VERSION ""

NS_ :

BS_:

BU_: WPC2 RLPSU DPSU PSB SHVU_RR APSU FCS EMCU SLB RCM ARS CGW_CCU ATS RLHV SGU PFSU ALBCU DSAU SWRC SHVU_FR RCS RRPSU BLTN_CAM SCM DLBCU OHCL RWPC RRHV WPC HOD ASAU

BO_ 799 SBCM_DRV_01_200ms: 8 CGW_CCU
 SG_ SBCM_DRV_Crc1Val : 0|8@1+ (1,0) [0|0] ""  Vector__XXX
 SG_ DRV_CrashUnlockCmd : 10|1@1+ (1,0) [0|0] ""  BLTN_CAM
 SG_ C_ApprOpenStatus : 11|1@1+ (1,0) [0|0] ""  Vector__XXX
 SG_ SBCM_DRV_AlvCnt1Val : 12|4@1+ (1,0) [0|0] ""  Vector__XXX
 SG_ DoorLock_DrvKeyLkSwSta_SBCM : 16|2@1+ (1,0) [0|0] ""  Vector__XXX
 SG_ DoorLock_DrvKeyUnLkSwSta_SBCM : 18|2@1+ (1,0) [0|0] ""  Vector__XXX
 SG_ Warn_DrvDrSwSta_SBCM : 20|2@1+ (1,0) [0|0] ""  WPC,RWPC,DPSU,ATS,BLTN_CAM,WPC2
 SG_ DoorLock_DrvDrUnLkSta_SBCM : 22|2@1+ (1,0) [0|0] ""  DPSU,ATS
 SG_ DRV_SEAWarn_LH : 24|2@1+ (1,0) [0|0] ""  Vector__XXX
 SG_ DRV_SEAWarn_RH : 26|2@1+ (1,0) [0|0] ""  Vector__XXX
 SG_ DRV_SEWWarn_LH : 28|2@1+ (1,0) [0|0] ""  Vector__XXX
 SG_ DRV_SEWWarn_RH : 30|2@1+ (1,0) [0|0] ""  Vector__XXX
 SG_ DRV_MRActivationAlarm : 32|2@1+ (1,0) [0|0] ""  Vector__XXX
 SG_ DRV_ReleaseWarn : 34|2@1+ (1,0) [0|0] ""  Vector__XXX
 SG_ Latch_TypeOption_DRV : 36|2@1+ (1,0) [0|0] ""  Vector__XXX
 SG_ DRV_SWFailAlarm : 38|2@1+ (1,0) [0|0] ""  Vector__XXX
 SG_ USM_PwrDRApprOpnSetSta : 40|2@1+ (1,0) [0|0] ""  Vector__XXX
 SG_ USM_PwrDRApprOpnSetOpt : 42|2@1+ (1,0) [0|0] ""  Vector__XXX
 SG_ USM_PwrDRCloseByRKELockSta : 44|2@1+ (1,0) [0|0] ""  Vector__XXX
 SG_ USM_PwrDRCloseByRKELockOpt : 46|2@1+ (1,0) [0|0] ""  Vector__XXX
 SG_ USM_PwrDRCloseByBrakeSta : 48|2@1+ (1,0) [0|0] ""  Vector__XXX
 SG_ USM_PwrDRCloseByBrakeOpt : 50|2@1+ (1,0) [0|0] ""  Vector__XXX
 SG_ USM_PwrDRBuzzerSta : 52|2@1+ (1,0) [0|0] ""  Vector__XXX
 SG_ USM_PwrDRBuzzerOpt : 54|2@1+ (1,0) [0|0] ""  Vector__XXX
 SG_ PDS_TypeOption_DRV : 56|2@1+ (1,0) [0|0] ""  Vector__XXX
 SG_ C_DrvDoorApproachOpen : 58|2@1+ (1,0) [0|0] ""  Vector__XXX
 SG_ C_DrvDoorApproachClose : 60|2@1+ (1,0) [0|0] ""  Vector__XXX
 SG_ DoorLock_PDSLkSwSta_DRV : 62|2@1+ (1,0) [0|0] ""  Vector__XXX
 SG_ DRVDoorPushAlarm : 8|2@1+ (1,0) [0|0] ""  Vector__XXX

BO_ 858 SBCM_AST_02_200ms: 8 CGW_CCU
 SG_ SBCM_AST_Crc2Val : 0|8@1+ (1,0) [0|0] ""  Vector__XXX
 SG_ AST_CrashUnlockCmd : 10|1@1+ (1,0) [0|0] ""  BLTN_CAM
 SG_ SBCM_AST_AlvCnt2Val : 12|4@1+ (1,0) [0|0] ""  Vector__XXX
 SG_ DoorLock_CtrlDrLkSwSta_SBCM : 16|2@1+ (1,0) [0|0] ""  Vector__XXX
 SG_ DoorLock_CtrlDrUnLkSwSta_SBCM : 18|2@1+ (1,0) [0|0] ""  Vector__XXX
 SG_ Warn_AsstDrSwSta_SBCM : 20|2@1+ (1,0) [0|0] ""  WPC,RWPC,APSU,ATS,BLTN_CAM,ALBCU,WPC2
 SG_ DoorLock_AsstDrUnLkSta_SBCM : 22|2@1+ (1,0) [0|0] ""  ATS
 SG_ AST_SEAWarn_RH : 24|2@1+ (1,0) [0|0] ""  Vector__XXX
 SG_ AST_SEAWarn_LH : 26|2@1+ (1,0) [0|0] ""  Vector__XXX
 SG_ AST_SEWWarn_LH : 28|2@1+ (1,0) [0|0] ""  Vector__XXX
 SG_ AST_SEWWarn_RH : 30|2@1+ (1,0) [0|0] ""  Vector__XXX
 SG_ AST_MRActivationAlarm : 32|2@1+ (1,0) [0|0] ""  Vector__XXX
 SG_ AST_ReleaseWarn : 34|2@1+ (1,0) [0|0] ""  Vector__XXX
 SG_ USM_AstGhostDoorSta : 36|2@1+ (1,0) [0|0] ""  Vector__XXX
 SG_ AST_SWFailAlarm : 38|2@1+ (1,0) [0|0] ""  Vector__XXX
 SG_ DoorLock_PDSLkSwSta_AST : 40|2@1+ (1,0) [0|0] ""  Vector__XXX
 SG_ PDS_TypeOption_AST : 42|2@1+ (1,0) [0|0] ""  Vector__XXX
 SG_ AFCU_AutoWashModeSta_SBCM_AST : 56|3@1+ (1,0) [0|0] ""  Vector__XXX
 SG_ CDM_AutoWashModeSta_SBCM_AST : 59|3@1+ (1,0) [0|0] ""  Vector__XXX
 SG_ ASTDoorPushAlarm : 8|2@1+ (1,0) [0|0] ""  Vector__XXX

BO_ 1193 HU_USM_E_02: 8 CGW_CCU
 SG_ C_PTGMNValueSet : 0|2@1+ (1,0) [0|0] ""  Vector__XXX
 SG_ CF_AVN_PSMNValueSet : 10|3@1+ (1,0) [0|0] ""  DPSU
 SG_ C_HfreeTrunkTgNValueSet : 13|3@1+ (1,0) [0|0] ""  Vector__XXX
 SG_ CF_AVN_TrfChgSet : 17|2@1+ (1,0) [0|0] ""  Vector__XXX
 SG_ CF_AVN_SCMNValueSet : 19|2@1+ (1,0) [0|0] ""  Vector__XXX
 SG_ CF_AVN_ADrUNValueSet : 2|3@1+ (1,0) [0|0] ""  Vector__XXX
 SG_ CF_AVN_OTTurnNValueSet : 21|3@1+ (1,0) [0|0] ""  Vector__XXX
 SG_ CF_Gway_WPCNValueSet : 24|2@1+ (1,0) [0|0] ""  WPC,WPC2
 SG_ C_AVN_RearWiperNValueSet : 26|2@1+ (1,0) [0|0] ""  Vector__XXX
 SG_ C_UnlockWelocomeNValueSet : 28|2@1+ (1,0) [0|0] ""  Vector__XXX
 SG_ C_SmartWelocomeNValueSet : 30|2@1+ (1,0) [0|0] ""  Vector__XXX
 SG_ CF_AVN_PTGSpeedNValueSet : 32|2@1+ (1,0) [0|0] ""  Vector__XXX
 SG_ CR_Datc_DRSeatWheel_USM_Set : 34|2@1+ (1,0) [0|0] ""  Vector__XXX
 SG_ CF_AVN_TTUnlockNValueSet : 38|2@1+ (1,0) [0|0] ""  Vector__XXX
 SG_ CF_Gway_RWPCNValueSet : 40|2@1+ (1,0) [0|0] ""  RWPC
 SG_ CF_Avn_HAPTICWARNINGNValueSet : 49|3@1+ (1,0) [0|0] ""  Vector__XXX
 SG_ CR_Datc_DRSeatHeat_USM_Set : 52|2@1+ (1,0) [0|0] ""  Vector__XXX
 SG_ C_WALNValueSet : 54|2@1+ (1,0) [0|0] ""  Vector__XXX
 SG_ C_ApprUnlockNValue : 56|2@1+ (1,0) [0|0] ""  Vector__XXX
 SG_ CF_AVN_EscortHLNValueSet : 8|2@1+ (1,0) [0|0] ""  Vector__XXX

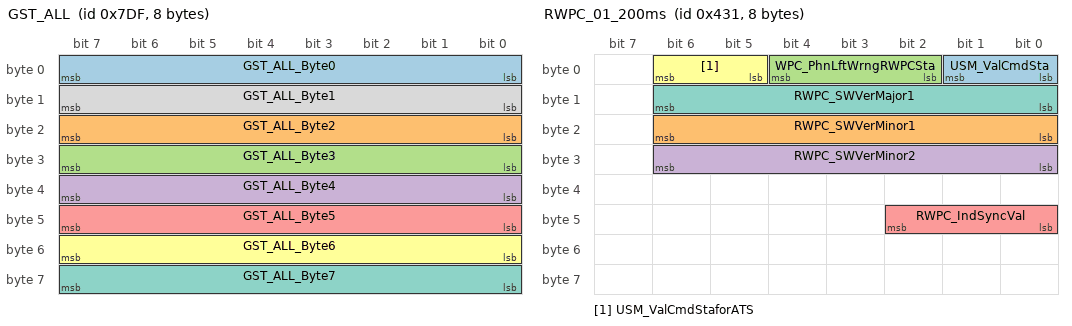
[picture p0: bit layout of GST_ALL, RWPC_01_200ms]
BO_ 2015 GST_ALL: 8 CGW_CCU
 SG_ GST_ALL_Byte0 : 0|8@1+ (1,0) [0|0] ""  FCS,SCM,WPC,RWPC,PSB,SLB,ARS,SWRC,APSU,RLHV,RRHV,SHVU_FR,SHVU_RR,DPSU,DLBCU,PFSU,RCS,RRPSU,RLPSU,HOD,ATS,DSAU,ASAU,RCM,EMCU,SGU,ALBCU,WPC2
 SG_ GST_ALL_Byte2 : 16|8@1+ (1,0) [0|0] ""  FCS,SCM,WPC,RWPC,PSB,SLB,ARS,SWRC,APSU,RLHV,RRHV,SHVU_FR,SHVU_RR,DPSU,DLBCU,PFSU,RCS,RRPSU,RLPSU,HOD,ATS,DSAU,ASAU,RCM,EMCU,SGU,ALBCU,WPC2
 SG_ GST_ALL_Byte3 : 24|8@1+ (1,0) [0|0] ""  FCS,SCM,WPC,RWPC,PSB,SLB,ARS,SWRC,APSU,RLHV,RRHV,SHVU_FR,SHVU_RR,DPSU,DLBCU,PFSU,RCS,RRPSU,RLPSU,HOD,ATS,DSAU,ASAU,RCM,EMCU,SGU,ALBCU,WPC2
 SG_ GST_ALL_Byte4 : 32|8@1+ (1,0) [0|0] ""  FCS,SCM,WPC,RWPC,PSB,SLB,ARS,SWRC,APSU,RLHV,RRHV,SHVU_FR,SHVU_RR,DPSU,DLBCU,PFSU,RCS,RRPSU,RLPSU,HOD,ATS,DSAU,ASAU,RCM,EMCU,SGU,ALBCU,WPC2
 SG_ GST_ALL_Byte5 : 40|8@1+ (1,0) [0|0] ""  FCS,SCM,WPC,RWPC,PSB,SLB,ARS,SWRC,APSU,RLHV,RRHV,SHVU_FR,SHVU_RR,DPSU,DLBCU,PFSU,RCS,RRPSU,RLPSU,HOD,ATS,DSAU,ASAU,RCM,EMCU,SGU,ALBCU,WPC2
 SG_ GST_ALL_Byte6 : 48|8@1+ (1,0) [0|0] ""  FCS,SCM,WPC,RWPC,PSB,SLB,ARS,SWRC,APSU,RLHV,RRHV,SHVU_FR,SHVU_RR,DPSU,DLBCU,PFSU,RCS,RRPSU,RLPSU,HOD,ATS,DSAU,ASAU,RCM,EMCU,SGU,ALBCU,WPC2
 SG_ GST_ALL_Byte7 : 56|8@1+ (1,0) [0|0] ""  FCS,SCM,WPC,RWPC,PSB,SLB,ARS,SWRC,APSU,RLHV,RRHV,SHVU_FR,SHVU_RR,DPSU,DLBCU,PFSU,RCS,RRPSU,RLPSU,HOD,ATS,DSAU,ASAU,RCM,EMCU,SGU,ALBCU,WPC2
 SG_ GST_ALL_Byte1 : 8|8@1+ (1,0) [0|0] ""  FCS,SCM,WPC,RWPC,PSB,SLB,ARS,SWRC,APSU,RLHV,RRHV,SHVU_FR,SHVU_RR,DPSU,DLBCU,PFSU,RCS,RRPSU,RLPSU,HOD,ATS,DSAU,ASAU,RCM,EMCU,SGU,ALBCU,WPC2

BO_ 862 SBCM_RL_01_200ms: 8 CGW_CCU
 SG_ SBCM_RL_Crc1Val : 0|8@1+ (1,0) [0|0] ""  Vector__XXX
 SG_ RL_CrashUnlockCmd : 10|1@1+ (1,0) [0|0] ""  BLTN_CAM
 SG_ SBCM_RL_AlvCnt1Val : 12|4@1+ (1,0) [0|0] ""  Vector__XXX
 SG_ Warn_RrLftDrSwSta_SBCM : 16|2@1+ (1,0) [0|0] ""  WPC,RWPC,APSU,ATS,BLTN_CAM,WPC2
 SG_ DoorLock_RrLftDrUnLkSta_SBCM : 18|2@1+ (1,0) [0|0] ""  ATS
 SG_ RL_SEAActivated : 20|2@1+ (1,0) [0|0] ""  Vector__XXX
 SG_ RL_SEAWarn : 22|2@1+ (1,0) [0|0] ""  Vector__XXX
 SG_ RL_SEWWarn : 24|2@1+ (1,0) [0|0] ""  Vector__XXX
 SG_ RL_ReleaseWarn : 26|2@1+ (1,0) [0|0] ""  Vector__XXX
 SG_ RL_SWFailAlarm : 28|2@1+ (1,0) [0|0] ""  Vector__XXX
 SG_ RL_ChildLock_ActnFlSta : 30|2@1+ (1,0) [0|0] ""  Vector__XXX
 SG_ RL_MRActivationAlarm : 32|2@1+ (1,0) [0|0] ""  Vector__XXX
 SG_ RL_ChildLock_Status : 34|2@1+ (1,0) [0|0] ""  Vector__XXX
 SG_ USM_RLGhostDoorSta : 36|2@1+ (1,0) [0|0] ""  Vector__XXX
 SG_ DoorLock_PDSLkSwSta_RL : 40|2@1+ (1,0) [0|0] ""  Vector__XXX
 SG_ PDS_TypeOption_RL : 42|2@1+ (1,0) [0|0] ""  Vector__XXX
 SG_ RLDoorPushAlarm : 8|2@1+ (1,0) [0|0] ""  Vector__XXX

BO_ 491 HU_USM_E_14: 8 CGW_CCU
 SG_ CF_AVN_Roof_OprLvSet : 0|3@1+ (1,0) [0|0] ""  SGU
 SG_ CF_AVN_3rdRightDoor_OptLvlSet : 12|3@1+ (1,0) [0|0] ""  SGU
 SG_ CF_AVN_RearDoor_OptLvlSet : 15|3@1+ (1,0) [0|0] ""  SGU
 SG_ CF_AVN_RollBlindOnOffSet : 18|2@1+ (1,0) [0|0] ""  SGU
 SG_ CF_AVN_CluThmAutoSet_New : 20|2@1+ (1,0) [0|0] ""  Vector__XXX
 SG_ CF_AVN_CluThmSet_New : 22|3@1+ (1,0) [0|0] ""  Vector__XXX
 SG_ CF_AVN_CluThmDtlSet_New : 25|3@1+ (1,0) [0|0] ""  Vector__XXX
 SG_ CF_AVN_MdLmpAIVoiceUSMNValueSet : 28|2@1+ (1,0) [0|0] ""  Vector__XXX
 SG_ CF_AVN_2ndLeftDoor_OptLvSet : 3|3@1+ (1,0) [0|0] ""  SGU
 SG_ CF_AVN_DWL_SelectNvalueSet : 30|4@1+ (1,0) [0|0] ""  Vector__XXX
 SG_ CF_AVN_FrArmRestHeatNValueSet : 36|2@1+ (1,0) [0|0] ""  FCS
 SG_ CF_AVN_RrArmRestHeatNValueSet : 38|2@1+ (1,0) [0|0] ""  FCS
 SG_ CF_Gway_WPCAnimationNvalueSet : 40|3@1+ (1,0) [0|0] ""  WPC
 SG_ USM_BtnIllumiAlwaysOnReq : 49|2@1+ (1,0) [0|0] ""  Vector__XXX
 SG_ CF_AVN_LKAWrngVolNvalueSet : 51|2@1+ (1,0) [0|0] ""  Vector__XXX
 SG_ DAB_IlluminationVrModeSet : 53|3@1+ (1,0) [0|0] ""  SWRC
 SG_ USM_IllAlwaysOnwithPSTNReq : 56|3@1+ (1,0) [0|0] ""  Vector__XXX
 SG_ CF_AVN_AutoStopTimerResetSet : 59|3@1+ (1,0) [0|0] ""  Vector__XXX
 SG_ CF_AVN_2ndRightDoor_OptLvSet : 6|3@1+ (1,0) [0|0] ""  SGU
 SG_ USM_RrCurtainSet : 62|2@1+ (1,0) [0|0] ""  Vector__XXX
 SG_ CF_AVN_3rdLeftDoor_OptLvlSet : 9|3@1+ (1,0) [0|0] ""  SGU

BO_ 905 SBCM_RR_01_200ms: 8 CGW_CCU
 SG_ SBCM_RR_Crc1Val : 0|8@1+ (1,0) [0|0] ""  Vector__XXX
 SG_ RR_CrashUnlockCmd : 10|1@1+ (1,0) [0|0] ""  BLTN_CAM
 SG_ SBCM_RR_AlvCnt1Val : 12|4@1+ (1,0) [0|0] ""  Vector__XXX
 SG_ Warn_RrRtDrSwSta_SBCM : 16|2@1+ (1,0) [0|0] ""  WPC,RWPC,APSU,RRPSU,ATS,BLTN_CAM,WPC2
 SG_ DoorLock_RrRtDrUnLkSta_SBCM : 18|2@1+ (1,0) [0|0] ""  ATS
 SG_ RR_SEAActivated : 20|2@1+ (1,0) [0|0] ""  Vector__XXX
 SG_ RR_SEAWarn : 22|2@1+ (1,0) [0|0] ""  Vector__XXX
 SG_ RR_SEWWarn : 24|2@1+ (1,0) [0|0] ""  Vector__XXX
 SG_ RR_ReleaseWarn : 26|2@1+ (1,0) [0|0] ""  Vector__XXX
 SG_ RR_SWFailAlarm : 28|2@1+ (1,0) [0|0] ""  Vector__XXX
 SG_ RR_ChildLock_ActnFlSta : 30|2@1+ (1,0) [0|0] ""  Vector__XXX
 SG_ RR_MRActivationAlarm : 32|2@1+ (1,0) [0|0] ""  Vector__XXX
 SG_ RR_ChildLock_Status : 34|2@1+ (1,0) [0|0] ""  Vector__XXX
 SG_ USM_RRGhostDoorSta : 36|2@1+ (1,0) [0|0] ""  Vector__XXX
 SG_ DoorLock_PDSLkSwSta_RR : 40|2@1+ (1,0) [0|0] ""  Vector__XXX
 SG_ PDS_TypeOption_RR : 42|2@1+ (1,0) [0|0] ""  Vector__XXX
 SG_ RRDoorPushAlarm : 8|2@1+ (1,0) [0|0] ""  Vector__XXX

BO_ 1073 RWPC_01_200ms: 8 RWPC
 SG_ USM_ValCmdSta : 0|2@1+ (1,0) [0|0] ""  ATS,CGW_CCU
 SG_ RWPC_SWVerMinor1 : 16|7@1+ (1,0) [0|0] ""  CGW_CCU
 SG_ WPC_PhnLftWrngRWPCSta : 2|3@1+ (1,0) [0|0] ""  ATS,CGW_CCU
 SG_ RWPC_SWVerMinor2 : 24|7@1+ (1,0) [0|0] ""  CGW_CCU
 SG_ RWPC_IndSyncVal : 40|3@1+ (1,0) [0|0] ""  WPC,WPC2
 SG_ USM_ValCmdStaforATS : 5|2@1+ (1,0) [0|0] ""  ATS
 SG_ RWPC_SWVerMajor1 : 8|7@1+ (1,0) [0|0] ""  CGW_CCU

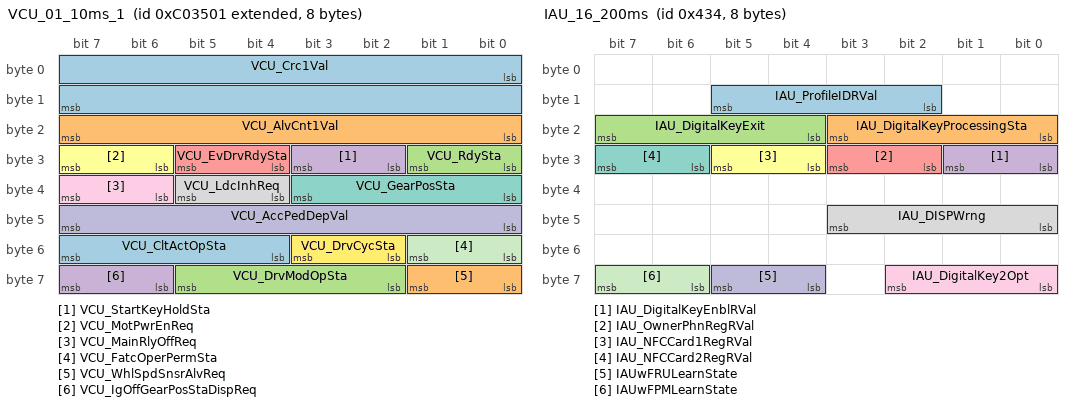
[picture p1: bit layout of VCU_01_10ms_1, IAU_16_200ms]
BO_ 2160080129 VCU_01_10ms_1: 8 CGW_CCU
 SG_ VCU_Crc1Val : 0|16@1+ (1,0) [0|0] ""  Vector__XXX
 SG_ VCU_AlvCnt1Val : 16|8@1+ (1,0) [0|0] ""  Vector__XXX
 SG_ VCU_RdySta : 24|2@1+ (1,0) [0|3] ""  Vector__XXX
 SG_ VCU_StartKeyHoldSta : 26|2@1+ (1,0) [0|3] ""  Vector__XXX
 SG_ VCU_EvDrvRdySta : 28|2@1+ (1,0) [0|3] ""  SCM,WPC,RWPC,SWRC,APSU,RLHV,RRHV,SHVU_FR,SHVU_RR,DPSU,DLBCU,PFSU,RRPSU,RLPSU,HOD,RCM,BLTN_CAM,WPC2
 SG_ VCU_MotPwrEnReq : 30|2@1+ (1,0) [0|3] ""  Vector__XXX
 SG_ VCU_GearPosSta : 32|4@1+ (1,0) [0|15] ""  APSU,DPSU,PFSU,RRPSU,RLPSU,BLTN_CAM,SGU,WPC2
 SG_ VCU_LdcInhReq : 36|2@1+ (1,0) [0|3] ""  Vector__XXX
 SG_ VCU_MainRlyOffReq : 38|2@1+ (1,0) [0|3] ""  Vector__XXX
 SG_ VCU_AccPedDepVal : 40|8@1+ (0.3921568627,0) [0|100] "%"  BLTN_CAM
 SG_ VCU_FatcOperPermSta : 48|2@1+ (1,0) [0|3] ""  Vector__XXX
 SG_ VCU_DrvCycSta : 50|2@1+ (1,0) [0|3] ""  Vector__XXX
 SG_ VCU_CltActOpSta : 52|4@1+ (1,0) [0|15] ""  Vector__XXX
 SG_ VCU_WhlSpdSnsrAlvReq : 56|2@1+ (1,0) [0|0] "flag"  Vector__XXX
 SG_ VCU_DrvModOpSta : 58|4@1+ (1,0) [0|0] ""  Vector__XXX
 SG_ VCU_IgOffGearPosStaDispReq : 62|2@1+ (1,0) [0|0] "flag"  Vector__XXX

BO_ 1076 IAU_16_200ms: 8 CGW_CCU
 SG_ IAU_ProfileIDRVal : 10|4@1+ (1,0) [0|0] ""  WPC,RWPC,DPSU,DLBCU,RCM,BLTN_CAM,SGU,WPC2
 SG_ IAU_DigitalKeyProcessingSta : 16|4@1+ (1,0) [0|0] ""  Vector__XXX
 SG_ IAU_DigitalKeyExit : 20|4@1+ (1,0) [0|0] ""  Vector__XXX
 SG_ IAU_DigitalKeyEnblRVal : 24|2@1+ (1,0) [0|0] ""  Vector__XXX
 SG_ IAU_OwnerPhnRegRVal : 26|2@1+ (1,0) [0|0] ""  Vector__XXX
 SG_ IAU_NFCCard1RegRVal : 28|2@1+ (1,0) [0|0] ""  Vector__XXX
 SG_ IAU_NFCCard2RegRVal : 30|2@1+ (1,0) [0|0] ""  Vector__XXX
 SG_ IAU_DISPWrng : 40|4@1+ (1,0) [0|0] ""  Vector__XXX
 SG_ IAU_DigitalKey2Opt : 56|3@1+ (1,0) [0|0] ""  WPC,WPC2
 SG_ IAUwFRULearnState : 60|2@1+ (1,0) [0|0] ""  Vector__XXX
 SG_ IAUwFPMLearnState : 62|2@1+ (1,0) [0|0] ""  Vector__XXX

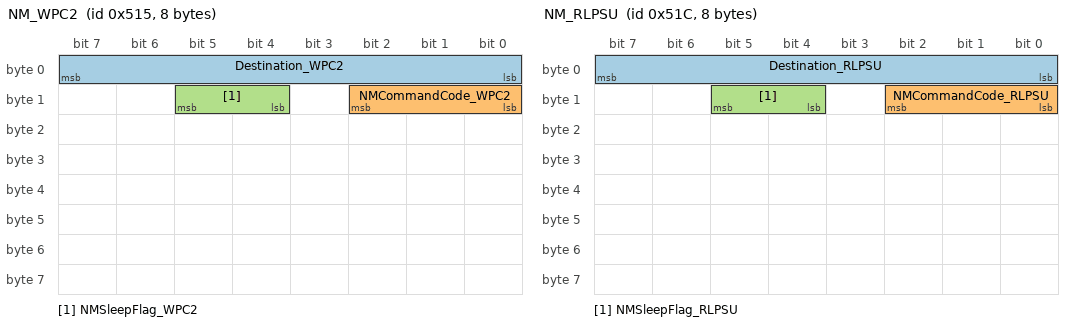
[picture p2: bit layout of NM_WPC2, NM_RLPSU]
BO_ 1301 NM_WPC2: 8 WPC2
 SG_ Destination_WPC2 : 0|8@1+ (1,0) [0|0] ""  RLPSU,DPSU,PSB,SHVU_RR,APSU,FCS,EMCU,SLB,RCM,ARS,CGW_CCU,ATS,RLHV,SGU,PFSU,ALBCU,DSAU,SWRC,SHVU_FR,RCS,RRPSU,BLTN_CAM,SCM,DLBCU,OHCL,RWPC,RRHV,WPC,HOD,ASAU
 SG_ NMCommandCode_WPC2 : 8|3@1+ (1,0) [0|0] ""  RLPSU,DPSU,PSB,SHVU_RR,APSU,FCS,EMCU,SLB,RCM,ARS,CGW_CCU,ATS,RLHV,SGU,PFSU,ALBCU,DSAU,SWRC,SHVU_FR,RCS,RRPSU,BLTN_CAM,SCM,DLBCU,OHCL,RWPC,RRHV,WPC,HOD,ASAU
 SG_ NMSleepFlag_WPC2 : 12|2@1+ (1,0) [0|0] ""  RLPSU,DPSU,PSB,SHVU_RR,APSU,FCS,EMCU,SLB,RCM,ARS,CGW_CCU,ATS,RLHV,SGU,PFSU,ALBCU,DSAU,SWRC,SHVU_FR,RCS,RRPSU,BLTN_CAM,SCM,DLBCU,OHCL,RWPC,RRHV,WPC,HOD,ASAU

BO_ 1308 NM_RLPSU: 8 RLPSU
 SG_ Destination_RLPSU : 0|8@1+ (1,0) [0|0] ""  WPC2,DPSU,PSB,SHVU_RR,APSU,FCS,EMCU,SLB,RCM,ARS,CGW_CCU,ATS,RLHV,SGU,PFSU,ALBCU,DSAU,SWRC,SHVU_FR,RCS,RRPSU,BLTN_CAM,SCM,DLBCU,OHCL,RWPC,RRHV,WPC,HOD,ASAU
 SG_ NMCommandCode_RLPSU : 8|3@1+ (1,0) [0|0] ""  WPC2,DPSU,PSB,SHVU_RR,APSU,FCS,EMCU,SLB,RCM,ARS,CGW_CCU,ATS,RLHV,SGU,PFSU,ALBCU,DSAU,SWRC,SHVU_FR,RCS,RRPSU,BLTN_CAM,SCM,DLBCU,OHCL,RWPC,RRHV,WPC,HOD,ASAU
 SG_ NMSleepFlag_RLPSU : 12|2@1+ (1,0) [0|0] ""  WPC2,DPSU,PSB,SHVU_RR,APSU,FCS,EMCU,SLB,RCM,ARS,CGW_CCU,ATS,RLHV,SGU,PFSU,ALBCU,DSAU,SWRC,SHVU_FR,RCS,RRPSU,BLTN_CAM,SCM,DLBCU,OHCL,RWPC,RRHV,WPC,HOD,ASAU

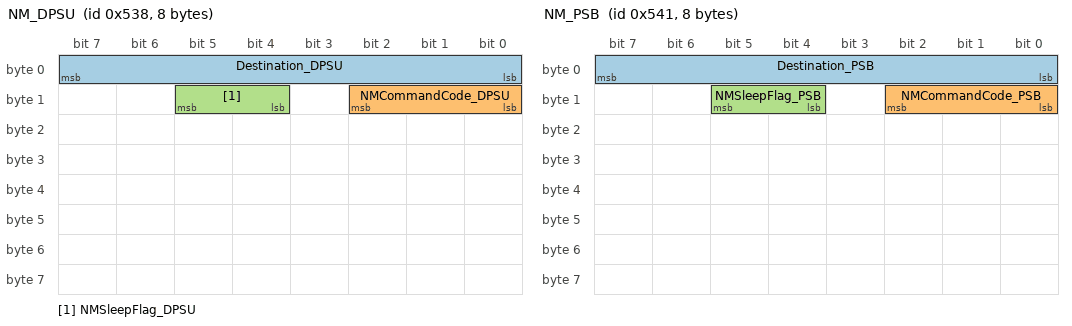
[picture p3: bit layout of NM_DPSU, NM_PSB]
BO_ 1336 NM_DPSU: 8 DPSU
 SG_ Destination_DPSU : 0|8@1+ (1,0) [0|0] ""  WPC2,RLPSU,PSB,SHVU_RR,APSU,FCS,EMCU,SLB,RCM,ARS,CGW_CCU,ATS,RLHV,SGU,PFSU,ALBCU,DSAU,SWRC,SHVU_FR,RCS,RRPSU,BLTN_CAM,SCM,DLBCU,OHCL,RWPC,RRHV,WPC,HOD,ASAU
 SG_ NMCommandCode_DPSU : 8|3@1+ (1,0) [0|0] ""  WPC2,RLPSU,PSB,SHVU_RR,APSU,FCS,EMCU,SLB,RCM,ARS,CGW_CCU,ATS,RLHV,SGU,PFSU,ALBCU,DSAU,SWRC,SHVU_FR,RCS,RRPSU,BLTN_CAM,SCM,DLBCU,OHCL,RWPC,RRHV,WPC,HOD,ASAU
 SG_ NMSleepFlag_DPSU : 12|2@1+ (1,0) [0|0] ""  WPC2,RLPSU,PSB,SHVU_RR,APSU,FCS,EMCU,SLB,RCM,ARS,CGW_CCU,ATS,RLHV,SGU,PFSU,ALBCU,DSAU,SWRC,SHVU_FR,RCS,RRPSU,BLTN_CAM,SCM,DLBCU,OHCL,RWPC,RRHV,WPC,HOD,ASAU

BO_ 1345 NM_PSB: 8 PSB
 SG_ Destination_PSB : 0|8@1+ (1,0) [0|0] ""  WPC2,RLPSU,DPSU,SHVU_RR,APSU,FCS,EMCU,SLB,RCM,ARS,CGW_CCU,ATS,RLHV,SGU,PFSU,ALBCU,DSAU,SWRC,SHVU_FR,RCS,RRPSU,BLTN_CAM,SCM,DLBCU,OHCL,RWPC,RRHV,WPC,HOD,ASAU
 SG_ NMCommandCode_PSB : 8|3@1+ (1,0) [0|0] ""  WPC2,RLPSU,DPSU,SHVU_RR,APSU,FCS,EMCU,SLB,RCM,ARS,CGW_CCU,ATS,RLHV,SGU,PFSU,ALBCU,DSAU,SWRC,SHVU_FR,RCS,RRPSU,BLTN_CAM,SCM,DLBCU,OHCL,RWPC,RRHV,WPC,HOD,ASAU
 SG_ NMSleepFlag_PSB : 12|2@1+ (1,0) [0|0] ""  WPC2,RLPSU,DPSU,SHVU_RR,APSU,FCS,EMCU,SLB,RCM,ARS,CGW_CCU,ATS,RLHV,SGU,PFSU,ALBCU,DSAU,SWRC,SHVU_FR,RCS,RRPSU,BLTN_CAM,SCM,DLBCU,OHCL,RWPC,RRHV,WPC,HOD,ASAU

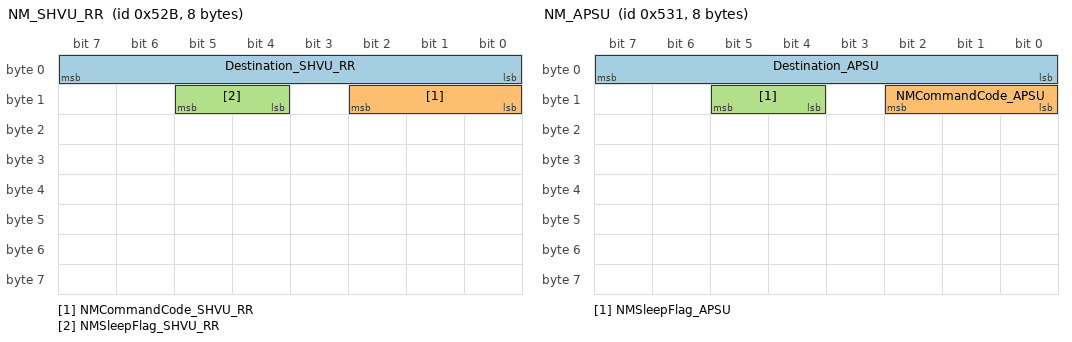
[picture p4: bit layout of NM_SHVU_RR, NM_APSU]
BO_ 1323 NM_SHVU_RR: 8 SHVU_RR
 SG_ Destination_SHVU_RR : 0|8@1+ (1,0) [0|0] ""  WPC2,RLPSU,DPSU,PSB,APSU,FCS,EMCU,SLB,RCM,ARS,CGW_CCU,ATS,RLHV,SGU,PFSU,ALBCU,DSAU,SWRC,SHVU_FR,RCS,RRPSU,BLTN_CAM,SCM,DLBCU,OHCL,RWPC,RRHV,WPC,HOD,ASAU
 SG_ NMCommandCode_SHVU_RR : 8|3@1+ (1,0) [0|0] ""  WPC2,RLPSU,DPSU,PSB,APSU,FCS,EMCU,SLB,RCM,ARS,CGW_CCU,ATS,RLHV,SGU,PFSU,ALBCU,DSAU,SWRC,SHVU_FR,RCS,RRPSU,BLTN_CAM,SCM,DLBCU,OHCL,RWPC,RRHV,WPC,HOD,ASAU
 SG_ NMSleepFlag_SHVU_RR : 12|2@1+ (1,0) [0|0] ""  WPC2,RLPSU,DPSU,PSB,APSU,FCS,EMCU,SLB,RCM,ARS,CGW_CCU,ATS,RLHV,SGU,PFSU,ALBCU,DSAU,SWRC,SHVU_FR,RCS,RRPSU,BLTN_CAM,SCM,DLBCU,OHCL,RWPC,RRHV,WPC,HOD,ASAU

BO_ 1329 NM_APSU: 8 APSU
 SG_ Destination_APSU : 0|8@1+ (1,0) [0|0] ""  WPC2,RLPSU,DPSU,PSB,SHVU_RR,FCS,EMCU,SLB,RCM,ARS,CGW_CCU,ATS,RLHV,SGU,PFSU,ALBCU,DSAU,SWRC,SHVU_FR,RCS,RRPSU,BLTN_CAM,SCM,DLBCU,OHCL,RWPC,RRHV,WPC,HOD,ASAU
 SG_ NMCommandCode_APSU : 8|3@1+ (1,0) [0|0] ""  WPC2,RLPSU,DPSU,PSB,SHVU_RR,FCS,EMCU,SLB,RCM,ARS,CGW_CCU,ATS,RLHV,SGU,PFSU,ALBCU,DSAU,SWRC,SHVU_FR,RCS,RRPSU,BLTN_CAM,SCM,DLBCU,OHCL,RWPC,RRHV,WPC,HOD,ASAU
 SG_ NMSleepFlag_APSU : 12|2@1+ (1,0) [0|0] ""  WPC2,RLPSU,DPSU,PSB,SHVU_RR,FCS,EMCU,SLB,RCM,ARS,CGW_CCU,ATS,RLHV,SGU,PFSU,ALBCU,DSAU,SWRC,SHVU_FR,RCS,RRPSU,BLTN_CAM,SCM,DLBCU,OHCL,RWPC,RRHV,WPC,HOD,ASAU

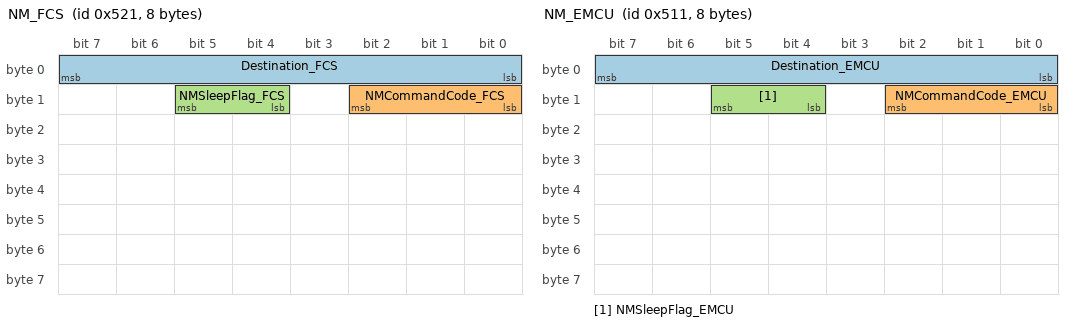
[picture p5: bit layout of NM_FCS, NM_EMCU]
BO_ 1313 NM_FCS: 8 FCS
 SG_ Destination_FCS : 0|8@1+ (1,0) [0|0] ""  WPC2,RLPSU,DPSU,PSB,SHVU_RR,APSU,EMCU,SLB,RCM,ARS,CGW_CCU,ATS,RLHV,SGU,PFSU,ALBCU,DSAU,SWRC,SHVU_FR,RCS,RRPSU,BLTN_CAM,SCM,DLBCU,OHCL,RWPC,RRHV,WPC,HOD,ASAU
 SG_ NMCommandCode_FCS : 8|3@1+ (1,0) [0|0] ""  WPC2,RLPSU,DPSU,PSB,SHVU_RR,APSU,EMCU,SLB,RCM,ARS,CGW_CCU,ATS,RLHV,SGU,PFSU,ALBCU,DSAU,SWRC,SHVU_FR,RCS,RRPSU,BLTN_CAM,SCM,DLBCU,OHCL,RWPC,RRHV,WPC,HOD,ASAU
 SG_ NMSleepFlag_FCS : 12|2@1+ (1,0) [0|0] ""  WPC2,RLPSU,DPSU,PSB,SHVU_RR,APSU,EMCU,SLB,RCM,ARS,CGW_CCU,ATS,RLHV,SGU,PFSU,ALBCU,DSAU,SWRC,SHVU_FR,RCS,RRPSU,BLTN_CAM,SCM,DLBCU,OHCL,RWPC,RRHV,WPC,HOD,ASAU

BO_ 1297 NM_EMCU: 8 EMCU
 SG_ Destination_EMCU : 0|8@1+ (1,0) [0|0] ""  WPC2,RLPSU,DPSU,PSB,SHVU_RR,APSU,FCS,SLB,RCM,ARS,CGW_CCU,ATS,RLHV,SGU,PFSU,ALBCU,DSAU,SWRC,SHVU_FR,RCS,RRPSU,BLTN_CAM,SCM,DLBCU,OHCL,RWPC,RRHV,WPC,HOD,ASAU
 SG_ NMCommandCode_EMCU : 8|3@1+ (1,0) [0|0] ""  WPC2,RLPSU,DPSU,PSB,SHVU_RR,APSU,FCS,SLB,RCM,ARS,CGW_CCU,ATS,RLHV,SGU,PFSU,ALBCU,DSAU,SWRC,SHVU_FR,RCS,RRPSU,BLTN_CAM,SCM,DLBCU,OHCL,RWPC,RRHV,WPC,HOD,ASAU
 SG_ NMSleepFlag_EMCU : 12|2@1+ (1,0) [0|0] ""  WPC2,RLPSU,DPSU,PSB,SHVU_RR,APSU,FCS,SLB,RCM,ARS,CGW_CCU,ATS,RLHV,SGU,PFSU,ALBCU,DSAU,SWRC,SHVU_FR,RCS,RRPSU,BLTN_CAM,SCM,DLBCU,OHCL,RWPC,RRHV,WPC,HOD,ASAU

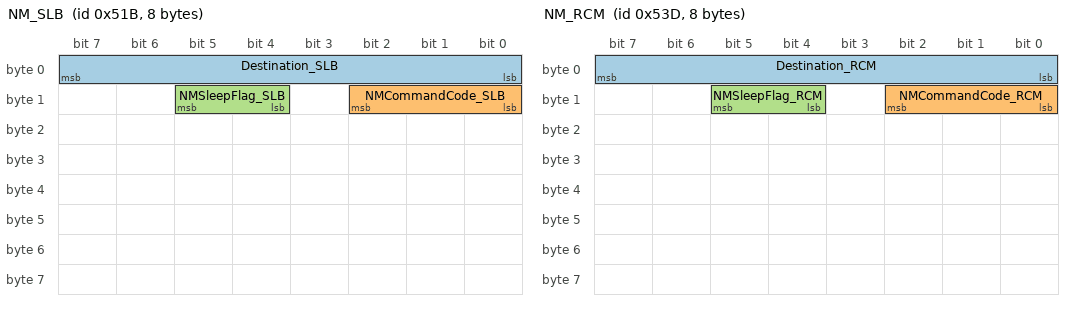
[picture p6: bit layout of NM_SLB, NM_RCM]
BO_ 1307 NM_SLB: 8 SLB
 SG_ Destination_SLB : 0|8@1+ (1,0) [0|0] ""  WPC2,RLPSU,DPSU,PSB,SHVU_RR,APSU,FCS,EMCU,RCM,ARS,CGW_CCU,ATS,RLHV,SGU,PFSU,ALBCU,DSAU,SWRC,SHVU_FR,RCS,RRPSU,BLTN_CAM,SCM,DLBCU,OHCL,RWPC,RRHV,WPC,HOD,ASAU
 SG_ NMCommandCode_SLB : 8|3@1+ (1,0) [0|0] ""  WPC2,RLPSU,DPSU,PSB,SHVU_RR,APSU,FCS,EMCU,RCM,ARS,CGW_CCU,ATS,RLHV,SGU,PFSU,ALBCU,DSAU,SWRC,SHVU_FR,RCS,RRPSU,BLTN_CAM,SCM,DLBCU,OHCL,RWPC,RRHV,WPC,HOD,ASAU
 SG_ NMSleepFlag_SLB : 12|2@1+ (1,0) [0|0] ""  WPC2,RLPSU,DPSU,PSB,SHVU_RR,APSU,FCS,EMCU,RCM,ARS,CGW_CCU,ATS,RLHV,SGU,PFSU,ALBCU,DSAU,SWRC,SHVU_FR,RCS,RRPSU,BLTN_CAM,SCM,DLBCU,OHCL,RWPC,RRHV,WPC,HOD,ASAU

BO_ 1341 NM_RCM: 8 RCM
 SG_ Destination_RCM : 0|8@1+ (1,0) [0|0] ""  WPC2,RLPSU,DPSU,PSB,SHVU_RR,APSU,FCS,EMCU,SLB,ARS,CGW_CCU,ATS,RLHV,SGU,PFSU,ALBCU,DSAU,SWRC,SHVU_FR,RCS,RRPSU,BLTN_CAM,SCM,DLBCU,OHCL,RWPC,RRHV,WPC,HOD,ASAU
 SG_ NMCommandCode_RCM : 8|3@1+ (1,0) [0|0] ""  WPC2,RLPSU,DPSU,PSB,SHVU_RR,APSU,FCS,EMCU,SLB,ARS,CGW_CCU,ATS,RLHV,SGU,PFSU,ALBCU,DSAU,SWRC,SHVU_FR,RCS,RRPSU,BLTN_CAM,SCM,DLBCU,OHCL,RWPC,RRHV,WPC,HOD,ASAU
 SG_ NMSleepFlag_RCM : 12|2@1+ (1,0) [0|0] ""  WPC2,RLPSU,DPSU,PSB,SHVU_RR,APSU,FCS,EMCU,SLB,ARS,CGW_CCU,ATS,RLHV,SGU,PFSU,ALBCU,DSAU,SWRC,SHVU_FR,RCS,RRPSU,BLTN_CAM,SCM,DLBCU,OHCL,RWPC,RRHV,WPC,HOD,ASAU

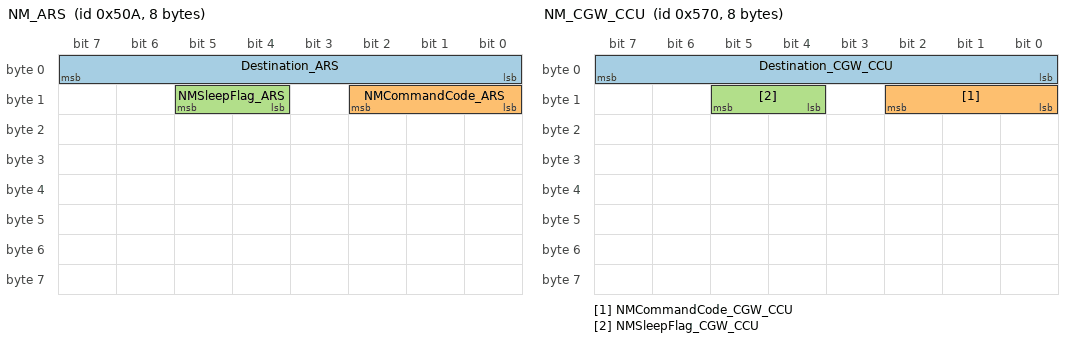
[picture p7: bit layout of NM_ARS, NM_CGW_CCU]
BO_ 1290 NM_ARS: 8 ARS
 SG_ Destination_ARS : 0|8@1+ (1,0) [0|0] ""  WPC2,RLPSU,DPSU,PSB,SHVU_RR,APSU,FCS,EMCU,SLB,RCM,CGW_CCU,ATS,RLHV,SGU,PFSU,ALBCU,DSAU,SWRC,SHVU_FR,RCS,RRPSU,BLTN_CAM,SCM,DLBCU,OHCL,RWPC,RRHV,WPC,HOD,ASAU
 SG_ NMCommandCode_ARS : 8|3@1+ (1,0) [0|0] ""  WPC2,RLPSU,DPSU,PSB,SHVU_RR,APSU,FCS,EMCU,SLB,RCM,CGW_CCU,ATS,RLHV,SGU,PFSU,ALBCU,DSAU,SWRC,SHVU_FR,RCS,RRPSU,BLTN_CAM,SCM,DLBCU,OHCL,RWPC,RRHV,WPC,HOD,ASAU
 SG_ NMSleepFlag_ARS : 12|2@1+ (1,0) [0|0] ""  WPC2,RLPSU,DPSU,PSB,SHVU_RR,APSU,FCS,EMCU,SLB,RCM,CGW_CCU,ATS,RLHV,SGU,PFSU,ALBCU,DSAU,SWRC,SHVU_FR,RCS,RRPSU,BLTN_CAM,SCM,DLBCU,OHCL,RWPC,RRHV,WPC,HOD,ASAU

BO_ 1392 NM_CGW_CCU: 8 CGW_CCU
 SG_ Destination_CGW_CCU : 0|8@1+ (1,0) [0|0] ""  WPC2,RLPSU,DPSU,PSB,SHVU_RR,APSU,FCS,EMCU,SLB,RCM,ARS,ATS,RLHV,SGU,PFSU,ALBCU,DSAU,SWRC,SHVU_FR,RCS,RRPSU,BLTN_CAM,SCM,DLBCU,OHCL,RWPC,RRHV,WPC,HOD,ASAU
 SG_ NMCommandCode_CGW_CCU : 8|3@1+ (1,0) [0|0] ""  WPC2,RLPSU,DPSU,PSB,SHVU_RR,APSU,FCS,EMCU,SLB,RCM,ARS,ATS,RLHV,SGU,PFSU,ALBCU,DSAU,SWRC,SHVU_FR,RCS,RRPSU,BLTN_CAM,SCM,DLBCU,OHCL,RWPC,RRHV,WPC,HOD,ASAU
 SG_ NMSleepFlag_CGW_CCU : 12|2@1+ (1,0) [0|0] ""  WPC2,RLPSU,DPSU,PSB,SHVU_RR,APSU,FCS,EMCU,SLB,RCM,ARS,ATS,RLHV,SGU,PFSU,ALBCU,DSAU,SWRC,SHVU_FR,RCS,RRPSU,BLTN_CAM,SCM,DLBCU,OHCL,RWPC,RRHV,WPC,HOD,ASAU

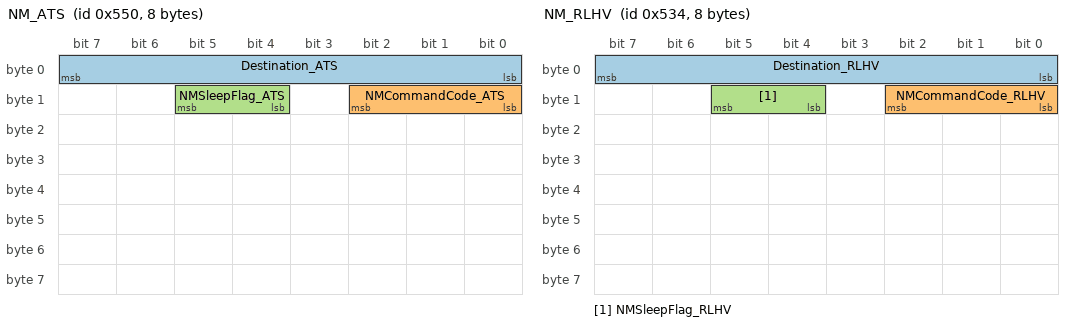
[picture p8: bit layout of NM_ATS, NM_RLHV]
BO_ 1360 NM_ATS: 8 ATS
 SG_ Destination_ATS : 0|8@1+ (1,0) [0|0] ""  WPC2,RLPSU,DPSU,PSB,SHVU_RR,APSU,FCS,EMCU,SLB,RCM,ARS,CGW_CCU,RLHV,SGU,PFSU,ALBCU,DSAU,SWRC,SHVU_FR,RCS,RRPSU,BLTN_CAM,SCM,DLBCU,OHCL,RWPC,RRHV,WPC,HOD,ASAU
 SG_ NMCommandCode_ATS : 8|3@1+ (1,0) [0|0] ""  WPC2,RLPSU,DPSU,PSB,SHVU_RR,APSU,FCS,EMCU,SLB,RCM,ARS,CGW_CCU,RLHV,SGU,PFSU,ALBCU,DSAU,SWRC,SHVU_FR,RCS,RRPSU,BLTN_CAM,SCM,DLBCU,OHCL,RWPC,RRHV,WPC,HOD,ASAU
 SG_ NMSleepFlag_ATS : 12|2@1+ (1,0) [0|0] ""  WPC2,RLPSU,DPSU,PSB,SHVU_RR,APSU,FCS,EMCU,SLB,RCM,ARS,CGW_CCU,RLHV,SGU,PFSU,ALBCU,DSAU,SWRC,SHVU_FR,RCS,RRPSU,BLTN_CAM,SCM,DLBCU,OHCL,RWPC,RRHV,WPC,HOD,ASAU

BO_ 1332 NM_RLHV: 8 RLHV
 SG_ Destination_RLHV : 0|8@1+ (1,0) [0|0] ""  WPC2,RLPSU,DPSU,PSB,SHVU_RR,APSU,FCS,EMCU,SLB,RCM,ARS,CGW_CCU,ATS,SGU,PFSU,ALBCU,DSAU,SWRC,SHVU_FR,RCS,RRPSU,BLTN_CAM,SCM,DLBCU,OHCL,RWPC,RRHV,WPC,HOD,ASAU
 SG_ NMCommandCode_RLHV : 8|3@1+ (1,0) [0|0] ""  WPC2,RLPSU,DPSU,PSB,SHVU_RR,APSU,FCS,EMCU,SLB,RCM,ARS,CGW_CCU,ATS,SGU,PFSU,ALBCU,DSAU,SWRC,SHVU_FR,RCS,RRPSU,BLTN_CAM,SCM,DLBCU,OHCL,RWPC,RRHV,WPC,HOD,ASAU
 SG_ NMSleepFlag_RLHV : 12|2@1+ (1,0) [0|0] ""  WPC2,RLPSU,DPSU,PSB,SHVU_RR,APSU,FCS,EMCU,SLB,RCM,ARS,CGW_CCU,ATS,SGU,PFSU,ALBCU,DSAU,SWRC,SHVU_FR,RCS,RRPSU,BLTN_CAM,SCM,DLBCU,OHCL,RWPC,RRHV,WPC,HOD,ASAU

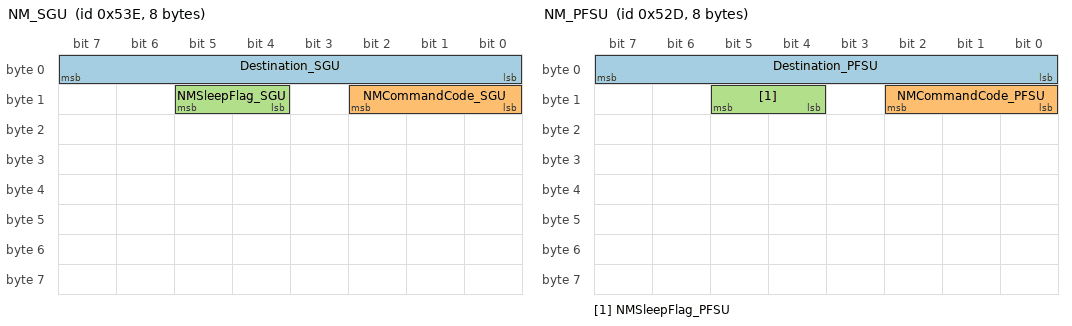
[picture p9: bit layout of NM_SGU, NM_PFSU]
BO_ 1342 NM_SGU: 8 SGU
 SG_ Destination_SGU : 0|8@1+ (1,0) [0|0] ""  WPC2,RLPSU,DPSU,PSB,SHVU_RR,APSU,FCS,EMCU,SLB,RCM,ARS,CGW_CCU,ATS,RLHV,PFSU,ALBCU,DSAU,SWRC,SHVU_FR,RCS,RRPSU,BLTN_CAM,SCM,DLBCU,OHCL,RWPC,RRHV,WPC,HOD,ASAU
 SG_ NMCommandCode_SGU : 8|3@1+ (1,0) [0|0] ""  WPC2,RLPSU,DPSU,PSB,SHVU_RR,APSU,FCS,EMCU,SLB,RCM,ARS,CGW_CCU,ATS,RLHV,PFSU,ALBCU,DSAU,SWRC,SHVU_FR,RCS,RRPSU,BLTN_CAM,SCM,DLBCU,OHCL,RWPC,RRHV,WPC,HOD,ASAU
 SG_ NMSleepFlag_SGU : 12|2@1+ (1,0) [0|0] ""  WPC2,RLPSU,DPSU,PSB,SHVU_RR,APSU,FCS,EMCU,SLB,RCM,ARS,CGW_CCU,ATS,RLHV,PFSU,ALBCU,DSAU,SWRC,SHVU_FR,RCS,RRPSU,BLTN_CAM,SCM,DLBCU,OHCL,RWPC,RRHV,WPC,HOD,ASAU

BO_ 1325 NM_PFSU: 8 PFSU
 SG_ Destination_PFSU : 0|8@1+ (1,0) [0|0] ""  WPC2,RLPSU,DPSU,PSB,SHVU_RR,APSU,FCS,EMCU,SLB,RCM,ARS,CGW_CCU,ATS,RLHV,SGU,ALBCU,DSAU,SWRC,SHVU_FR,RCS,RRPSU,BLTN_CAM,SCM,DLBCU,OHCL,RWPC,RRHV,WPC,HOD,ASAU
 SG_ NMCommandCode_PFSU : 8|3@1+ (1,0) [0|0] ""  WPC2,RLPSU,DPSU,PSB,SHVU_RR,APSU,FCS,EMCU,SLB,RCM,ARS,CGW_CCU,ATS,RLHV,SGU,ALBCU,DSAU,SWRC,SHVU_FR,RCS,RRPSU,BLTN_CAM,SCM,DLBCU,OHCL,RWPC,RRHV,WPC,HOD,ASAU
 SG_ NMSleepFlag_PFSU : 12|2@1+ (1,0) [0|0] ""  WPC2,RLPSU,DPSU,PSB,SHVU_RR,APSU,FCS,EMCU,SLB,RCM,ARS,CGW_CCU,ATS,RLHV,SGU,ALBCU,DSAU,SWRC,SHVU_FR,RCS,RRPSU,BLTN_CAM,SCM,DLBCU,OHCL,RWPC,RRHV,WPC,HOD,ASAU

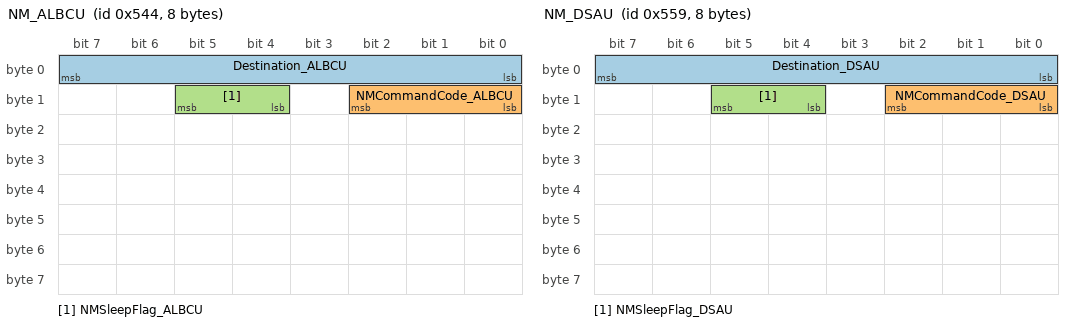
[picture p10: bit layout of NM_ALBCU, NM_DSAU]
BO_ 1348 NM_ALBCU: 8 ALBCU
 SG_ Destination_ALBCU : 0|8@1+ (1,0) [0|0] ""  WPC2,RLPSU,DPSU,PSB,SHVU_RR,APSU,FCS,EMCU,SLB,RCM,ARS,CGW_CCU,ATS,RLHV,SGU,PFSU,DSAU,SWRC,SHVU_FR,RCS,RRPSU,BLTN_CAM,SCM,DLBCU,OHCL,RWPC,RRHV,WPC,HOD,ASAU
 SG_ NMCommandCode_ALBCU : 8|3@1+ (1,0) [0|0] ""  WPC2,RLPSU,DPSU,PSB,SHVU_RR,APSU,FCS,EMCU,SLB,RCM,ARS,CGW_CCU,ATS,RLHV,SGU,PFSU,DSAU,SWRC,SHVU_FR,RCS,RRPSU,BLTN_CAM,SCM,DLBCU,OHCL,RWPC,RRHV,WPC,HOD,ASAU
 SG_ NMSleepFlag_ALBCU : 12|2@1+ (1,0) [0|0] ""  WPC2,RLPSU,DPSU,PSB,SHVU_RR,APSU,FCS,EMCU,SLB,RCM,ARS,CGW_CCU,ATS,RLHV,SGU,PFSU,DSAU,SWRC,SHVU_FR,RCS,RRPSU,BLTN_CAM,SCM,DLBCU,OHCL,RWPC,RRHV,WPC,HOD,ASAU

BO_ 1369 NM_DSAU: 8 DSAU
 SG_ Destination_DSAU : 0|8@1+ (1,0) [0|0] ""  WPC2,RLPSU,DPSU,PSB,SHVU_RR,APSU,FCS,EMCU,SLB,RCM,ARS,CGW_CCU,ATS,RLHV,SGU,PFSU,ALBCU,SWRC,SHVU_FR,RCS,RRPSU,BLTN_CAM,SCM,DLBCU,OHCL,RWPC,RRHV,WPC,HOD,ASAU
 SG_ NMCommandCode_DSAU : 8|3@1+ (1,0) [0|0] ""  WPC2,RLPSU,DPSU,PSB,SHVU_RR,APSU,FCS,EMCU,SLB,RCM,ARS,CGW_CCU,ATS,RLHV,SGU,PFSU,ALBCU,SWRC,SHVU_FR,RCS,RRPSU,BLTN_CAM,SCM,DLBCU,OHCL,RWPC,RRHV,WPC,HOD,ASAU
 SG_ NMSleepFlag_DSAU : 12|2@1+ (1,0) [0|0] ""  WPC2,RLPSU,DPSU,PSB,SHVU_RR,APSU,FCS,EMCU,SLB,RCM,ARS,CGW_CCU,ATS,RLHV,SGU,PFSU,ALBCU,SWRC,SHVU_FR,RCS,RRPSU,BLTN_CAM,SCM,DLBCU,OHCL,RWPC,RRHV,WPC,HOD,ASAU

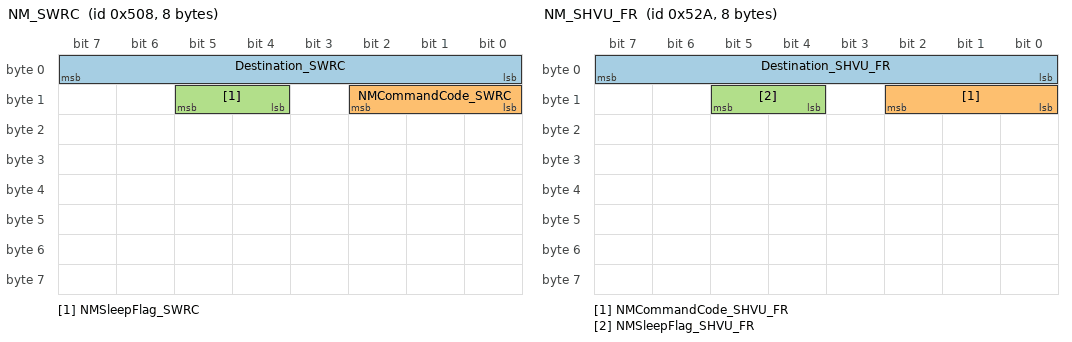
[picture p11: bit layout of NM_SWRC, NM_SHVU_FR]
BO_ 1288 NM_SWRC: 8 SWRC
 SG_ Destination_SWRC : 0|8@1+ (1,0) [0|0] ""  WPC2,RLPSU,DPSU,PSB,SHVU_RR,APSU,FCS,EMCU,SLB,RCM,ARS,CGW_CCU,ATS,RLHV,SGU,PFSU,ALBCU,DSAU,SHVU_FR,RCS,RRPSU,BLTN_CAM,SCM,DLBCU,OHCL,RWPC,RRHV,WPC,HOD,ASAU
 SG_ NMCommandCode_SWRC : 8|3@1+ (1,0) [0|0] ""  WPC2,RLPSU,DPSU,PSB,SHVU_RR,APSU,FCS,EMCU,SLB,RCM,ARS,CGW_CCU,ATS,RLHV,SGU,PFSU,ALBCU,DSAU,SHVU_FR,RCS,RRPSU,BLTN_CAM,SCM,DLBCU,OHCL,RWPC,RRHV,WPC,HOD,ASAU
 SG_ NMSleepFlag_SWRC : 12|2@1+ (1,0) [0|0] ""  WPC2,RLPSU,DPSU,PSB,SHVU_RR,APSU,FCS,EMCU,SLB,RCM,ARS,CGW_CCU,ATS,RLHV,SGU,PFSU,ALBCU,DSAU,SHVU_FR,RCS,RRPSU,BLTN_CAM,SCM,DLBCU,OHCL,RWPC,RRHV,WPC,HOD,ASAU

BO_ 1322 NM_SHVU_FR: 8 SHVU_FR
 SG_ Destination_SHVU_FR : 0|8@1+ (1,0) [0|0] ""  WPC2,RLPSU,DPSU,PSB,SHVU_RR,APSU,FCS,EMCU,SLB,RCM,ARS,CGW_CCU,ATS,RLHV,SGU,PFSU,ALBCU,DSAU,SWRC,RCS,RRPSU,BLTN_CAM,SCM,DLBCU,OHCL,RWPC,RRHV,WPC,HOD,ASAU
 SG_ NMCommandCode_SHVU_FR : 8|3@1+ (1,0) [0|0] ""  WPC2,RLPSU,DPSU,PSB,SHVU_RR,APSU,FCS,EMCU,SLB,RCM,ARS,CGW_CCU,ATS,RLHV,SGU,PFSU,ALBCU,DSAU,SWRC,RCS,RRPSU,BLTN_CAM,SCM,DLBCU,OHCL,RWPC,RRHV,WPC,HOD,ASAU
 SG_ NMSleepFlag_SHVU_FR : 12|2@1+ (1,0) [0|0] ""  WPC2,RLPSU,DPSU,PSB,SHVU_RR,APSU,FCS,EMCU,SLB,RCM,ARS,CGW_CCU,ATS,RLHV,SGU,PFSU,ALBCU,DSAU,SWRC,RCS,RRPSU,BLTN_CAM,SCM,DLBCU,OHCL,RWPC,RRHV,WPC,HOD,ASAU

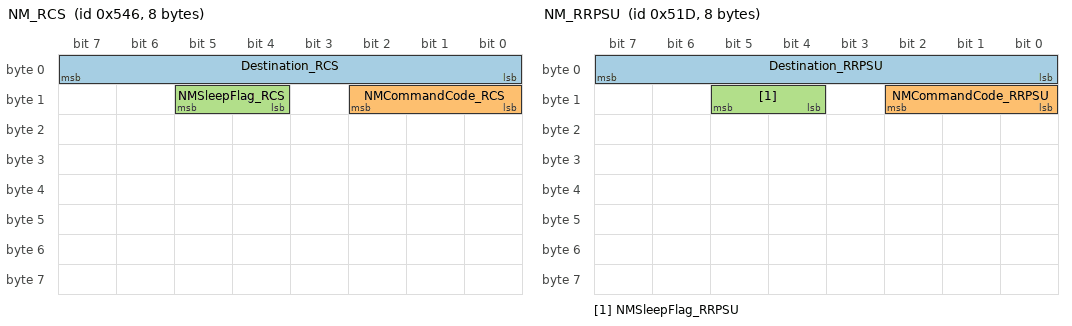
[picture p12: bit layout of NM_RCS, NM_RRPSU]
BO_ 1350 NM_RCS: 8 RCS
 SG_ Destination_RCS : 0|8@1+ (1,0) [0|0] ""  WPC2,RLPSU,DPSU,PSB,SHVU_RR,APSU,FCS,EMCU,SLB,RCM,ARS,CGW_CCU,ATS,RLHV,SGU,PFSU,ALBCU,DSAU,SWRC,SHVU_FR,RRPSU,BLTN_CAM,SCM,DLBCU,OHCL,RWPC,RRHV,WPC,HOD,ASAU
 SG_ NMCommandCode_RCS : 8|3@1+ (1,0) [0|0] ""  WPC2,RLPSU,DPSU,PSB,SHVU_RR,APSU,FCS,EMCU,SLB,RCM,ARS,CGW_CCU,ATS,RLHV,SGU,PFSU,ALBCU,DSAU,SWRC,SHVU_FR,RRPSU,BLTN_CAM,SCM,DLBCU,OHCL,RWPC,RRHV,WPC,HOD,ASAU
 SG_ NMSleepFlag_RCS : 12|2@1+ (1,0) [0|0] ""  WPC2,RLPSU,DPSU,PSB,SHVU_RR,APSU,FCS,EMCU,SLB,RCM,ARS,CGW_CCU,ATS,RLHV,SGU,PFSU,ALBCU,DSAU,SWRC,SHVU_FR,RRPSU,BLTN_CAM,SCM,DLBCU,OHCL,RWPC,RRHV,WPC,HOD,ASAU

BO_ 1309 NM_RRPSU: 8 RRPSU
 SG_ Destination_RRPSU : 0|8@1+ (1,0) [0|0] ""  WPC2,RLPSU,DPSU,PSB,SHVU_RR,APSU,FCS,EMCU,SLB,RCM,ARS,CGW_CCU,ATS,RLHV,SGU,PFSU,ALBCU,DSAU,SWRC,SHVU_FR,RCS,BLTN_CAM,SCM,DLBCU,OHCL,RWPC,RRHV,WPC,HOD,ASAU
 SG_ NMCommandCode_RRPSU : 8|3@1+ (1,0) [0|0] ""  WPC2,RLPSU,DPSU,PSB,SHVU_RR,APSU,FCS,EMCU,SLB,RCM,ARS,CGW_CCU,ATS,RLHV,SGU,PFSU,ALBCU,DSAU,SWRC,SHVU_FR,RCS,BLTN_CAM,SCM,DLBCU,OHCL,RWPC,RRHV,WPC,HOD,ASAU
 SG_ NMSleepFlag_RRPSU : 12|2@1+ (1,0) [0|0] ""  WPC2,RLPSU,DPSU,PSB,SHVU_RR,APSU,FCS,EMCU,SLB,RCM,ARS,CGW_CCU,ATS,RLHV,SGU,PFSU,ALBCU,DSAU,SWRC,SHVU_FR,RCS,BLTN_CAM,SCM,DLBCU,OHCL,RWPC,RRHV,WPC,HOD,ASAU

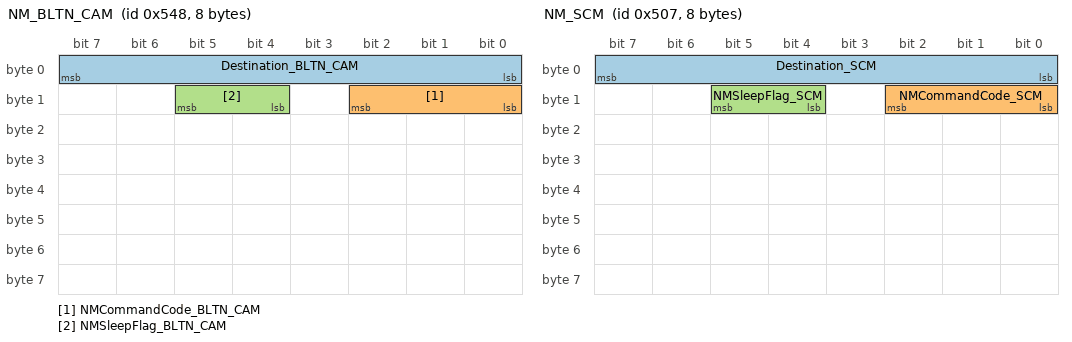
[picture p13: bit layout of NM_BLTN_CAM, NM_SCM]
BO_ 1352 NM_BLTN_CAM: 8 BLTN_CAM
 SG_ Destination_BLTN_CAM : 0|8@1+ (1,0) [0|0] ""  WPC2,RLPSU,DPSU,PSB,SHVU_RR,APSU,FCS,EMCU,SLB,RCM,ARS,CGW_CCU,ATS,RLHV,SGU,PFSU,ALBCU,DSAU,SWRC,SHVU_FR,RCS,RRPSU,SCM,DLBCU,OHCL,RWPC,RRHV,WPC,HOD,ASAU
 SG_ NMCommandCode_BLTN_CAM : 8|3@1+ (1,0) [0|0] ""  WPC2,RLPSU,DPSU,PSB,SHVU_RR,APSU,FCS,EMCU,SLB,RCM,ARS,CGW_CCU,ATS,RLHV,SGU,PFSU,ALBCU,DSAU,SWRC,SHVU_FR,RCS,RRPSU,SCM,DLBCU,OHCL,RWPC,RRHV,WPC,HOD,ASAU
 SG_ NMSleepFlag_BLTN_CAM : 12|2@1+ (1,0) [0|0] ""  WPC2,RLPSU,DPSU,PSB,SHVU_RR,APSU,FCS,EMCU,SLB,RCM,ARS,CGW_CCU,ATS,RLHV,SGU,PFSU,ALBCU,DSAU,SWRC,SHVU_FR,RCS,RRPSU,SCM,DLBCU,OHCL,RWPC,RRHV,WPC,HOD,ASAU

BO_ 1287 NM_SCM: 8 SCM
 SG_ Destination_SCM : 0|8@1+ (1,0) [0|0] ""  WPC2,RLPSU,DPSU,PSB,SHVU_RR,APSU,FCS,EMCU,SLB,RCM,ARS,CGW_CCU,ATS,RLHV,SGU,PFSU,ALBCU,DSAU,SWRC,SHVU_FR,RCS,RRPSU,BLTN_CAM,DLBCU,OHCL,RWPC,RRHV,WPC,HOD,ASAU
 SG_ NMCommandCode_SCM : 8|3@1+ (1,0) [0|0] ""  WPC2,RLPSU,DPSU,PSB,SHVU_RR,APSU,FCS,EMCU,SLB,RCM,ARS,CGW_CCU,ATS,RLHV,SGU,PFSU,ALBCU,DSAU,SWRC,SHVU_FR,RCS,RRPSU,BLTN_CAM,DLBCU,OHCL,RWPC,RRHV,WPC,HOD,ASAU
 SG_ NMSleepFlag_SCM : 12|2@1+ (1,0) [0|0] ""  WPC2,RLPSU,DPSU,PSB,SHVU_RR,APSU,FCS,EMCU,SLB,RCM,ARS,CGW_CCU,ATS,RLHV,SGU,PFSU,ALBCU,DSAU,SWRC,SHVU_FR,RCS,RRPSU,BLTN_CAM,DLBCU,OHCL,RWPC,RRHV,WPC,HOD,ASAU

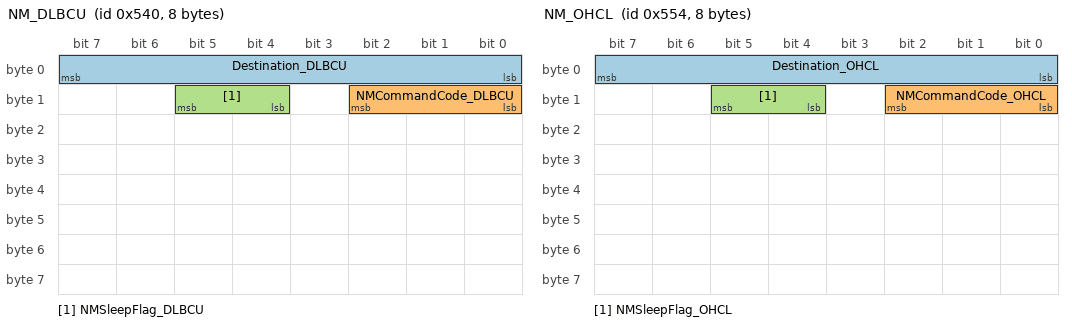
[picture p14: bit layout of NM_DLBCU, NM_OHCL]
BO_ 1344 NM_DLBCU: 8 DLBCU
 SG_ Destination_DLBCU : 0|8@1+ (1,0) [0|0] ""  WPC2,RLPSU,DPSU,PSB,SHVU_RR,APSU,FCS,EMCU,SLB,RCM,ARS,CGW_CCU,ATS,RLHV,SGU,PFSU,ALBCU,DSAU,SWRC,SHVU_FR,RCS,RRPSU,BLTN_CAM,SCM,OHCL,RWPC,RRHV,WPC,HOD,ASAU
 SG_ NMCommandCode_DLBCU : 8|3@1+ (1,0) [0|0] ""  WPC2,RLPSU,DPSU,PSB,SHVU_RR,APSU,FCS,EMCU,SLB,RCM,ARS,CGW_CCU,ATS,RLHV,SGU,PFSU,ALBCU,DSAU,SWRC,SHVU_FR,RCS,RRPSU,BLTN_CAM,SCM,OHCL,RWPC,RRHV,WPC,HOD,ASAU
 SG_ NMSleepFlag_DLBCU : 12|2@1+ (1,0) [0|0] ""  WPC2,RLPSU,DPSU,PSB,SHVU_RR,APSU,FCS,EMCU,SLB,RCM,ARS,CGW_CCU,ATS,RLHV,SGU,PFSU,ALBCU,DSAU,SWRC,SHVU_FR,RCS,RRPSU,BLTN_CAM,SCM,OHCL,RWPC,RRHV,WPC,HOD,ASAU

BO_ 1364 NM_OHCL: 8 OHCL
 SG_ Destination_OHCL : 0|8@1+ (1,0) [0|0] ""  WPC2,RLPSU,DPSU,PSB,SHVU_RR,APSU,FCS,EMCU,SLB,RCM,ARS,CGW_CCU,ATS,RLHV,SGU,PFSU,ALBCU,DSAU,SWRC,SHVU_FR,RCS,RRPSU,BLTN_CAM,SCM,DLBCU,RWPC,RRHV,WPC,HOD,ASAU
 SG_ NMCommandCode_OHCL : 8|3@1+ (1,0) [0|0] ""  WPC2,RLPSU,DPSU,PSB,SHVU_RR,APSU,FCS,EMCU,SLB,RCM,ARS,CGW_CCU,ATS,RLHV,SGU,PFSU,ALBCU,DSAU,SWRC,SHVU_FR,RCS,RRPSU,BLTN_CAM,SCM,DLBCU,RWPC,RRHV,WPC,HOD,ASAU
 SG_ NMSleepFlag_OHCL : 12|2@1+ (1,0) [0|0] ""  WPC2,RLPSU,DPSU,PSB,SHVU_RR,APSU,FCS,EMCU,SLB,RCM,ARS,CGW_CCU,ATS,RLHV,SGU,PFSU,ALBCU,DSAU,SWRC,SHVU_FR,RCS,RRPSU,BLTN_CAM,SCM,DLBCU,RWPC,RRHV,WPC,HOD,ASAU

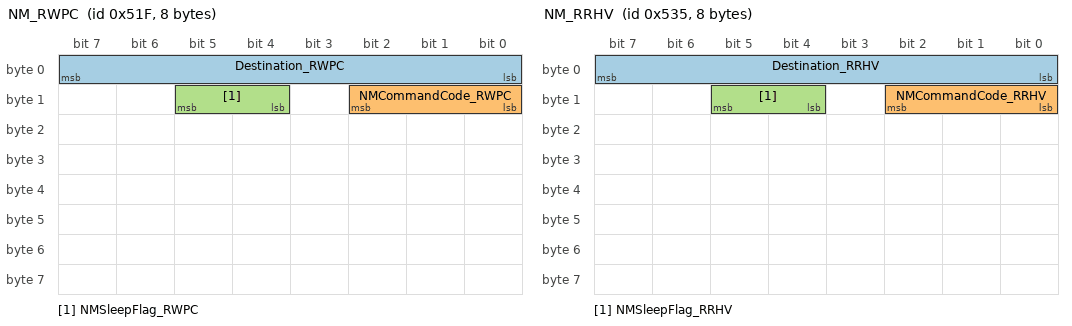
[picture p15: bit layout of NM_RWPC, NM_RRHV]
BO_ 1311 NM_RWPC: 8 RWPC
 SG_ Destination_RWPC : 0|8@1+ (1,0) [0|0] ""  WPC2,RLPSU,DPSU,PSB,SHVU_RR,APSU,FCS,EMCU,SLB,RCM,ARS,CGW_CCU,ATS,RLHV,SGU,PFSU,ALBCU,DSAU,SWRC,SHVU_FR,RCS,RRPSU,BLTN_CAM,SCM,DLBCU,OHCL,RRHV,WPC,HOD,ASAU
 SG_ NMCommandCode_RWPC : 8|3@1+ (1,0) [0|0] ""  WPC2,RLPSU,DPSU,PSB,SHVU_RR,APSU,FCS,EMCU,SLB,RCM,ARS,CGW_CCU,ATS,RLHV,SGU,PFSU,ALBCU,DSAU,SWRC,SHVU_FR,RCS,RRPSU,BLTN_CAM,SCM,DLBCU,OHCL,RRHV,WPC,HOD,ASAU
 SG_ NMSleepFlag_RWPC : 12|2@1+ (1,0) [0|0] ""  WPC2,RLPSU,DPSU,PSB,SHVU_RR,APSU,FCS,EMCU,SLB,RCM,ARS,CGW_CCU,ATS,RLHV,SGU,PFSU,ALBCU,DSAU,SWRC,SHVU_FR,RCS,RRPSU,BLTN_CAM,SCM,DLBCU,OHCL,RRHV,WPC,HOD,ASAU

BO_ 1333 NM_RRHV: 8 RRHV
 SG_ Destination_RRHV : 0|8@1+ (1,0) [0|0] ""  WPC2,RLPSU,DPSU,PSB,SHVU_RR,APSU,FCS,EMCU,SLB,RCM,ARS,CGW_CCU,ATS,RLHV,SGU,PFSU,ALBCU,DSAU,SWRC,SHVU_FR,RCS,RRPSU,BLTN_CAM,SCM,DLBCU,OHCL,RWPC,WPC,HOD,ASAU
 SG_ NMCommandCode_RRHV : 8|3@1+ (1,0) [0|0] ""  WPC2,RLPSU,DPSU,PSB,SHVU_RR,APSU,FCS,EMCU,SLB,RCM,ARS,CGW_CCU,ATS,RLHV,SGU,PFSU,ALBCU,DSAU,SWRC,SHVU_FR,RCS,RRPSU,BLTN_CAM,SCM,DLBCU,OHCL,RWPC,WPC,HOD,ASAU
 SG_ NMSleepFlag_RRHV : 12|2@1+ (1,0) [0|0] ""  WPC2,RLPSU,DPSU,PSB,SHVU_RR,APSU,FCS,EMCU,SLB,RCM,ARS,CGW_CCU,ATS,RLHV,SGU,PFSU,ALBCU,DSAU,SWRC,SHVU_FR,RCS,RRPSU,BLTN_CAM,SCM,DLBCU,OHCL,RWPC,WPC,HOD,ASAU

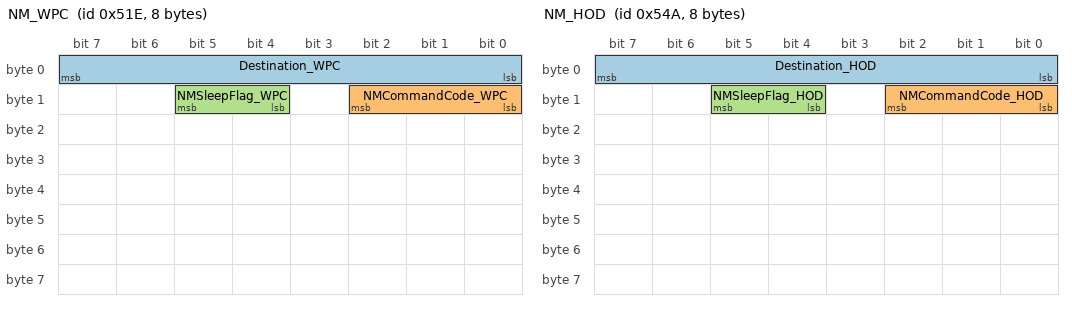
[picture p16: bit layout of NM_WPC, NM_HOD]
BO_ 1310 NM_WPC: 8 WPC
 SG_ Destination_WPC : 0|8@1+ (1,0) [0|0] ""  WPC2,RLPSU,DPSU,PSB,SHVU_RR,APSU,FCS,EMCU,SLB,RCM,ARS,CGW_CCU,ATS,RLHV,SGU,PFSU,ALBCU,DSAU,SWRC,SHVU_FR,RCS,RRPSU,BLTN_CAM,SCM,DLBCU,OHCL,RWPC,RRHV,HOD,ASAU
 SG_ NMCommandCode_WPC : 8|3@1+ (1,0) [0|0] ""  WPC2,RLPSU,DPSU,PSB,SHVU_RR,APSU,FCS,EMCU,SLB,RCM,ARS,CGW_CCU,ATS,RLHV,SGU,PFSU,ALBCU,DSAU,SWRC,SHVU_FR,RCS,RRPSU,BLTN_CAM,SCM,DLBCU,OHCL,RWPC,RRHV,HOD,ASAU
 SG_ NMSleepFlag_WPC : 12|2@1+ (1,0) [0|0] ""  WPC2,RLPSU,DPSU,PSB,SHVU_RR,APSU,FCS,EMCU,SLB,RCM,ARS,CGW_CCU,ATS,RLHV,SGU,PFSU,ALBCU,DSAU,SWRC,SHVU_FR,RCS,RRPSU,BLTN_CAM,SCM,DLBCU,OHCL,RWPC,RRHV,HOD,ASAU

BO_ 1354 NM_HOD: 8 HOD
 SG_ Destination_HOD : 0|8@1+ (1,0) [0|0] ""  WPC2,RLPSU,DPSU,PSB,SHVU_RR,APSU,FCS,EMCU,SLB,RCM,ARS,CGW_CCU,ATS,RLHV,SGU,PFSU,ALBCU,DSAU,SWRC,SHVU_FR,RCS,RRPSU,BLTN_CAM,SCM,DLBCU,OHCL,RWPC,RRHV,WPC,ASAU
 SG_ NMCommandCode_HOD : 8|3@1+ (1,0) [0|0] ""  WPC2,RLPSU,DPSU,PSB,SHVU_RR,APSU,FCS,EMCU,SLB,RCM,ARS,CGW_CCU,ATS,RLHV,SGU,PFSU,ALBCU,DSAU,SWRC,SHVU_FR,RCS,RRPSU,BLTN_CAM,SCM,DLBCU,OHCL,RWPC,RRHV,WPC,ASAU
 SG_ NMSleepFlag_HOD : 12|2@1+ (1,0) [0|0] ""  WPC2,RLPSU,DPSU,PSB,SHVU_RR,APSU,FCS,EMCU,SLB,RCM,ARS,CGW_CCU,ATS,RLHV,SGU,PFSU,ALBCU,DSAU,SWRC,SHVU_FR,RCS,RRPSU,BLTN_CAM,SCM,DLBCU,OHCL,RWPC,RRHV,WPC,ASAU

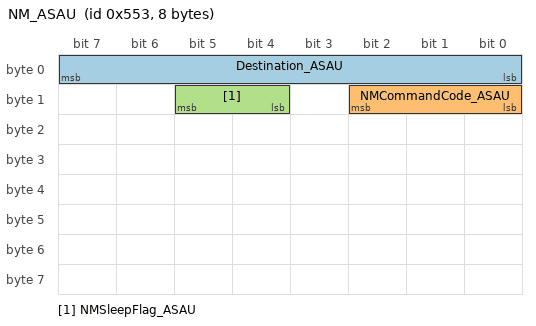
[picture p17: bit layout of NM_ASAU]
BO_ 1363 NM_ASAU: 8 ASAU
 SG_ Destination_ASAU : 0|8@1+ (1,0) [0|0] ""  WPC2,RLPSU,DPSU,PSB,SHVU_RR,APSU,FCS,EMCU,SLB,RCM,ARS,CGW_CCU,ATS,RLHV,SGU,PFSU,ALBCU,DSAU,SWRC,SHVU_FR,RCS,RRPSU,BLTN_CAM,SCM,DLBCU,OHCL,RWPC,RRHV,WPC,HOD
 SG_ NMCommandCode_ASAU : 8|3@1+ (1,0) [0|0] ""  WPC2,RLPSU,DPSU,PSB,SHVU_RR,APSU,FCS,EMCU,SLB,RCM,ARS,CGW_CCU,ATS,RLHV,SGU,PFSU,ALBCU,DSAU,SWRC,SHVU_FR,RCS,RRPSU,BLTN_CAM,SCM,DLBCU,OHCL,RWPC,RRHV,WPC,HOD
 SG_ NMSleepFlag_ASAU : 12|2@1+ (1,0) [0|0] ""  WPC2,RLPSU,DPSU,PSB,SHVU_RR,APSU,FCS,EMCU,SLB,RCM,ARS,CGW_CCU,ATS,RLHV,SGU,PFSU,ALBCU,DSAU,SWRC,SHVU_FR,RCS,RRPSU,BLTN_CAM,SCM,DLBCU,OHCL,RWPC,RRHV,WPC,HOD

CM_ BO_ 2015 "[TP] Transport Protocol";
CM_ BO_ 1193 "[EC] On Event and On Change";
CM_ SG_ 1193 C_PTGMNValueSet "Request to set PTGM Mode";
CM_ SG_ 1193 CF_AVN_PSMNValueSet "This signal is used for a request to set the value of UMS Menus. This signal requests to set Seat Easy Access Mode. When this signal change, the message is sent 3 times.";
CM_ SG_ 1193 C_HfreeTrunkTgNValueSet "Request to set Smart Trunk/Tailgate Mode";
CM_ SG_ 1193 CF_AVN_TrfChgSet "This signal is used for a request to set the value of UMS Menus. This signal requests to set Traffic Change Mode. When this signal change, the message is sent 3 times.";
CM_ SG_ 1193 CF_AVN_SCMNValueSet "Request to set Steering Easy Access mode";
CM_ SG_ 1193 CF_AVN_ADrUNValueSet "Request to set Auto Door Unlock Mode";
CM_ SG_ 1193 CF_AVN_OTTurnNValueSet "This signal is used for a request current setting value of USM Menus. When this signal change, the message is sent 3 times.";
CM_ SG_ 1193 CF_Gway_WPCNValueSet "Request to set Wireless Phone Charging mode";
CM_ SG_ 1193 C_AVN_RearWiperNValueSet "Request to set Rear Wiper operation in reverse";
CM_ SG_ 1193 C_UnlockWelocomeNValueSet "Request to set Door Unlock Welcome Setting Option";
CM_ SG_ 1193 C_SmartWelocomeNValueSet "Request to set Smart Key Welcome Setting Option";
CM_ SG_ 1193 CF_AVN_PTGSpeedNValueSet "Setting Value For Power Tailgate Speed";
CM_ SG_ 1193 CR_Datc_DRSeatWheel_USM_Set "SteeringWheel USM Set";
CM_ SG_ 1193 CF_AVN_TTUnlockNValueSet "Setting Value for Two Turn Unlock";
CM_ SG_ 1193 CF_Gway_RWPCNValueSet "Rear Wireless Phone Charger ON/OFF Request";
CM_ SG_ 1193 CF_Avn_HAPTICWARNINGNValueSet "USM request for Steering Wheel Haptic Warning";
CM_ SG_ 1193 CR_Datc_DRSeatHeat_USM_Set "Driver Seat Heat/Ventl USM Set";
CM_ SG_ 1193 C_WALNValueSet "USM Function for Walk Away Lock(WAL)";
CM_ SG_ 1193 C_ApprUnlockNValue "USM request for Approach Unlock";
CM_ SG_ 1193 CF_AVN_EscortHLNValueSet "Request to set Head Lamp Escort Option";
CM_ BO_ 491 "[EC] On Event and On Change";
CM_ SG_ 491 DAB_IlluminationVrModeSet "Signal of mood lamp concern about AI voice";
CM_ BO_ 1076 "[PE] Periodic and On Event";
CM_ SG_ 1076 IAU_ProfileIDRVal "This signal Indicate the Current detected Profile ID by IAU.";
CM_ SG_ 1076 IAU_DigitalKeyProcessingSta "Digital Key USM settitng Process State";
CM_ SG_ 1076 IAU_DigitalKeyExit "Digital Key USM setting Exit Condition";
CM_ SG_ 1076 IAU_DigitalKeyEnblRVal "Digital Key Function Enable / Disable flag (Fob is required for changing flag)";
CM_ SG_ 1076 IAU_OwnerPhnRegRVal "Vehicle Owner's Phone is Registered for Digital Key function";
CM_ SG_ 1076 IAU_NFCCard1RegRVal "NFC Card 1 is Registered for Digital Key function";
CM_ SG_ 1076 IAU_NFCCard2RegRVal "NFC Card 2 is Registered for Digital Key function";
CM_ SG_ 1076 IAU_DigitalKey2Opt "Digital Key2 Option Signal";
CM_ BO_ 1073 "[PE] Periodic and On Event";
CM_ SG_ 1073 USM_ValCmdSta "USM_ValueCommandStatus";
CM_ SG_ 1073 RWPC_SWVerMinor1 "Second Word(ASCII) in RWPC S/W Ver";
CM_ SG_ 1073 WPC_PhnLftWrngRWPCSta "WPC_PhoneLeftWaringRWPCStatus";
CM_ SG_ 1073 RWPC_SWVerMinor2 "Third Word(ASCII) in RWPC S/W Ver";
CM_ SG_ 1073 USM_ValCmdStaforATS "USM_ValueCommandStatus";
CM_ SG_ 1073 RWPC_SWVerMajor1 "First Word(ASCII) in RWPC S/W Ver";
CM_ BO_ 858 "[PE] Periodic and On Event";
CM_ SG_ 858 SBCM_AST_Crc2Val "SBCM_AST_CyclicRedundancyCheck2Value";
CM_ SG_ 858 AST_CrashUnlockCmd "AssistCrashUnlockCommand";
CM_ SG_ 858 SBCM_AST_AlvCnt2Val "SBCM_AST_AliveCounter2Value";
CM_ SG_ 858 DoorLock_CtrlDrLkSwSta_SBCM "DoorLock_CentralDoorLockAssistSwitchStatus";
CM_ SG_ 858 DoorLock_CtrlDrUnLkSwSta_SBCM "DoorLock_CentralDoorUnLockAssistSwitchStatus";
CM_ SG_ 858 Warn_AsstDrSwSta_SBCM "Warn_AssistDoorSwitchStatus ##2G## -  - C_AstDrSw,CF_Gway_AstDrSw,Warn_AsstDrSwSta";
CM_ SG_ 858 DoorLock_AsstDrUnLkSta_SBCM "DoorLock_AssistDoorUnLockStatus ##2G## -  - C_AstUnlockState,DoorLock_AsstDrUnLkSta";
CM_ SG_ 858 AST_SEAWarn_RH "Assist SEA Warning (LHD)";
CM_ BO_ 799 "[PE] Periodic and On Event";
CM_ SG_ 799 SBCM_DRV_Crc1Val "SBCM_DRV_CyclicRedundancyCheck1Value";
CM_ SG_ 799 C_ApprOpenStatus "Stop fob searching signal";
CM_ SG_ 799 SBCM_DRV_AlvCnt1Val "SBCM_DRV_AliveCounter1Value";
CM_ SG_ 799 DoorLock_DrvKeyLkSwSta_SBCM "DoorLock_DriverKeyLockSwitchStatus ##2G## -  - C_DrvKeyLockSw";
CM_ SG_ 799 DoorLock_DrvKeyUnLkSwSta_SBCM "DoorLock_DriverKeyUnLockSwitchStatus ##2G## -  - C_DrvKeyUnlockSw";
CM_ SG_ 799 Warn_DrvDrSwSta_SBCM "DoorLock_DriverDoorSwitchStatus ##2G## -  - C_DrvDrSw,CF_Gway_DrvDrSw,Warn_DrvDrSwSta";
CM_ SG_ 799 DoorLock_DrvDrUnLkSta_SBCM "DoorLock_DriverDoorUnLockStatus ##2G## -  - C_DrvUnlockState,CF_Gway_DrvUnlockState";
CM_ SG_ 799 C_DrvDoorApproachOpen "Approach open";
CM_ BO_ 862 "[PE] Periodic and On Event";
CM_ SG_ 862 SBCM_RL_Crc1Val "SBCM_RL_CyclicRedundancyCheck1Value";
CM_ SG_ 862 RL_CrashUnlockCmd "Rear Lefr Crash Unlock Command";
CM_ SG_ 862 SBCM_RL_AlvCnt1Val "SBCM_RL_AliveCounter1Value";
CM_ SG_ 862 Warn_RrLftDrSwSta_SBCM "Warn_RearLeftDoorSwitchStatus ##2G## -  - C_RLDrSw,CF_Gway_RLDrSw,Warn_RrLftDrSwSta";
CM_ SG_ 862 DoorLock_RrLftDrUnLkSta_SBCM "DoorLock_RearLeftDoorUnLockStatus ##2G## -  - C_RLUnlockState,DoorLock_RrLftDrUnLkSta";
CM_ SG_ 862 RL_SEAActivated "RearLeftSEAActivated";
CM_ SG_ 862 RL_SEAWarn "Rear Left SEA Warning";
CM_ BO_ 905 "[PE] Periodic and On Event";
CM_ SG_ 905 SBCM_RR_Crc1Val "SBCM_RR_CyclicRedundancyCheck1Value";
CM_ SG_ 905 RR_CrashUnlockCmd "Rear Right Crash Unlock Command";
CM_ SG_ 905 SBCM_RR_AlvCnt1Val "SBCM_RR_AliveCounter1Value";
CM_ SG_ 905 Warn_RrRtDrSwSta_SBCM "Warn_RearRightDoorSwitchStatus ##2G## -  - C_RRDrSw,CF_Gway_RRDrSw,Warn_RrRtDrSwSta";
CM_ SG_ 905 DoorLock_RrRtDrUnLkSta_SBCM "DoorLock_RearRightDoorUnLockStatus ##2G## -  - C_RRUnlockState,DoorLock_RrRtDrUnLkSta";
CM_ SG_ 905 RR_SEAActivated "Rear Right SEA Activated";
CM_ SG_ 905 RR_SEAWarn "Rear Righr SEA Warning";
CM_ BO_ 2160080129 "[P] Periodic";
CM_ SG_ 2160080129 VCU_Crc1Val "VCU_CyclicRedundancyCheck1Value";
CM_ SG_ 2160080129 VCU_AlvCnt1Val "VCU_AliveCounter1Value";
CM_ SG_ 2160080129 VCU_RdySta "VCU_ReadyStatus ##2G##VCU - VCU1 - CF_Vcu_Rdy";
CM_ SG_ 2160080129 VCU_StartKeyHoldSta "VCU_StartKeyHoldStatus ##2G##VCU - VCU1 - CF_Vcu_Key_ST";
CM_ SG_ 2160080129 VCU_EvDrvRdySta "VCU_EvDriveReadyStatus ##2G##VCU - VCU1 - CF_Vcu_EvRdy";
CM_ SG_ 2160080129 VCU_MotPwrEnReq "VCU_MotorPowerEnableRequest ##2G##VCU - VCU3 - CF_Vcu_MotPwrEna";
CM_ SG_ 2160080129 VCU_GearPosSta "VCU_GearPositionStatus ##2G##VCU - VCU1 - CF_Vcu_GarSelDisp";
CM_ SG_ 2160080129 VCU_LdcInhReq "VCU_LdcInhibitRequest ##2G##VCU - VCU5 - CF_Vcu_LdcInh";
CM_ SG_ 2160080129 VCU_MainRlyOffReq "VCU_MainRelayCutOffRequest ##2G##VCU - VCU1 - CF_Vcu_RelayOffReq";
CM_ SG_ 2160080129 VCU_AccPedDepVal "VCU_AcceleratorPedalDepthValue ##2G##VCU - VCU1 - CR_Vcu_AccPedDep_Pc";
CM_ SG_ 2160080129 VCU_FatcOperPermSta "VCU_FatcOperatingPermissionStatus ##2G##VCU - VCU20 - CF_Vcu_ClimateOperPerm";
CM_ SG_ 2160080129 VCU_DrvCycSta "VCU_DrivingCycleStatus ##2G##VCU - VCU1 - CF_Vcu_Veh_DC";
CM_ SG_ 2160080129 VCU_CltActOpSta "VCU_ClutchActuatorOperatingStatus";
CM_ SG_ 2160080129 VCU_WhlSpdSnsrAlvReq "VCU_WheelSpeedSensorAliveRequest";
CM_ SG_ 2160080129 VCU_DrvModOpSta "VCU's operating drive mode according to CLU and DMIC signals";
CM_ SG_ 2160080129 VCU_IgOffGearPosStaDispReq "VCU_IgOffGearPositionStatusDispayRequest";
CM_ BO_ 1301 "NM Message";
CM_ SG_ 1301 Destination_WPC2 "NM Source Node Identifier";
CM_ SG_ 1301 NMCommandCode_WPC2 "NM Control Bit Vector - Repeat Message Request";
CM_ SG_ 1301 NMSleepFlag_WPC2 "NM Control Bit Vector - NM Coordinator ID";
CM_ BO_ 1308 "NM Message";
CM_ SG_ 1308 Destination_RLPSU "NM Source Node Identifier";
CM_ SG_ 1308 NMCommandCode_RLPSU "NM Control Bit Vector - Repeat Message Request";
CM_ SG_ 1308 NMSleepFlag_RLPSU "NM Control Bit Vector - NM Coordinator ID";
CM_ BO_ 1336 "NM Message";
CM_ SG_ 1336 Destination_DPSU "NM Source Node Identifier";
CM_ SG_ 1336 NMCommandCode_DPSU "NM Control Bit Vector - Repeat Message Request";
CM_ SG_ 1336 NMSleepFlag_DPSU "NM Control Bit Vector - NM Coordinator ID";
CM_ BO_ 1345 "NM Message";
CM_ SG_ 1345 Destination_PSB "NM Source Node Identifier";
CM_ SG_ 1345 NMCommandCode_PSB "NM Control Bit Vector - Repeat Message Request";
CM_ SG_ 1345 NMSleepFlag_PSB "NM Control Bit Vector - NM Coordinator ID";
CM_ BO_ 1323 "NM Message";
CM_ SG_ 1323 Destination_SHVU_RR "NM Source Node Identifier";
CM_ SG_ 1323 NMCommandCode_SHVU_RR "NM Control Bit Vector - Repeat Message Request";
CM_ SG_ 1323 NMSleepFlag_SHVU_RR "NM Control Bit Vector - NM Coordinator ID";
CM_ BO_ 1329 "NM Message";
CM_ SG_ 1329 Destination_APSU "NM Source Node Identifier";
CM_ SG_ 1329 NMCommandCode_APSU "NM Control Bit Vector - Repeat Message Request";
CM_ SG_ 1329 NMSleepFlag_APSU "NM Control Bit Vector - NM Coordinator ID";
CM_ BO_ 1313 "NM Message";
CM_ SG_ 1313 Destination_FCS "NM Source Node Identifier";
CM_ SG_ 1313 NMCommandCode_FCS "NM Control Bit Vector - Repeat Message Request";
CM_ SG_ 1313 NMSleepFlag_FCS "NM Control Bit Vector - NM Coordinator ID";
CM_ BO_ 1297 "NM Message";
CM_ SG_ 1297 Destination_EMCU "NM Source Node Identifier";
CM_ SG_ 1297 NMCommandCode_EMCU "NM Control Bit Vector - Repeat Message Request";
CM_ SG_ 1297 NMSleepFlag_EMCU "NM Control Bit Vector - NM Coordinator ID";
CM_ BO_ 1307 "NM Message";
CM_ SG_ 1307 Destination_SLB "NM Source Node Identifier";
CM_ SG_ 1307 NMCommandCode_SLB "NM Control Bit Vector - Repeat Message Request";
CM_ SG_ 1307 NMSleepFlag_SLB "NM Control Bit Vector - NM Coordinator ID";
CM_ BO_ 1341 "NM Message";
CM_ SG_ 1341 Destination_RCM "NM Source Node Identifier";
CM_ SG_ 1341 NMCommandCode_RCM "NM Control Bit Vector - Repeat Message Request";
CM_ SG_ 1341 NMSleepFlag_RCM "NM Control Bit Vector - NM Coordinator ID";
CM_ BO_ 1290 "NM Message";
CM_ SG_ 1290 Destination_ARS "NM Source Node Identifier";
CM_ SG_ 1290 NMCommandCode_ARS "NM Control Bit Vector - Repeat Message Request";
CM_ SG_ 1290 NMSleepFlag_ARS "NM Control Bit Vector - NM Coordinator ID";
CM_ BO_ 1392 "NM Message";
CM_ SG_ 1392 Destination_CGW_CCU "NM Source Node Identifier";
CM_ SG_ 1392 NMCommandCode_CGW_CCU "NM Control Bit Vector - Repeat Message Request";
CM_ SG_ 1392 NMSleepFlag_CGW_CCU "NM Control Bit Vector - NM Coordinator ID";
CM_ BO_ 1360 "NM Message";
CM_ SG_ 1360 Destination_ATS "NM Source Node Identifier";
CM_ SG_ 1360 NMCommandCode_ATS "NM Control Bit Vector - Repeat Message Request";
CM_ SG_ 1360 NMSleepFlag_ATS "NM Control Bit Vector - NM Coordinator ID";
CM_ BO_ 1332 "NM Message";
CM_ SG_ 1332 Destination_RLHV "NM Source Node Identifier";
CM_ SG_ 1332 NMCommandCode_RLHV "NM Control Bit Vector - Repeat Message Request";
CM_ SG_ 1332 NMSleepFlag_RLHV "NM Control Bit Vector - NM Coordinator ID";
CM_ BO_ 1342 "NM Message";
CM_ SG_ 1342 Destination_SGU "NM Source Node Identifier";
CM_ SG_ 1342 NMCommandCode_SGU "NM Control Bit Vector - Repeat Message Request";
CM_ SG_ 1342 NMSleepFlag_SGU "NM Control Bit Vector - NM Coordinator ID";
CM_ BO_ 1325 "NM Message";
CM_ SG_ 1325 Destination_PFSU "NM Source Node Identifier";
CM_ SG_ 1325 NMCommandCode_PFSU "NM Control Bit Vector - Repeat Message Request";
CM_ SG_ 1325 NMSleepFlag_PFSU "NM Control Bit Vector - NM Coordinator ID";
CM_ BO_ 1348 "NM Message";
CM_ SG_ 1348 Destination_ALBCU "NM Source Node Identifier";
CM_ SG_ 1348 NMCommandCode_ALBCU "NM Control Bit Vector - Repeat Message Request";
CM_ SG_ 1348 NMSleepFlag_ALBCU "NM Control Bit Vector - NM Coordinator ID";
CM_ BO_ 1369 "NM Message";
CM_ SG_ 1369 Destination_DSAU "NM Source Node Identifier";
CM_ SG_ 1369 NMCommandCode_DSAU "NM Control Bit Vector - Repeat Message Request";
CM_ SG_ 1369 NMSleepFlag_DSAU "NM Control Bit Vector - NM Coordinator ID";
CM_ BO_ 1288 "NM Message";
CM_ SG_ 1288 Destination_SWRC "NM Source Node Identifier";
CM_ SG_ 1288 NMCommandCode_SWRC "NM Control Bit Vector - Repeat Message Request";
CM_ SG_ 1288 NMSleepFlag_SWRC "NM Control Bit Vector - NM Coordinator ID";
CM_ BO_ 1322 "NM Message";
CM_ SG_ 1322 Destination_SHVU_FR "NM Source Node Identifier";
CM_ SG_ 1322 NMCommandCode_SHVU_FR "NM Control Bit Vector - Repeat Message Request";
CM_ SG_ 1322 NMSleepFlag_SHVU_FR "NM Control Bit Vector - NM Coordinator ID";
CM_ BO_ 1350 "NM Message";
CM_ SG_ 1350 Destination_RCS "NM Source Node Identifier";
CM_ SG_ 1350 NMCommandCode_RCS "NM Control Bit Vector - Repeat Message Request";
CM_ SG_ 1350 NMSleepFlag_RCS "NM Control Bit Vector - NM Coordinator ID";
CM_ BO_ 1309 "NM Message";
CM_ SG_ 1309 Destination_RRPSU "NM Source Node Identifier";
CM_ SG_ 1309 NMCommandCode_RRPSU "NM Control Bit Vector - Repeat Message Request";
CM_ SG_ 1309 NMSleepFlag_RRPSU "NM Control Bit Vector - NM Coordinator ID";
CM_ BO_ 1352 "NM Message";
CM_ SG_ 1352 Destination_BLTN_CAM "NM Source Node Identifier";
CM_ SG_ 1352 NMCommandCode_BLTN_CAM "NM Control Bit Vector - Repeat Message Request";
CM_ SG_ 1352 NMSleepFlag_BLTN_CAM "NM Control Bit Vector - NM Coordinator ID";
CM_ BO_ 1287 "NM Message";
CM_ SG_ 1287 Destination_SCM "NM Source Node Identifier";
CM_ SG_ 1287 NMCommandCode_SCM "NM Control Bit Vector - Repeat Message Request";
CM_ SG_ 1287 NMSleepFlag_SCM "NM Control Bit Vector - NM Coordinator ID";
CM_ BO_ 1344 "NM Message";
CM_ SG_ 1344 Destination_DLBCU "NM Source Node Identifier";
CM_ SG_ 1344 NMCommandCode_DLBCU "NM Control Bit Vector - Repeat Message Request";
CM_ SG_ 1344 NMSleepFlag_DLBCU "NM Control Bit Vector - NM Coordinator ID";
CM_ BO_ 1364 "NM Message";
CM_ SG_ 1364 Destination_OHCL "NM Source Node Identifier";
CM_ SG_ 1364 NMCommandCode_OHCL "NM Control Bit Vector - Repeat Message Request";
CM_ SG_ 1364 NMSleepFlag_OHCL "NM Control Bit Vector - NM Coordinator ID";
CM_ BO_ 1311 "NM Message";
CM_ SG_ 1311 Destination_RWPC "NM Source Node Identifier";
CM_ SG_ 1311 NMCommandCode_RWPC "NM Control Bit Vector - Repeat Message Request";
CM_ SG_ 1311 NMSleepFlag_RWPC "NM Control Bit Vector - NM Coordinator ID";
CM_ BO_ 1333 "NM Message";
CM_ SG_ 1333 Destination_RRHV "NM Source Node Identifier";
CM_ SG_ 1333 NMCommandCode_RRHV "NM Control Bit Vector - Repeat Message Request";
CM_ SG_ 1333 NMSleepFlag_RRHV "NM Control Bit Vector - NM Coordinator ID";
CM_ BO_ 1310 "NM Message";
CM_ SG_ 1310 Destination_WPC "NM Source Node Identifier";
CM_ SG_ 1310 NMCommandCode_WPC "NM Control Bit Vector - Repeat Message Request";
CM_ SG_ 1310 NMSleepFlag_WPC "NM Control Bit Vector - NM Coordinator ID";
CM_ BO_ 1354 "NM Message";
CM_ SG_ 1354 Destination_HOD "NM Source Node Identifier";
CM_ SG_ 1354 NMCommandCode_HOD "NM Control Bit Vector - Repeat Message Request";
CM_ SG_ 1354 NMSleepFlag_HOD "NM Control Bit Vector - NM Coordinator ID";
CM_ BO_ 1363 "NM Message";
CM_ SG_ 1363 Destination_ASAU "NM Source Node Identifier";
CM_ SG_ 1363 NMCommandCode_ASAU "NM Control Bit Vector - Repeat Message Request";
CM_ SG_ 1363 NMSleepFlag_ASAU "NM Control Bit Vector - NM Coordinator ID";
BA_DEF_ BO_ "DiagState" ENUM "No","Yes" ;
BA_DEF_ BO_ "DiagResponse" ENUM "No","Yes" ;
BA_DEF_ BO_ "DiagRequest" ENUM "No","Yes" ;
BA_DEF_ BO_ "TpMessage" ENUM "No","Yes" ;
BA_DEF_ BO_ "UsrMsgIDSforwardDeviation" INT 0 100 ;
BA_DEF_ BO_ "UsrMsgIDSbackwardDeviation" INT 50 1000 ;
BA_DEF_ BO_ "GenMsgCycleTime" INT 0 2000 ;
BA_DEF_ BO_ "GenMsgStartDelayTime" INT 0 2000 ;
BA_DEF_ BO_ "GenMsgSendType" ENUM "Cyclic","NoMsgSendType" ;
BA_DEF_ BO_ "GenMsgCycleTimeFast" INT 0 500 ;
BA_DEF_ BO_ "GenMsgDelayTime" INT 0 20 ;
BA_DEF_ BO_ "GenMsgILSupport" ENUM "No","Yes" ;
BA_DEF_ BO_ "GenMsgNrOfRepetition" INT 0 3 ;
BA_DEF_ BO_ "NmMessage" ENUM "No","Yes" ;
BA_DEF_ BO_ "NWM-Botschaft" ENUM "No","Yes" ;
BA_DEF_ BO_ "TpTxIndex" INT 0 65535 ;
BA_DEF_ BO_ "VFrameFormat" ENUM "StandardCAN","ExtendedCAN","reserved","reserved","reserved","reserved","reserved","reserved","reserved","reserved","reserved","reserved","reserved","reserved","StandardCAN_FD","ExtendedCAN_FD" ;
BA_DEF_ SG_ "UserSigValidity" ENUM "B+","ACC","IG","IG1","IG2","IG3","IG1 or IG2","IG1 or IG3","Undef" ;
BA_DEF_ SG_ "TimeoutValue" STRING ;
BA_DEF_ SG_ "UsrSigPurpose" ENUM "Undef","FN","DIAG","DIAG(Req)","DIAG(Res)","DIAG(Phy)","DEV","CCP(Req)","CCP(Res)","NM","TP" ;
BA_DEF_ SG_ "GenSigStartValue" INT 0 1215752192 ;
BA_DEF_ SG_ "NetworkRequest" ENUM "Yes","No" ;
BA_DEF_ SG_ "NetworkRequestHoldingTime" INT 0 65535 ;
BA_DEF_ SG_ "Description" STRING ;
BA_DEF_ SG_ "Version" STRING ;
BA_DEF_ SG_ "GenSigEnvVarType" ENUM "Int","Float","Undef" ;
BA_DEF_ SG_ "GenSigSendType" ENUM "Cyclic","OnWrite","OnWriteWithRepetition","OnChange","OnChangeWithRepetition","IfActive","IfActiveWithRepetition","NoSigSendType","OnChangeAndIfActive","OnChangeAndIfActiveWithRepetition" ;
BA_DEF_ SG_ "GwSigLatencyTime" INT 0 65536 ;
BA_DEF_ SG_ "GwSigMissingSourceType" ENUM "Undef","OldValue","DefaultValue","InitialValue" ;
BA_DEF_ SG_ "NWM-WakeupAllowed" ENUM "<n.a.>" ;
BA_DEF_ SG_ "RoutingFactor" INT 1 1215752192 ;
BA_DEF_REL_ BU_SG_REL_ "GenSigTimeoutTime" INT 0 7000 ;
BA_DEF_DEF_ "DiagState" "No" ;
BA_DEF_DEF_ "DiagResponse" "No" ;
BA_DEF_DEF_ "DiagRequest" "No" ;
BA_DEF_DEF_ "TpMessage" "No" ;
BA_DEF_DEF_ "UsrMsgIDSforwardDeviation" 10 ;
BA_DEF_DEF_ "UsrMsgIDSbackwardDeviation" 100 ;
BA_DEF_DEF_ "GenMsgCycleTime" 200 ;
BA_DEF_DEF_ "GenMsgStartDelayTime" 0 ;
BA_DEF_DEF_ "GenMsgSendType" "NoMsgSendType" ;
BA_DEF_DEF_ "GenMsgCycleTimeFast" 40 ;
BA_DEF_DEF_ "GenMsgDelayTime" 20 ;
BA_DEF_DEF_ "GenMsgILSupport" "Yes" ;
BA_DEF_DEF_ "GenMsgNrOfRepetition" 3 ;
BA_DEF_DEF_ "NmMessage" "No" ;
BA_DEF_DEF_ "NWM-Botschaft" "No" ;
BA_DEF_DEF_ "TpTxIndex" 0 ;
BA_DEF_DEF_ "VFrameFormat" "StandardCAN" ;
BA_DEF_DEF_ "UserSigValidity" "IG" ;
BA_DEF_DEF_ "TimeoutValue" "" ;
BA_DEF_DEF_ "UsrSigPurpose" "FN" ;
BA_DEF_DEF_ "GenSigStartValue" 0 ;
BA_DEF_DEF_ "NetworkRequest" "No" ;
BA_DEF_DEF_ "NetworkRequestHoldingTime" 0 ;
BA_DEF_DEF_ "Description" "" ;
BA_DEF_DEF_ "Version" "" ;
BA_DEF_DEF_ "GenSigEnvVarType" "Undef" ;
BA_DEF_DEF_ "GenSigSendType" "NoSigSendType" ;
BA_DEF_DEF_ "GwSigLatencyTime" 40 ;
BA_DEF_DEF_ "GwSigMissingSourceType" "Undef" ;
BA_DEF_DEF_ "NWM-WakeupAllowed" "<n.a.>" ;
BA_DEF_DEF_ "RoutingFactor" 1 ;
BA_DEF_DEF_REL_ "GenSigTimeoutTime" 500 ;
BA_ "GenMsgCycleTime" BO_ 2015 0;
BA_ "GenMsgCycleTimeFast" BO_ 2015 0;
BA_ "GenMsgNrOfRepetition" BO_ 2015 0;
BA_ "DiagState" BO_ 2015 1;
BA_ "GenMsgILSupport" BO_ 2015 0;
BA_ "TpMessage" BO_ 2015 1;
BA_ "Description" SG_ 2015 GST_ALL_Byte0 "TP Index : 0";
BA_ "UsrSigPurpose" SG_ 2015 GST_ALL_Byte0 0;
BA_ "UserSigValidity" SG_ 2015 GST_ALL_Byte0 0;
BA_REL_ "GenSigTimeoutTime" BU_SG_REL_ FCS SG_ 2015 GST_ALL_Byte0 0;
BA_REL_ "GenSigTimeoutTime" BU_SG_REL_ SCM SG_ 2015 GST_ALL_Byte0 0;
BA_REL_ "GenSigTimeoutTime" BU_SG_REL_ WPC SG_ 2015 GST_ALL_Byte0 0;
BA_REL_ "GenSigTimeoutTime" BU_SG_REL_ RWPC SG_ 2015 GST_ALL_Byte0 0;
BA_REL_ "GenSigTimeoutTime" BU_SG_REL_ PSB SG_ 2015 GST_ALL_Byte0 0;
BA_REL_ "GenSigTimeoutTime" BU_SG_REL_ SLB SG_ 2015 GST_ALL_Byte0 0;
BA_REL_ "GenSigTimeoutTime" BU_SG_REL_ ARS SG_ 2015 GST_ALL_Byte0 0;
BA_REL_ "GenSigTimeoutTime" BU_SG_REL_ SWRC SG_ 2015 GST_ALL_Byte0 0;
BA_REL_ "GenSigTimeoutTime" BU_SG_REL_ APSU SG_ 2015 GST_ALL_Byte0 0;
BA_REL_ "GenSigTimeoutTime" BU_SG_REL_ RLHV SG_ 2015 GST_ALL_Byte0 0;
BA_REL_ "GenSigTimeoutTime" BU_SG_REL_ RRHV SG_ 2015 GST_ALL_Byte0 0;
BA_REL_ "GenSigTimeoutTime" BU_SG_REL_ SHVU_FR SG_ 2015 GST_ALL_Byte0 0;
BA_REL_ "GenSigTimeoutTime" BU_SG_REL_ SHVU_RR SG_ 2015 GST_ALL_Byte0 0;
BA_REL_ "GenSigTimeoutTime" BU_SG_REL_ DPSU SG_ 2015 GST_ALL_Byte0 0;
BA_REL_ "GenSigTimeoutTime" BU_SG_REL_ DLBCU SG_ 2015 GST_ALL_Byte0 0;
BA_REL_ "GenSigTimeoutTime" BU_SG_REL_ PFSU SG_ 2015 GST_ALL_Byte0 0;
BA_REL_ "GenSigTimeoutTime" BU_SG_REL_ RCS SG_ 2015 GST_ALL_Byte0 0;
BA_REL_ "GenSigTimeoutTime" BU_SG_REL_ RRPSU SG_ 2015 GST_ALL_Byte0 0;
BA_REL_ "GenSigTimeoutTime" BU_SG_REL_ RLPSU SG_ 2015 GST_ALL_Byte0 0;
BA_REL_ "GenSigTimeoutTime" BU_SG_REL_ HOD SG_ 2015 GST_ALL_Byte0 0;
BA_REL_ "GenSigTimeoutTime" BU_SG_REL_ ATS SG_ 2015 GST_ALL_Byte0 0;
BA_REL_ "GenSigTimeoutTime" BU_SG_REL_ DSAU SG_ 2015 GST_ALL_Byte0 0;
BA_REL_ "GenSigTimeoutTime" BU_SG_REL_ ASAU SG_ 2015 GST_ALL_Byte0 0;
BA_REL_ "GenSigTimeoutTime" BU_SG_REL_ RCM SG_ 2015 GST_ALL_Byte0 0;
BA_REL_ "GenSigTimeoutTime" BU_SG_REL_ EMCU SG_ 2015 GST_ALL_Byte0 0;
BA_REL_ "GenSigTimeoutTime" BU_SG_REL_ SGU SG_ 2015 GST_ALL_Byte0 0;
BA_REL_ "GenSigTimeoutTime" BU_SG_REL_ ALBCU SG_ 2015 GST_ALL_Byte0 0;
BA_REL_ "GenSigTimeoutTime" BU_SG_REL_ WPC2 SG_ 2015 GST_ALL_Byte0 0;
BA_ "NetworkRequest" SG_ 2015 GST_ALL_Byte0 0;
BA_ "NetworkRequestHoldingTime" SG_ 2015 GST_ALL_Byte0 5000;
BA_ "Version" SG_ 2015 GST_ALL_Byte0 "22.06.01";
BA_ "Description" SG_ 2015 GST_ALL_Byte2 "TP Index : 0";
BA_ "UsrSigPurpose" SG_ 2015 GST_ALL_Byte2 0;
BA_ "UserSigValidity" SG_ 2015 GST_ALL_Byte2 0;
BA_REL_ "GenSigTimeoutTime" BU_SG_REL_ FCS SG_ 2015 GST_ALL_Byte2 0;
BA_REL_ "GenSigTimeoutTime" BU_SG_REL_ SCM SG_ 2015 GST_ALL_Byte2 0;
BA_REL_ "GenSigTimeoutTime" BU_SG_REL_ WPC SG_ 2015 GST_ALL_Byte2 0;
BA_REL_ "GenSigTimeoutTime" BU_SG_REL_ RWPC SG_ 2015 GST_ALL_Byte2 0;
BA_REL_ "GenSigTimeoutTime" BU_SG_REL_ PSB SG_ 2015 GST_ALL_Byte2 0;
BA_REL_ "GenSigTimeoutTime" BU_SG_REL_ SLB SG_ 2015 GST_ALL_Byte2 0;
BA_REL_ "GenSigTimeoutTime" BU_SG_REL_ ARS SG_ 2015 GST_ALL_Byte2 0;
BA_REL_ "GenSigTimeoutTime" BU_SG_REL_ SWRC SG_ 2015 GST_ALL_Byte2 0;
BA_REL_ "GenSigTimeoutTime" BU_SG_REL_ APSU SG_ 2015 GST_ALL_Byte2 0;
BA_REL_ "GenSigTimeoutTime" BU_SG_REL_ RLHV SG_ 2015 GST_ALL_Byte2 0;
BA_REL_ "GenSigTimeoutTime" BU_SG_REL_ RRHV SG_ 2015 GST_ALL_Byte2 0;
BA_REL_ "GenSigTimeoutTime" BU_SG_REL_ SHVU_FR SG_ 2015 GST_ALL_Byte2 0;
BA_REL_ "GenSigTimeoutTime" BU_SG_REL_ SHVU_RR SG_ 2015 GST_ALL_Byte2 0;
BA_REL_ "GenSigTimeoutTime" BU_SG_REL_ DPSU SG_ 2015 GST_ALL_Byte2 0;
BA_REL_ "GenSigTimeoutTime" BU_SG_REL_ DLBCU SG_ 2015 GST_ALL_Byte2 0;
BA_REL_ "GenSigTimeoutTime" BU_SG_REL_ PFSU SG_ 2015 GST_ALL_Byte2 0;
BA_REL_ "GenSigTimeoutTime" BU_SG_REL_ RCS SG_ 2015 GST_ALL_Byte2 0;
BA_REL_ "GenSigTimeoutTime" BU_SG_REL_ RRPSU SG_ 2015 GST_ALL_Byte2 0;
BA_REL_ "GenSigTimeoutTime" BU_SG_REL_ RLPSU SG_ 2015 GST_ALL_Byte2 0;
BA_REL_ "GenSigTimeoutTime" BU_SG_REL_ HOD SG_ 2015 GST_ALL_Byte2 0;
BA_REL_ "GenSigTimeoutTime" BU_SG_REL_ ATS SG_ 2015 GST_ALL_Byte2 0;
BA_REL_ "GenSigTimeoutTime" BU_SG_REL_ DSAU SG_ 2015 GST_ALL_Byte2 0;
BA_REL_ "GenSigTimeoutTime" BU_SG_REL_ ASAU SG_ 2015 GST_ALL_Byte2 0;
BA_REL_ "GenSigTimeoutTime" BU_SG_REL_ RCM SG_ 2015 GST_ALL_Byte2 0;
BA_REL_ "GenSigTimeoutTime" BU_SG_REL_ EMCU SG_ 2015 GST_ALL_Byte2 0;
BA_REL_ "GenSigTimeoutTime" BU_SG_REL_ SGU SG_ 2015 GST_ALL_Byte2 0;
BA_REL_ "GenSigTimeoutTime" BU_SG_REL_ ALBCU SG_ 2015 GST_ALL_Byte2 0;
BA_REL_ "GenSigTimeoutTime" BU_SG_REL_ WPC2 SG_ 2015 GST_ALL_Byte2 0;
BA_ "NetworkRequest" SG_ 2015 GST_ALL_Byte2 0;
BA_ "NetworkRequestHoldingTime" SG_ 2015 GST_ALL_Byte2 5000;
BA_ "Version" SG_ 2015 GST_ALL_Byte2 "22.06.01";
BA_ "Description" SG_ 2015 GST_ALL_Byte3 "TP Index : 0";
BA_ "UsrSigPurpose" SG_ 2015 GST_ALL_Byte3 0;
BA_ "UserSigValidity" SG_ 2015 GST_ALL_Byte3 0;
BA_REL_ "GenSigTimeoutTime" BU_SG_REL_ FCS SG_ 2015 GST_ALL_Byte3 0;
BA_REL_ "GenSigTimeoutTime" BU_SG_REL_ SCM SG_ 2015 GST_ALL_Byte3 0;
BA_REL_ "GenSigTimeoutTime" BU_SG_REL_ WPC SG_ 2015 GST_ALL_Byte3 0;
BA_REL_ "GenSigTimeoutTime" BU_SG_REL_ RWPC SG_ 2015 GST_ALL_Byte3 0;
BA_REL_ "GenSigTimeoutTime" BU_SG_REL_ PSB SG_ 2015 GST_ALL_Byte3 0;
BA_REL_ "GenSigTimeoutTime" BU_SG_REL_ SLB SG_ 2015 GST_ALL_Byte3 0;
BA_REL_ "GenSigTimeoutTime" BU_SG_REL_ ARS SG_ 2015 GST_ALL_Byte3 0;
BA_REL_ "GenSigTimeoutTime" BU_SG_REL_ SWRC SG_ 2015 GST_ALL_Byte3 0;
BA_REL_ "GenSigTimeoutTime" BU_SG_REL_ APSU SG_ 2015 GST_ALL_Byte3 0;
BA_REL_ "GenSigTimeoutTime" BU_SG_REL_ RLHV SG_ 2015 GST_ALL_Byte3 0;
BA_REL_ "GenSigTimeoutTime" BU_SG_REL_ RRHV SG_ 2015 GST_ALL_Byte3 0;
BA_REL_ "GenSigTimeoutTime" BU_SG_REL_ SHVU_FR SG_ 2015 GST_ALL_Byte3 0;
BA_REL_ "GenSigTimeoutTime" BU_SG_REL_ SHVU_RR SG_ 2015 GST_ALL_Byte3 0;
BA_REL_ "GenSigTimeoutTime" BU_SG_REL_ DPSU SG_ 2015 GST_ALL_Byte3 0;
BA_REL_ "GenSigTimeoutTime" BU_SG_REL_ DLBCU SG_ 2015 GST_ALL_Byte3 0;
BA_REL_ "GenSigTimeoutTime" BU_SG_REL_ PFSU SG_ 2015 GST_ALL_Byte3 0;
BA_REL_ "GenSigTimeoutTime" BU_SG_REL_ RCS SG_ 2015 GST_ALL_Byte3 0;
BA_REL_ "GenSigTimeoutTime" BU_SG_REL_ RRPSU SG_ 2015 GST_ALL_Byte3 0;
BA_REL_ "GenSigTimeoutTime" BU_SG_REL_ RLPSU SG_ 2015 GST_ALL_Byte3 0;
BA_REL_ "GenSigTimeoutTime" BU_SG_REL_ HOD SG_ 2015 GST_ALL_Byte3 0;
BA_REL_ "GenSigTimeoutTime" BU_SG_REL_ ATS SG_ 2015 GST_ALL_Byte3 0;
BA_REL_ "GenSigTimeoutTime" BU_SG_REL_ DSAU SG_ 2015 GST_ALL_Byte3 0;
BA_REL_ "GenSigTimeoutTime" BU_SG_REL_ ASAU SG_ 2015 GST_ALL_Byte3 0;
BA_REL_ "GenSigTimeoutTime" BU_SG_REL_ RCM SG_ 2015 GST_ALL_Byte3 0;
BA_REL_ "GenSigTimeoutTime" BU_SG_REL_ EMCU SG_ 2015 GST_ALL_Byte3 0;
BA_REL_ "GenSigTimeoutTime" BU_SG_REL_ SGU SG_ 2015 GST_ALL_Byte3 0;
BA_REL_ "GenSigTimeoutTime" BU_SG_REL_ ALBCU SG_ 2015 GST_ALL_Byte3 0;
BA_REL_ "GenSigTimeoutTime" BU_SG_REL_ WPC2 SG_ 2015 GST_ALL_Byte3 0;
BA_ "NetworkRequest" SG_ 2015 GST_ALL_Byte3 0;
BA_ "NetworkRequestHoldingTime" SG_ 2015 GST_ALL_Byte3 5000;
BA_ "Version" SG_ 2015 GST_ALL_Byte3 "22.06.01";
BA_ "Description" SG_ 2015 GST_ALL_Byte4 "TP Index : 0";
BA_ "UsrSigPurpose" SG_ 2015 GST_ALL_Byte4 0;
BA_ "UserSigValidity" SG_ 2015 GST_ALL_Byte4 0;
BA_REL_ "GenSigTimeoutTime" BU_SG_REL_ FCS SG_ 2015 GST_ALL_Byte4 0;
BA_REL_ "GenSigTimeoutTime" BU_SG_REL_ SCM SG_ 2015 GST_ALL_Byte4 0;
BA_REL_ "GenSigTimeoutTime" BU_SG_REL_ WPC SG_ 2015 GST_ALL_Byte4 0;
BA_REL_ "GenSigTimeoutTime" BU_SG_REL_ RWPC SG_ 2015 GST_ALL_Byte4 0;
BA_REL_ "GenSigTimeoutTime" BU_SG_REL_ PSB SG_ 2015 GST_ALL_Byte4 0;
BA_REL_ "GenSigTimeoutTime" BU_SG_REL_ SLB SG_ 2015 GST_ALL_Byte4 0;
BA_REL_ "GenSigTimeoutTime" BU_SG_REL_ ARS SG_ 2015 GST_ALL_Byte4 0;
BA_REL_ "GenSigTimeoutTime" BU_SG_REL_ SWRC SG_ 2015 GST_ALL_Byte4 0;
BA_REL_ "GenSigTimeoutTime" BU_SG_REL_ APSU SG_ 2015 GST_ALL_Byte4 0;
BA_REL_ "GenSigTimeoutTime" BU_SG_REL_ RLHV SG_ 2015 GST_ALL_Byte4 0;
BA_REL_ "GenSigTimeoutTime" BU_SG_REL_ RRHV SG_ 2015 GST_ALL_Byte4 0;
BA_REL_ "GenSigTimeoutTime" BU_SG_REL_ SHVU_FR SG_ 2015 GST_ALL_Byte4 0;
BA_REL_ "GenSigTimeoutTime" BU_SG_REL_ SHVU_RR SG_ 2015 GST_ALL_Byte4 0;
BA_REL_ "GenSigTimeoutTime" BU_SG_REL_ DPSU SG_ 2015 GST_ALL_Byte4 0;
BA_REL_ "GenSigTimeoutTime" BU_SG_REL_ DLBCU SG_ 2015 GST_ALL_Byte4 0;
BA_REL_ "GenSigTimeoutTime" BU_SG_REL_ PFSU SG_ 2015 GST_ALL_Byte4 0;
BA_REL_ "GenSigTimeoutTime" BU_SG_REL_ RCS SG_ 2015 GST_ALL_Byte4 0;
BA_REL_ "GenSigTimeoutTime" BU_SG_REL_ RRPSU SG_ 2015 GST_ALL_Byte4 0;
BA_REL_ "GenSigTimeoutTime" BU_SG_REL_ RLPSU SG_ 2015 GST_ALL_Byte4 0;
BA_REL_ "GenSigTimeoutTime" BU_SG_REL_ HOD SG_ 2015 GST_ALL_Byte4 0;
BA_REL_ "GenSigTimeoutTime" BU_SG_REL_ ATS SG_ 2015 GST_ALL_Byte4 0;
BA_REL_ "GenSigTimeoutTime" BU_SG_REL_ DSAU SG_ 2015 GST_ALL_Byte4 0;
BA_REL_ "GenSigTimeoutTime" BU_SG_REL_ ASAU SG_ 2015 GST_ALL_Byte4 0;
BA_REL_ "GenSigTimeoutTime" BU_SG_REL_ RCM SG_ 2015 GST_ALL_Byte4 0;
BA_REL_ "GenSigTimeoutTime" BU_SG_REL_ EMCU SG_ 2015 GST_ALL_Byte4 0;
BA_REL_ "GenSigTimeoutTime" BU_SG_REL_ SGU SG_ 2015 GST_ALL_Byte4 0;
BA_REL_ "GenSigTimeoutTime" BU_SG_REL_ ALBCU SG_ 2015 GST_ALL_Byte4 0;
BA_REL_ "GenSigTimeoutTime" BU_SG_REL_ WPC2 SG_ 2015 GST_ALL_Byte4 0;
BA_ "NetworkRequest" SG_ 2015 GST_ALL_Byte4 0;
BA_ "NetworkRequestHoldingTime" SG_ 2015 GST_ALL_Byte4 5000;
BA_ "Version" SG_ 2015 GST_ALL_Byte4 "22.06.01";
BA_ "Description" SG_ 2015 GST_ALL_Byte5 "TP Index : 0";
BA_ "UsrSigPurpose" SG_ 2015 GST_ALL_Byte5 0;
BA_ "UserSigValidity" SG_ 2015 GST_ALL_Byte5 0;
BA_REL_ "GenSigTimeoutTime" BU_SG_REL_ FCS SG_ 2015 GST_ALL_Byte5 0;
BA_REL_ "GenSigTimeoutTime" BU_SG_REL_ SCM SG_ 2015 GST_ALL_Byte5 0;
BA_REL_ "GenSigTimeoutTime" BU_SG_REL_ WPC SG_ 2015 GST_ALL_Byte5 0;
BA_REL_ "GenSigTimeoutTime" BU_SG_REL_ RWPC SG_ 2015 GST_ALL_Byte5 0;
BA_REL_ "GenSigTimeoutTime" BU_SG_REL_ PSB SG_ 2015 GST_ALL_Byte5 0;
BA_REL_ "GenSigTimeoutTime" BU_SG_REL_ SLB SG_ 2015 GST_ALL_Byte5 0;
BA_REL_ "GenSigTimeoutTime" BU_SG_REL_ ARS SG_ 2015 GST_ALL_Byte5 0;
BA_REL_ "GenSigTimeoutTime" BU_SG_REL_ SWRC SG_ 2015 GST_ALL_Byte5 0;
BA_REL_ "GenSigTimeoutTime" BU_SG_REL_ APSU SG_ 2015 GST_ALL_Byte5 0;
BA_REL_ "GenSigTimeoutTime" BU_SG_REL_ RLHV SG_ 2015 GST_ALL_Byte5 0;
BA_REL_ "GenSigTimeoutTime" BU_SG_REL_ RRHV SG_ 2015 GST_ALL_Byte5 0;
BA_REL_ "GenSigTimeoutTime" BU_SG_REL_ SHVU_FR SG_ 2015 GST_ALL_Byte5 0;
BA_REL_ "GenSigTimeoutTime" BU_SG_REL_ SHVU_RR SG_ 2015 GST_ALL_Byte5 0;
BA_REL_ "GenSigTimeoutTime" BU_SG_REL_ DPSU SG_ 2015 GST_ALL_Byte5 0;
BA_REL_ "GenSigTimeoutTime" BU_SG_REL_ DLBCU SG_ 2015 GST_ALL_Byte5 0;
BA_REL_ "GenSigTimeoutTime" BU_SG_REL_ PFSU SG_ 2015 GST_ALL_Byte5 0;
BA_REL_ "GenSigTimeoutTime" BU_SG_REL_ RCS SG_ 2015 GST_ALL_Byte5 0;
BA_REL_ "GenSigTimeoutTime" BU_SG_REL_ RRPSU SG_ 2015 GST_ALL_Byte5 0;
BA_REL_ "GenSigTimeoutTime" BU_SG_REL_ RLPSU SG_ 2015 GST_ALL_Byte5 0;
BA_REL_ "GenSigTimeoutTime" BU_SG_REL_ HOD SG_ 2015 GST_ALL_Byte5 0;
BA_REL_ "GenSigTimeoutTime" BU_SG_REL_ ATS SG_ 2015 GST_ALL_Byte5 0;
BA_REL_ "GenSigTimeoutTime" BU_SG_REL_ DSAU SG_ 2015 GST_ALL_Byte5 0;
BA_REL_ "GenSigTimeoutTime" BU_SG_REL_ ASAU SG_ 2015 GST_ALL_Byte5 0;
BA_REL_ "GenSigTimeoutTime" BU_SG_REL_ RCM SG_ 2015 GST_ALL_Byte5 0;
BA_REL_ "GenSigTimeoutTime" BU_SG_REL_ EMCU SG_ 2015 GST_ALL_Byte5 0;
BA_REL_ "GenSigTimeoutTime" BU_SG_REL_ SGU SG_ 2015 GST_ALL_Byte5 0;
BA_REL_ "GenSigTimeoutTime" BU_SG_REL_ ALBCU SG_ 2015 GST_ALL_Byte5 0;
BA_REL_ "GenSigTimeoutTime" BU_SG_REL_ WPC2 SG_ 2015 GST_ALL_Byte5 0;
BA_ "NetworkRequest" SG_ 2015 GST_ALL_Byte5 0;
BA_ "NetworkRequestHoldingTime" SG_ 2015 GST_ALL_Byte5 5000;
BA_ "Version" SG_ 2015 GST_ALL_Byte5 "22.06.01";
BA_ "Description" SG_ 2015 GST_ALL_Byte6 "TP Index : 0";
BA_ "UsrSigPurpose" SG_ 2015 GST_ALL_Byte6 0;
BA_ "UserSigValidity" SG_ 2015 GST_ALL_Byte6 0;
BA_REL_ "GenSigTimeoutTime" BU_SG_REL_ FCS SG_ 2015 GST_ALL_Byte6 0;
BA_REL_ "GenSigTimeoutTime" BU_SG_REL_ SCM SG_ 2015 GST_ALL_Byte6 0;
BA_REL_ "GenSigTimeoutTime" BU_SG_REL_ WPC SG_ 2015 GST_ALL_Byte6 0;
BA_REL_ "GenSigTimeoutTime" BU_SG_REL_ RWPC SG_ 2015 GST_ALL_Byte6 0;
BA_REL_ "GenSigTimeoutTime" BU_SG_REL_ PSB SG_ 2015 GST_ALL_Byte6 0;
BA_REL_ "GenSigTimeoutTime" BU_SG_REL_ SLB SG_ 2015 GST_ALL_Byte6 0;
BA_REL_ "GenSigTimeoutTime" BU_SG_REL_ ARS SG_ 2015 GST_ALL_Byte6 0;
BA_REL_ "GenSigTimeoutTime" BU_SG_REL_ SWRC SG_ 2015 GST_ALL_Byte6 0;
BA_REL_ "GenSigTimeoutTime" BU_SG_REL_ APSU SG_ 2015 GST_ALL_Byte6 0;
BA_REL_ "GenSigTimeoutTime" BU_SG_REL_ RLHV SG_ 2015 GST_ALL_Byte6 0;
BA_REL_ "GenSigTimeoutTime" BU_SG_REL_ RRHV SG_ 2015 GST_ALL_Byte6 0;
BA_REL_ "GenSigTimeoutTime" BU_SG_REL_ SHVU_FR SG_ 2015 GST_ALL_Byte6 0;
BA_REL_ "GenSigTimeoutTime" BU_SG_REL_ SHVU_RR SG_ 2015 GST_ALL_Byte6 0;
BA_REL_ "GenSigTimeoutTime" BU_SG_REL_ DPSU SG_ 2015 GST_ALL_Byte6 0;
BA_REL_ "GenSigTimeoutTime" BU_SG_REL_ DLBCU SG_ 2015 GST_ALL_Byte6 0;
BA_REL_ "GenSigTimeoutTime" BU_SG_REL_ PFSU SG_ 2015 GST_ALL_Byte6 0;
BA_REL_ "GenSigTimeoutTime" BU_SG_REL_ RCS SG_ 2015 GST_ALL_Byte6 0;
BA_REL_ "GenSigTimeoutTime" BU_SG_REL_ RRPSU SG_ 2015 GST_ALL_Byte6 0;
BA_REL_ "GenSigTimeoutTime" BU_SG_REL_ RLPSU SG_ 2015 GST_ALL_Byte6 0;
BA_REL_ "GenSigTimeoutTime" BU_SG_REL_ HOD SG_ 2015 GST_ALL_Byte6 0;
BA_REL_ "GenSigTimeoutTime" BU_SG_REL_ ATS SG_ 2015 GST_ALL_Byte6 0;
BA_REL_ "GenSigTimeoutTime" BU_SG_REL_ DSAU SG_ 2015 GST_ALL_Byte6 0;
BA_REL_ "GenSigTimeoutTime" BU_SG_REL_ ASAU SG_ 2015 GST_ALL_Byte6 0;
BA_REL_ "GenSigTimeoutTime" BU_SG_REL_ RCM SG_ 2015 GST_ALL_Byte6 0;
BA_REL_ "GenSigTimeoutTime" BU_SG_REL_ EMCU SG_ 2015 GST_ALL_Byte6 0;
BA_REL_ "GenSigTimeoutTime" BU_SG_REL_ SGU SG_ 2015 GST_ALL_Byte6 0;
BA_REL_ "GenSigTimeoutTime" BU_SG_REL_ ALBCU SG_ 2015 GST_ALL_Byte6 0;
BA_REL_ "GenSigTimeoutTime" BU_SG_REL_ WPC2 SG_ 2015 GST_ALL_Byte6 0;
BA_ "NetworkRequest" SG_ 2015 GST_ALL_Byte6 0;
BA_ "NetworkRequestHoldingTime" SG_ 2015 GST_ALL_Byte6 5000;
BA_ "Version" SG_ 2015 GST_ALL_Byte6 "22.06.01";
BA_ "Description" SG_ 2015 GST_ALL_Byte7 "TP Index : 0";
BA_ "UsrSigPurpose" SG_ 2015 GST_ALL_Byte7 0;
BA_ "UserSigValidity" SG_ 2015 GST_ALL_Byte7 0;
BA_REL_ "GenSigTimeoutTime" BU_SG_REL_ FCS SG_ 2015 GST_ALL_Byte7 0;
BA_REL_ "GenSigTimeoutTime" BU_SG_REL_ SCM SG_ 2015 GST_ALL_Byte7 0;
BA_REL_ "GenSigTimeoutTime" BU_SG_REL_ WPC SG_ 2015 GST_ALL_Byte7 0;
BA_REL_ "GenSigTimeoutTime" BU_SG_REL_ RWPC SG_ 2015 GST_ALL_Byte7 0;
BA_REL_ "GenSigTimeoutTime" BU_SG_REL_ PSB SG_ 2015 GST_ALL_Byte7 0;
BA_REL_ "GenSigTimeoutTime" BU_SG_REL_ SLB SG_ 2015 GST_ALL_Byte7 0;
BA_REL_ "GenSigTimeoutTime" BU_SG_REL_ ARS SG_ 2015 GST_ALL_Byte7 0;
BA_REL_ "GenSigTimeoutTime" BU_SG_REL_ SWRC SG_ 2015 GST_ALL_Byte7 0;
BA_REL_ "GenSigTimeoutTime" BU_SG_REL_ APSU SG_ 2015 GST_ALL_Byte7 0;
BA_REL_ "GenSigTimeoutTime" BU_SG_REL_ RLHV SG_ 2015 GST_ALL_Byte7 0;
BA_REL_ "GenSigTimeoutTime" BU_SG_REL_ RRHV SG_ 2015 GST_ALL_Byte7 0;
BA_REL_ "GenSigTimeoutTime" BU_SG_REL_ SHVU_FR SG_ 2015 GST_ALL_Byte7 0;
BA_REL_ "GenSigTimeoutTime" BU_SG_REL_ SHVU_RR SG_ 2015 GST_ALL_Byte7 0;
BA_REL_ "GenSigTimeoutTime" BU_SG_REL_ DPSU SG_ 2015 GST_ALL_Byte7 0;
BA_REL_ "GenSigTimeoutTime" BU_SG_REL_ DLBCU SG_ 2015 GST_ALL_Byte7 0;
BA_REL_ "GenSigTimeoutTime" BU_SG_REL_ PFSU SG_ 2015 GST_ALL_Byte7 0;
BA_REL_ "GenSigTimeoutTime" BU_SG_REL_ RCS SG_ 2015 GST_ALL_Byte7 0;
BA_REL_ "GenSigTimeoutTime" BU_SG_REL_ RRPSU SG_ 2015 GST_ALL_Byte7 0;
BA_REL_ "GenSigTimeoutTime" BU_SG_REL_ RLPSU SG_ 2015 GST_ALL_Byte7 0;
BA_REL_ "GenSigTimeoutTime" BU_SG_REL_ HOD SG_ 2015 GST_ALL_Byte7 0;
BA_REL_ "GenSigTimeoutTime" BU_SG_REL_ ATS SG_ 2015 GST_ALL_Byte7 0;
BA_REL_ "GenSigTimeoutTime" BU_SG_REL_ DSAU SG_ 2015 GST_ALL_Byte7 0;
BA_REL_ "GenSigTimeoutTime" BU_SG_REL_ ASAU SG_ 2015 GST_ALL_Byte7 0;
BA_REL_ "GenSigTimeoutTime" BU_SG_REL_ RCM SG_ 2015 GST_ALL_Byte7 0;
BA_REL_ "GenSigTimeoutTime" BU_SG_REL_ EMCU SG_ 2015 GST_ALL_Byte7 0;
BA_REL_ "GenSigTimeoutTime" BU_SG_REL_ SGU SG_ 2015 GST_ALL_Byte7 0;
BA_REL_ "GenSigTimeoutTime" BU_SG_REL_ ALBCU SG_ 2015 GST_ALL_Byte7 0;
BA_REL_ "GenSigTimeoutTime" BU_SG_REL_ WPC2 SG_ 2015 GST_ALL_Byte7 0;
BA_ "NetworkRequest" SG_ 2015 GST_ALL_Byte7 0;
BA_ "NetworkRequestHoldingTime" SG_ 2015 GST_ALL_Byte7 5000;
BA_ "Version" SG_ 2015 GST_ALL_Byte7 "22.06.01";
BA_ "Description" SG_ 2015 GST_ALL_Byte1 "TP Index : 0";
BA_ "UsrSigPurpose" SG_ 2015 GST_ALL_Byte1 0;
BA_ "UserSigValidity" SG_ 2015 GST_ALL_Byte1 0;
BA_REL_ "GenSigTimeoutTime" BU_SG_REL_ FCS SG_ 2015 GST_ALL_Byte1 0;
BA_REL_ "GenSigTimeoutTime" BU_SG_REL_ SCM SG_ 2015 GST_ALL_Byte1 0;
BA_REL_ "GenSigTimeoutTime" BU_SG_REL_ WPC SG_ 2015 GST_ALL_Byte1 0;
BA_REL_ "GenSigTimeoutTime" BU_SG_REL_ RWPC SG_ 2015 GST_ALL_Byte1 0;
BA_REL_ "GenSigTimeoutTime" BU_SG_REL_ PSB SG_ 2015 GST_ALL_Byte1 0;
BA_REL_ "GenSigTimeoutTime" BU_SG_REL_ SLB SG_ 2015 GST_ALL_Byte1 0;
BA_REL_ "GenSigTimeoutTime" BU_SG_REL_ ARS SG_ 2015 GST_ALL_Byte1 0;
BA_REL_ "GenSigTimeoutTime" BU_SG_REL_ SWRC SG_ 2015 GST_ALL_Byte1 0;
BA_REL_ "GenSigTimeoutTime" BU_SG_REL_ APSU SG_ 2015 GST_ALL_Byte1 0;
BA_REL_ "GenSigTimeoutTime" BU_SG_REL_ RLHV SG_ 2015 GST_ALL_Byte1 0;
BA_REL_ "GenSigTimeoutTime" BU_SG_REL_ RRHV SG_ 2015 GST_ALL_Byte1 0;
BA_REL_ "GenSigTimeoutTime" BU_SG_REL_ SHVU_FR SG_ 2015 GST_ALL_Byte1 0;
BA_REL_ "GenSigTimeoutTime" BU_SG_REL_ SHVU_RR SG_ 2015 GST_ALL_Byte1 0;
BA_REL_ "GenSigTimeoutTime" BU_SG_REL_ DPSU SG_ 2015 GST_ALL_Byte1 0;
BA_REL_ "GenSigTimeoutTime" BU_SG_REL_ DLBCU SG_ 2015 GST_ALL_Byte1 0;
BA_REL_ "GenSigTimeoutTime" BU_SG_REL_ PFSU SG_ 2015 GST_ALL_Byte1 0;
BA_REL_ "GenSigTimeoutTime" BU_SG_REL_ RCS SG_ 2015 GST_ALL_Byte1 0;
BA_REL_ "GenSigTimeoutTime" BU_SG_REL_ RRPSU SG_ 2015 GST_ALL_Byte1 0;
BA_REL_ "GenSigTimeoutTime" BU_SG_REL_ RLPSU SG_ 2015 GST_ALL_Byte1 0;
BA_REL_ "GenSigTimeoutTime" BU_SG_REL_ HOD SG_ 2015 GST_ALL_Byte1 0;
BA_REL_ "GenSigTimeoutTime" BU_SG_REL_ ATS SG_ 2015 GST_ALL_Byte1 0;
BA_REL_ "GenSigTimeoutTime" BU_SG_REL_ DSAU SG_ 2015 GST_ALL_Byte1 0;
BA_REL_ "GenSigTimeoutTime" BU_SG_REL_ ASAU SG_ 2015 GST_ALL_Byte1 0;
BA_REL_ "GenSigTimeoutTime" BU_SG_REL_ RCM SG_ 2015 GST_ALL_Byte1 0;
BA_REL_ "GenSigTimeoutTime" BU_SG_REL_ EMCU SG_ 2015 GST_ALL_Byte1 0;
BA_REL_ "GenSigTimeoutTime" BU_SG_REL_ SGU SG_ 2015 GST_ALL_Byte1 0;
BA_REL_ "GenSigTimeoutTime" BU_SG_REL_ ALBCU SG_ 2015 GST_ALL_Byte1 0;
BA_REL_ "GenSigTimeoutTime" BU_SG_REL_ WPC2 SG_ 2015 GST_ALL_Byte1 0;
BA_ "NetworkRequest" SG_ 2015 GST_ALL_Byte1 0;
BA_ "NetworkRequestHoldingTime" SG_ 2015 GST_ALL_Byte1 5000;
BA_ "Version" SG_ 2015 GST_ALL_Byte1 "22.06.01";
BA_ "GenMsgCycleTime" BO_ 1193 0;
BA_ "Description" SG_ 1193 C_PTGMNValueSet "18.08.09_";
BA_ "GenSigSendType" SG_ 1193 C_PTGMNValueSet 4;
BA_ "UserSigValidity" SG_ 1193 C_PTGMNValueSet 3;
BA_ "Version" SG_ 1193 C_PTGMNValueSet "18.09.04";
BA_ "Description" SG_ 1193 CF_AVN_PSMNValueSet "18.08.09_";
BA_ "GenSigSendType" SG_ 1193 CF_AVN_PSMNValueSet 4;
BA_ "UserSigValidity" SG_ 1193 CF_AVN_PSMNValueSet 3;
BA_REL_ "GenSigTimeoutTime" BU_SG_REL_ DPSU SG_ 1193 CF_AVN_PSMNValueSet 0;
BA_ "Version" SG_ 1193 CF_AVN_PSMNValueSet "18.09.04";
BA_ "Description" SG_ 1193 C_HfreeTrunkTgNValueSet "18.08.09_";
BA_ "GenSigSendType" SG_ 1193 C_HfreeTrunkTgNValueSet 4;
BA_ "UserSigValidity" SG_ 1193 C_HfreeTrunkTgNValueSet 3;
BA_ "Version" SG_ 1193 C_HfreeTrunkTgNValueSet "18.09.04";
BA_ "Description" SG_ 1193 CF_AVN_TrfChgSet "18.08.09_";
BA_ "GenSigSendType" SG_ 1193 CF_AVN_TrfChgSet 4;
BA_ "UserSigValidity" SG_ 1193 CF_AVN_TrfChgSet 3;
BA_ "Version" SG_ 1193 CF_AVN_TrfChgSet "18.09.04";
BA_ "Description" SG_ 1193 CF_AVN_SCMNValueSet "18.08.09_";
BA_ "GenSigSendType" SG_ 1193 CF_AVN_SCMNValueSet 4;
BA_ "UserSigValidity" SG_ 1193 CF_AVN_SCMNValueSet 3;
BA_ "Version" SG_ 1193 CF_AVN_SCMNValueSet "18.09.04";
BA_ "Description" SG_ 1193 CF_AVN_ADrUNValueSet "18.08.09_";
BA_ "GenSigSendType" SG_ 1193 CF_AVN_ADrUNValueSet 4;
BA_ "UserSigValidity" SG_ 1193 CF_AVN_ADrUNValueSet 3;
BA_ "Version" SG_ 1193 CF_AVN_ADrUNValueSet "18.09.04";
BA_ "Description" SG_ 1193 CF_AVN_OTTurnNValueSet "18.08.09_";
BA_ "GenSigSendType" SG_ 1193 CF_AVN_OTTurnNValueSet 4;
BA_ "UserSigValidity" SG_ 1193 CF_AVN_OTTurnNValueSet 3;
BA_ "Version" SG_ 1193 CF_AVN_OTTurnNValueSet "18.09.04";
BA_ "Description" SG_ 1193 CF_Gway_WPCNValueSet "18.08.09_";
BA_ "GenSigSendType" SG_ 1193 CF_Gway_WPCNValueSet 4;
BA_ "UserSigValidity" SG_ 1193 CF_Gway_WPCNValueSet 3;
BA_REL_ "GenSigTimeoutTime" BU_SG_REL_ WPC SG_ 1193 CF_Gway_WPCNValueSet 0;
BA_REL_ "GenSigTimeoutTime" BU_SG_REL_ WPC2 SG_ 1193 CF_Gway_WPCNValueSet 0;
BA_ "Version" SG_ 1193 CF_Gway_WPCNValueSet "18.09.04";
BA_ "Description" SG_ 1193 C_AVN_RearWiperNValueSet "18.08.09_";
BA_ "GenSigSendType" SG_ 1193 C_AVN_RearWiperNValueSet 4;
BA_ "UserSigValidity" SG_ 1193 C_AVN_RearWiperNValueSet 3;
BA_ "Version" SG_ 1193 C_AVN_RearWiperNValueSet "18.09.04";
BA_ "Description" SG_ 1193 C_UnlockWelocomeNValueSet "18.08.09_";
BA_ "GenSigSendType" SG_ 1193 C_UnlockWelocomeNValueSet 4;
BA_ "UserSigValidity" SG_ 1193 C_UnlockWelocomeNValueSet 3;
BA_ "Version" SG_ 1193 C_UnlockWelocomeNValueSet "18.09.04";
BA_ "Description" SG_ 1193 C_SmartWelocomeNValueSet "18.08.09_";
BA_ "GenSigSendType" SG_ 1193 C_SmartWelocomeNValueSet 4;
BA_ "UserSigValidity" SG_ 1193 C_SmartWelocomeNValueSet 3;
BA_ "Version" SG_ 1193 C_SmartWelocomeNValueSet "18.09.04";
BA_ "Description" SG_ 1193 CF_AVN_PTGSpeedNValueSet "18.08.09_";
BA_ "GenSigSendType" SG_ 1193 CF_AVN_PTGSpeedNValueSet 4;
BA_ "UserSigValidity" SG_ 1193 CF_AVN_PTGSpeedNValueSet 3;
BA_ "Version" SG_ 1193 CF_AVN_PTGSpeedNValueSet "18.09.04";
BA_ "Description" SG_ 1193 CR_Datc_DRSeatWheel_USM_Set "18.08.09_";
BA_ "GenSigSendType" SG_ 1193 CR_Datc_DRSeatWheel_USM_Set 4;
BA_ "UserSigValidity" SG_ 1193 CR_Datc_DRSeatWheel_USM_Set 3;
BA_ "Version" SG_ 1193 CR_Datc_DRSeatWheel_USM_Set "18.09.04";
BA_ "Description" SG_ 1193 CF_AVN_TTUnlockNValueSet "18.08.09_";
BA_ "GenSigSendType" SG_ 1193 CF_AVN_TTUnlockNValueSet 4;
BA_ "GenSigStartValue" SG_ 1193 CF_AVN_TTUnlockNValueSet 3;
BA_ "UserSigValidity" SG_ 1193 CF_AVN_TTUnlockNValueSet 3;
BA_ "Version" SG_ 1193 CF_AVN_TTUnlockNValueSet "18.09.04";
BA_ "Description" SG_ 1193 CF_Gway_RWPCNValueSet "18.08.09_";
BA_ "GenSigSendType" SG_ 1193 CF_Gway_RWPCNValueSet 4;
BA_ "UserSigValidity" SG_ 1193 CF_Gway_RWPCNValueSet 3;
BA_REL_ "GenSigTimeoutTime" BU_SG_REL_ RWPC SG_ 1193 CF_Gway_RWPCNValueSet 0;
BA_ "Version" SG_ 1193 CF_Gway_RWPCNValueSet "18.09.04";
BA_ "Description" SG_ 1193 CF_Avn_HAPTICWARNINGNValueSet "18.11.09_";
BA_ "GenSigSendType" SG_ 1193 CF_Avn_HAPTICWARNINGNValueSet 4;
BA_ "UserSigValidity" SG_ 1193 CF_Avn_HAPTICWARNINGNValueSet 3;
BA_ "Version" SG_ 1193 CF_Avn_HAPTICWARNINGNValueSet "18.12.01";
BA_ "Description" SG_ 1193 CR_Datc_DRSeatHeat_USM_Set "18.08.09_";
BA_ "GenSigSendType" SG_ 1193 CR_Datc_DRSeatHeat_USM_Set 4;
BA_ "UserSigValidity" SG_ 1193 CR_Datc_DRSeatHeat_USM_Set 3;
BA_ "Version" SG_ 1193 CR_Datc_DRSeatHeat_USM_Set "18.09.04";
BA_ "Description" SG_ 1193 C_WALNValueSet "18.08.09_";
BA_ "GenSigSendType" SG_ 1193 C_WALNValueSet 4;
BA_ "UserSigValidity" SG_ 1193 C_WALNValueSet 3;
BA_ "Version" SG_ 1193 C_WALNValueSet "18.09.04";
BA_ "Description" SG_ 1193 C_ApprUnlockNValue "18.08.09_";
BA_ "GenSigSendType" SG_ 1193 C_ApprUnlockNValue 4;
BA_ "UserSigValidity" SG_ 1193 C_ApprUnlockNValue 3;
BA_ "Version" SG_ 1193 C_ApprUnlockNValue "18.09.04";
BA_ "Description" SG_ 1193 CF_AVN_EscortHLNValueSet "18.08.09_";
BA_ "GenSigSendType" SG_ 1193 CF_AVN_EscortHLNValueSet 4;
BA_ "UserSigValidity" SG_ 1193 CF_AVN_EscortHLNValueSet 3;
BA_ "Version" SG_ 1193 CF_AVN_EscortHLNValueSet "18.09.04";
BA_ "GenMsgCycleTime" BO_ 491 0;
BA_ "Description" SG_ 491 CF_AVN_Roof_OprLvSet "Smart Glass(Roof) usm setting signal";
BA_ "GenSigSendType" SG_ 491 CF_AVN_Roof_OprLvSet 4;
BA_ "UserSigValidity" SG_ 491 CF_AVN_Roof_OprLvSet 3;
BA_REL_ "GenSigTimeoutTime" BU_SG_REL_ SGU SG_ 491 CF_AVN_Roof_OprLvSet 0;
BA_ "Version" SG_ 491 CF_AVN_Roof_OprLvSet "21.07.05";
BA_ "Description" SG_ 491 CF_AVN_3rdRightDoor_OptLvlSet "Smart Glass (3rd Right Door) usm set signal";
BA_ "GenSigSendType" SG_ 491 CF_AVN_3rdRightDoor_OptLvlSet 4;
BA_ "UserSigValidity" SG_ 491 CF_AVN_3rdRightDoor_OptLvlSet 3;
BA_REL_ "GenSigTimeoutTime" BU_SG_REL_ SGU SG_ 491 CF_AVN_3rdRightDoor_OptLvlSet 0;
BA_ "Version" SG_ 491 CF_AVN_3rdRightDoor_OptLvlSet "21.07.05";
BA_ "Description" SG_ 491 CF_AVN_RearDoor_OptLvlSet "Smart Glass (Rear Door) usm set signal";
BA_ "GenSigSendType" SG_ 491 CF_AVN_RearDoor_OptLvlSet 4;
BA_ "UserSigValidity" SG_ 491 CF_AVN_RearDoor_OptLvlSet 3;
BA_REL_ "GenSigTimeoutTime" BU_SG_REL_ SGU SG_ 491 CF_AVN_RearDoor_OptLvlSet 0;
BA_ "Version" SG_ 491 CF_AVN_RearDoor_OptLvlSet "21.07.05";
BA_ "Description" SG_ 491 CF_AVN_RollBlindOnOffSet "Related Smar Glass RollBlind On,Off for USM set signal";
BA_ "GenSigSendType" SG_ 491 CF_AVN_RollBlindOnOffSet 4;
BA_ "UserSigValidity" SG_ 491 CF_AVN_RollBlindOnOffSet 3;
BA_REL_ "GenSigTimeoutTime" BU_SG_REL_ SGU SG_ 491 CF_AVN_RollBlindOnOffSet 0;
BA_ "Version" SG_ 491 CF_AVN_RollBlindOnOffSet "21.07.07";
BA_ "Description" SG_ 491 CF_AVN_CluThmAutoSet_New "this signal is Cluster theme Auto set signal for New cluster theme";
BA_ "GenSigSendType" SG_ 491 CF_AVN_CluThmAutoSet_New 4;
BA_ "UserSigValidity" SG_ 491 CF_AVN_CluThmAutoSet_New 3;
BA_ "Version" SG_ 491 CF_AVN_CluThmAutoSet_New "21.11.07";
BA_ "Description" SG_ 491 CF_AVN_CluThmSet_New "This signal is Cluster theme large category menu select for Cluster New theme";
BA_ "GenSigSendType" SG_ 491 CF_AVN_CluThmSet_New 4;
BA_ "UserSigValidity" SG_ 491 CF_AVN_CluThmSet_New 3;
BA_ "Version" SG_ 491 CF_AVN_CluThmSet_New "21.11.07";
BA_ "Description" SG_ 491 CF_AVN_CluThmDtlSet_New "This signal is Cluster Theme small category menu select for Cluster New Theme";
BA_ "GenSigSendType" SG_ 491 CF_AVN_CluThmDtlSet_New 4;
BA_ "UserSigValidity" SG_ 491 CF_AVN_CluThmDtlSet_New 3;
BA_ "Version" SG_ 491 CF_AVN_CluThmDtlSet_New "21.11.07";
BA_ "Description" SG_ 491 CF_AVN_MdLmpAIVoiceUSMNValueSet "Voice recognition link to modd lamp set signal";
BA_ "GenSigSendType" SG_ 491 CF_AVN_MdLmpAIVoiceUSMNValueSet 4;
BA_ "UserSigValidity" SG_ 491 CF_AVN_MdLmpAIVoiceUSMNValueSet 3;
BA_ "Version" SG_ 491 CF_AVN_MdLmpAIVoiceUSMNValueSet "21.12.06";
BA_ "Description" SG_ 491 CF_AVN_2ndLeftDoor_OptLvSet "Smart Glass (2nd Left Door) Usm set signal";
BA_ "GenSigSendType" SG_ 491 CF_AVN_2ndLeftDoor_OptLvSet 4;
BA_ "UserSigValidity" SG_ 491 CF_AVN_2ndLeftDoor_OptLvSet 3;
BA_REL_ "GenSigTimeoutTime" BU_SG_REL_ SGU SG_ 491 CF_AVN_2ndLeftDoor_OptLvSet 0;
BA_ "Version" SG_ 491 CF_AVN_2ndLeftDoor_OptLvSet "21.07.05";
BA_ "Description" SG_ 491 CF_AVN_DWL_SelectNvalueSet "Dynamic welcome light usm set signal";
BA_ "GenSigSendType" SG_ 491 CF_AVN_DWL_SelectNvalueSet 4;
BA_ "UserSigValidity" SG_ 491 CF_AVN_DWL_SelectNvalueSet 3;
BA_ "Version" SG_ 491 CF_AVN_DWL_SelectNvalueSet "22.05.02";
BA_ "Description" SG_ 491 CF_AVN_FrArmRestHeatNValueSet "Set on/off the function of the front armrest heating system connected to the front seat heating system.";
BA_ "GenSigSendType" SG_ 491 CF_AVN_FrArmRestHeatNValueSet 4;
BA_ "UserSigValidity" SG_ 491 CF_AVN_FrArmRestHeatNValueSet 3;
BA_REL_ "GenSigTimeoutTime" BU_SG_REL_ FCS SG_ 491 CF_AVN_FrArmRestHeatNValueSet 0;
BA_ "Version" SG_ 491 CF_AVN_FrArmRestHeatNValueSet "22.03.01";
BA_ "Description" SG_ 491 CF_AVN_RrArmRestHeatNValueSet "Set on/off the function of the rear armrest heating system connected to the rear seat heating system.";
BA_ "GenSigSendType" SG_ 491 CF_AVN_RrArmRestHeatNValueSet 4;
BA_ "UserSigValidity" SG_ 491 CF_AVN_RrArmRestHeatNValueSet 3;
BA_REL_ "GenSigTimeoutTime" BU_SG_REL_ FCS SG_ 491 CF_AVN_RrArmRestHeatNValueSet 0;
BA_ "Version" SG_ 491 CF_AVN_RrArmRestHeatNValueSet "22.03.01";
BA_ "Description" SG_ 491 CF_Gway_WPCAnimationNvalueSet "USM set signal for wireless charging indicator";
BA_ "GenSigSendType" SG_ 491 CF_Gway_WPCAnimationNvalueSet 4;
BA_ "UserSigValidity" SG_ 491 CF_Gway_WPCAnimationNvalueSet 3;
BA_REL_ "GenSigTimeoutTime" BU_SG_REL_ WPC SG_ 491 CF_Gway_WPCAnimationNvalueSet 0;
BA_ "Version" SG_ 491 CF_Gway_WPCAnimationNvalueSet "22.04.01";
BA_ "Description" SG_ 491 USM_BtnIllumiAlwaysOnReq "USM Request for always turning on button illumination.";
BA_ "GenSigSendType" SG_ 491 USM_BtnIllumiAlwaysOnReq 4;
BA_ "UserSigValidity" SG_ 491 USM_BtnIllumiAlwaysOnReq 3;
BA_ "Version" SG_ 491 USM_BtnIllumiAlwaysOnReq "22.04.02";
BA_ "Description" SG_ 491 CF_AVN_LKAWrngVolNvalueSet "LKA Warning Volume USM Set signal";
BA_ "GenSigSendType" SG_ 491 CF_AVN_LKAWrngVolNvalueSet 4;
BA_ "UserSigValidity" SG_ 491 CF_AVN_LKAWrngVolNvalueSet 3;
BA_ "Version" SG_ 491 CF_AVN_LKAWrngVolNvalueSet "22.05.04";
BA_ "GenSigSendType" SG_ 491 DAB_IlluminationVrModeSet 4;
BA_ "UserSigValidity" SG_ 491 DAB_IlluminationVrModeSet 3;
BA_REL_ "GenSigTimeoutTime" BU_SG_REL_ SWRC SG_ 491 DAB_IlluminationVrModeSet 0;
BA_ "Version" SG_ 491 DAB_IlluminationVrModeSet "22.06.00";
BA_ "Description" SG_ 491 USM_IllAlwaysOnwithPSTNReq "USM set signal for Illumination & PSTN";
BA_ "GenSigSendType" SG_ 491 USM_IllAlwaysOnwithPSTNReq 4;
BA_ "UserSigValidity" SG_ 491 USM_IllAlwaysOnwithPSTNReq 3;
BA_ "Version" SG_ 491 USM_IllAlwaysOnwithPSTNReq "22.06.00";
BA_ "Description" SG_ 491 CF_AVN_AutoStopTimerResetSet "USM Set signal for Cluster Auto stop reset menu";
BA_ "GenSigSendType" SG_ 491 CF_AVN_AutoStopTimerResetSet 4;
BA_ "UserSigValidity" SG_ 491 CF_AVN_AutoStopTimerResetSet 3;
BA_ "Version" SG_ 491 CF_AVN_AutoStopTimerResetSet "22.06.05";
BA_ "Description" SG_ 491 CF_AVN_2ndRightDoor_OptLvSet "Smart Glass (2nd Right Door) usm set signal";
BA_ "GenSigSendType" SG_ 491 CF_AVN_2ndRightDoor_OptLvSet 4;
BA_ "UserSigValidity" SG_ 491 CF_AVN_2ndRightDoor_OptLvSet 3;
BA_REL_ "GenSigTimeoutTime" BU_SG_REL_ SGU SG_ 491 CF_AVN_2ndRightDoor_OptLvSet 0;
BA_ "Version" SG_ 491 CF_AVN_2ndRightDoor_OptLvSet "21.07.05";
BA_ "Description" SG_ 491 USM_RrCurtainSet "USM request for Rear Curtain On/Off setting";
BA_ "GenSigSendType" SG_ 491 USM_RrCurtainSet 4;
BA_ "UserSigValidity" SG_ 491 USM_RrCurtainSet 3;
BA_ "Version" SG_ 491 USM_RrCurtainSet "22.07.01";
BA_ "Description" SG_ 491 CF_AVN_3rdLeftDoor_OptLvlSet "Smart Glass (3rd left door) usm set signal";
BA_ "GenSigSendType" SG_ 491 CF_AVN_3rdLeftDoor_OptLvlSet 4;
BA_ "UserSigValidity" SG_ 491 CF_AVN_3rdLeftDoor_OptLvlSet 3;
BA_REL_ "GenSigTimeoutTime" BU_SG_REL_ SGU SG_ 491 CF_AVN_3rdLeftDoor_OptLvlSet 0;
BA_ "Version" SG_ 491 CF_AVN_3rdLeftDoor_OptLvlSet "21.07.05";
BA_ "GenMsgSendType" BO_ 1076 0;
BA_ "GenSigSendType" SG_ 1076 IAU_ProfileIDRVal 4;
BA_ "UserSigValidity" SG_ 1076 IAU_ProfileIDRVal 0;
BA_REL_ "GenSigTimeoutTime" BU_SG_REL_ WPC SG_ 1076 IAU_ProfileIDRVal 1500;
BA_REL_ "GenSigTimeoutTime" BU_SG_REL_ RWPC SG_ 1076 IAU_ProfileIDRVal 1500;
BA_REL_ "GenSigTimeoutTime" BU_SG_REL_ DPSU SG_ 1076 IAU_ProfileIDRVal 1500;
BA_REL_ "GenSigTimeoutTime" BU_SG_REL_ DLBCU SG_ 1076 IAU_ProfileIDRVal 1500;
BA_REL_ "GenSigTimeoutTime" BU_SG_REL_ RCM SG_ 1076 IAU_ProfileIDRVal 1500;
BA_REL_ "GenSigTimeoutTime" BU_SG_REL_ BLTN_CAM SG_ 1076 IAU_ProfileIDRVal 1500;
BA_REL_ "GenSigTimeoutTime" BU_SG_REL_ SGU SG_ 1076 IAU_ProfileIDRVal 1500;
BA_REL_ "GenSigTimeoutTime" BU_SG_REL_ WPC2 SG_ 1076 IAU_ProfileIDRVal 1500;
BA_ "NetworkRequest" SG_ 1076 IAU_ProfileIDRVal 0;
BA_ "NetworkRequestHoldingTime" SG_ 1076 IAU_ProfileIDRVal 5000;
BA_ "Version" SG_ 1076 IAU_ProfileIDRVal "20.05.02";
BA_ "GenSigSendType" SG_ 1076 IAU_DigitalKeyProcessingSta 4;
BA_ "UserSigValidity" SG_ 1076 IAU_DigitalKeyProcessingSta 3;
BA_ "NetworkRequest" SG_ 1076 IAU_DigitalKeyProcessingSta 0;
BA_ "NetworkRequestHoldingTime" SG_ 1076 IAU_DigitalKeyProcessingSta 5000;
BA_ "Version" SG_ 1076 IAU_DigitalKeyProcessingSta "20.11.02";
BA_ "Description" SG_ 1076 IAU_DigitalKeyExit "Digital Key USM setting Exit Condition";
BA_ "GenSigSendType" SG_ 1076 IAU_DigitalKeyExit 4;
BA_ "UserSigValidity" SG_ 1076 IAU_DigitalKeyExit 3;
BA_ "NetworkRequest" SG_ 1076 IAU_DigitalKeyExit 0;
BA_ "NetworkRequestHoldingTime" SG_ 1076 IAU_DigitalKeyExit 5000;
BA_ "Version" SG_ 1076 IAU_DigitalKeyExit "22.06.04";
BA_ "GenSigSendType" SG_ 1076 IAU_DigitalKeyEnblRVal 4;
BA_ "UserSigValidity" SG_ 1076 IAU_DigitalKeyEnblRVal 0;
BA_ "NetworkRequest" SG_ 1076 IAU_DigitalKeyEnblRVal 0;
BA_ "NetworkRequestHoldingTime" SG_ 1076 IAU_DigitalKeyEnblRVal 5000;
BA_ "Version" SG_ 1076 IAU_DigitalKeyEnblRVal "20.05.02";
BA_ "GenSigSendType" SG_ 1076 IAU_OwnerPhnRegRVal 4;
BA_ "UserSigValidity" SG_ 1076 IAU_OwnerPhnRegRVal 0;
BA_ "NetworkRequest" SG_ 1076 IAU_OwnerPhnRegRVal 0;
BA_ "NetworkRequestHoldingTime" SG_ 1076 IAU_OwnerPhnRegRVal 5000;
BA_ "Version" SG_ 1076 IAU_OwnerPhnRegRVal "20.05.02";
BA_ "GenSigSendType" SG_ 1076 IAU_NFCCard1RegRVal 4;
BA_ "UserSigValidity" SG_ 1076 IAU_NFCCard1RegRVal 0;
BA_ "NetworkRequest" SG_ 1076 IAU_NFCCard1RegRVal 0;
BA_ "NetworkRequestHoldingTime" SG_ 1076 IAU_NFCCard1RegRVal 5000;
BA_ "Version" SG_ 1076 IAU_NFCCard1RegRVal "17.12.08";
BA_ "GenSigSendType" SG_ 1076 IAU_NFCCard2RegRVal 4;
BA_ "UserSigValidity" SG_ 1076 IAU_NFCCard2RegRVal 0;
BA_ "NetworkRequest" SG_ 1076 IAU_NFCCard2RegRVal 0;
BA_ "NetworkRequestHoldingTime" SG_ 1076 IAU_NFCCard2RegRVal 5000;
BA_ "Version" SG_ 1076 IAU_NFCCard2RegRVal "17.12.08";
BA_ "Description" SG_ 1076 IAU_DISPWrng "This siganl warning from IAU

- 0x9 (WPCNFC_PreStartAuth_Success) : CLU display when workaround or LPCD Start Auth succeeded (before SSB pressed).";
BA_ "GenSigSendType" SG_ 1076 IAU_DISPWrng 4;
BA_ "UserSigValidity" SG_ 1076 IAU_DISPWrng 0;
BA_ "NetworkRequest" SG_ 1076 IAU_DISPWrng 0;
BA_ "NetworkRequestHoldingTime" SG_ 1076 IAU_DISPWrng 5000;
BA_ "Version" SG_ 1076 IAU_DISPWrng "22.06.04";
BA_ "Description" SG_ 1076 IAU_DigitalKey2Opt "This signal describe Digital Key capability";
BA_ "GenSigSendType" SG_ 1076 IAU_DigitalKey2Opt 4;
BA_ "UserSigValidity" SG_ 1076 IAU_DigitalKey2Opt 0;
BA_REL_ "GenSigTimeoutTime" BU_SG_REL_ WPC SG_ 1076 IAU_DigitalKey2Opt 1500;
BA_REL_ "GenSigTimeoutTime" BU_SG_REL_ WPC2 SG_ 1076 IAU_DigitalKey2Opt 1500;
BA_ "NetworkRequest" SG_ 1076 IAU_DigitalKey2Opt 0;
BA_ "NetworkRequestHoldingTime" SG_ 1076 IAU_DigitalKey2Opt 5000;
BA_ "Version" SG_ 1076 IAU_DigitalKey2Opt "20.08.00";
BA_ "Description" SG_ 1076 IAUwFRULearnState "This signal indicates learning process stste between IAU and FRU";
BA_ "GenSigSendType" SG_ 1076 IAUwFRULearnState 4;
BA_ "UserSigValidity" SG_ 1076 IAUwFRULearnState 0;
BA_ "NetworkRequest" SG_ 1076 IAUwFRULearnState 0;
BA_ "NetworkRequestHoldingTime" SG_ 1076 IAUwFRULearnState 5000;
BA_ "Version" SG_ 1076 IAUwFRULearnState "20.04.05";
BA_ "Description" SG_ 1076 IAUwFPMLearnState "This signal indicates learning process stste between IAU and FPM";
BA_ "GenSigSendType" SG_ 1076 IAUwFPMLearnState 4;
BA_ "UserSigValidity" SG_ 1076 IAUwFPMLearnState 0;
BA_ "NetworkRequest" SG_ 1076 IAUwFPMLearnState 0;
BA_ "NetworkRequestHoldingTime" SG_ 1076 IAUwFPMLearnState 5000;
BA_ "Version" SG_ 1076 IAUwFPMLearnState "20.04.05";
BA_ "GenMsgSendType" BO_ 1073 0;
BA_ "Description" SG_ 1073 USM_ValCmdSta "USM request value of RWPC";
BA_ "GenSigSendType" SG_ 1073 USM_ValCmdSta 4;
BA_ "UserSigValidity" SG_ 1073 USM_ValCmdSta 0;
BA_REL_ "GenSigTimeoutTime" BU_SG_REL_ ATS SG_ 1073 USM_ValCmdSta 1500;
BA_REL_ "GenSigTimeoutTime" BU_SG_REL_ CGW_CCU SG_ 1073 USM_ValCmdSta 1500;
BA_ "NetworkRequest" SG_ 1073 USM_ValCmdSta 0;
BA_ "NetworkRequestHoldingTime" SG_ 1073 USM_ValCmdSta 5000;
BA_ "Version" SG_ 1073 USM_ValCmdSta "17.11.00";
BA_ "Description" SG_ 1073 RWPC_SWVerMinor1 "Indicate the RWPC software version as follows:

- The software version is displayed in three digits.

- The Major and Minor digits are separated by '.'

- Signal values are transmitted to ASCII codes.



※ Example

RWPC_SWVerMajor1 : 0x41 (HEX) -> ASCII CODE : 'A' 

RWPC_SWVerMinor1 : 0x30 (HEX) -> ASCII CODE : '0'

RWPC_SWVerMinor2 : 0x33 (HEX) -> ASCII CODE : '3'

=> RWPC S/W Ver is displayed 'A.03'";
BA_ "GenSigSendType" SG_ 1073 RWPC_SWVerMinor1 4;
BA_ "UserSigValidity" SG_ 1073 RWPC_SWVerMinor1 0;
BA_REL_ "GenSigTimeoutTime" BU_SG_REL_ CGW_CCU SG_ 1073 RWPC_SWVerMinor1 1500;
BA_ "Version" SG_ 1073 RWPC_SWVerMinor1 "18.10.06";
BA_ "Description" SG_ 1073 WPC_PhnLftWrngRWPCSta "Warning by RWPC for User (Phone left in vehicle)";
BA_ "GenSigSendType" SG_ 1073 WPC_PhnLftWrngRWPCSta 4;
BA_ "UserSigValidity" SG_ 1073 WPC_PhnLftWrngRWPCSta 0;
BA_REL_ "GenSigTimeoutTime" BU_SG_REL_ ATS SG_ 1073 WPC_PhnLftWrngRWPCSta 1500;
BA_REL_ "GenSigTimeoutTime" BU_SG_REL_ CGW_CCU SG_ 1073 WPC_PhnLftWrngRWPCSta 1500;
BA_ "NetworkRequest" SG_ 1073 WPC_PhnLftWrngRWPCSta 0;
BA_ "NetworkRequestHoldingTime" SG_ 1073 WPC_PhnLftWrngRWPCSta 5000;
BA_ "Version" SG_ 1073 WPC_PhnLftWrngRWPCSta "19.10.02";
BA_ "Description" SG_ 1073 RWPC_SWVerMinor2 "Indicate the RWPC software version as follows:

- The software version is displayed in three digits.

- The Major and Minor digits are separated by '.'

- Signal values are transmitted to ASCII codes.



※ Example

RWPC_SWVerMajor1 : 0x41 (HEX) -> ASCII CODE : 'A' 

RWPC_SWVerMinor1 : 0x30 (HEX) -> ASCII CODE : '0'

RWPC_SWVerMinor2 : 0x33 (HEX) -> ASCII CODE : '3'

=> RWPC S/W Ver is displayed 'A.03'";
BA_ "GenSigSendType" SG_ 1073 RWPC_SWVerMinor2 4;
BA_ "UserSigValidity" SG_ 1073 RWPC_SWVerMinor2 0;
BA_REL_ "GenSigTimeoutTime" BU_SG_REL_ CGW_CCU SG_ 1073 RWPC_SWVerMinor2 1500;
BA_ "Version" SG_ 1073 RWPC_SWVerMinor2 "18.10.06";
BA_ "Description" SG_ 1073 RWPC_IndSyncVal "WPC IND ANIVATION SYNC SIGNAL";
BA_ "GenSigSendType" SG_ 1073 RWPC_IndSyncVal 4;
BA_ "TimeoutValue" SG_ 1073 RWPC_IndSyncVal "0x0";
BA_ "UserSigValidity" SG_ 1073 RWPC_IndSyncVal 3;
BA_REL_ "GenSigTimeoutTime" BU_SG_REL_ WPC SG_ 1073 RWPC_IndSyncVal 1500;
BA_REL_ "GenSigTimeoutTime" BU_SG_REL_ WPC2 SG_ 1073 RWPC_IndSyncVal 1500;
BA_ "Version" SG_ 1073 RWPC_IndSyncVal "22.04.01";
BA_ "Description" SG_ 1073 USM_ValCmdStaforATS "USM request value of RWPC for ATS";
BA_ "GenSigSendType" SG_ 1073 USM_ValCmdStaforATS 4;
BA_ "UserSigValidity" SG_ 1073 USM_ValCmdStaforATS 0;
BA_REL_ "GenSigTimeoutTime" BU_SG_REL_ ATS SG_ 1073 USM_ValCmdStaforATS 1500;
BA_ "NetworkRequest" SG_ 1073 USM_ValCmdStaforATS 0;
BA_ "NetworkRequestHoldingTime" SG_ 1073 USM_ValCmdStaforATS 5000;
BA_ "Version" SG_ 1073 USM_ValCmdStaforATS "20.07.05";
BA_ "Description" SG_ 1073 RWPC_SWVerMajor1 "Indicate the RWPC software version as follows:

- The software version is displayed in three digits.

- The Major and Minor digits are separated by '.'

- Signal values are transmitted to ASCII codes.



※ Example

RWPC_SWVerMajor1 : 0x41 (HEX) -> ASCII CODE : 'A' 

RWPC_SWVerMinor1 : 0x30 (HEX) -> ASCII CODE : '0'

RWPC_SWVerMinor2 : 0x33 (HEX) -> ASCII CODE : '3'

=> RWPC S/W Ver is displayed 'A.03'";
BA_ "GenSigSendType" SG_ 1073 RWPC_SWVerMajor1 4;
BA_ "UserSigValidity" SG_ 1073 RWPC_SWVerMajor1 0;
BA_REL_ "GenSigTimeoutTime" BU_SG_REL_ CGW_CCU SG_ 1073 RWPC_SWVerMajor1 1500;
BA_ "Version" SG_ 1073 RWPC_SWVerMajor1 "18.10.06";
BA_ "GenMsgSendType" BO_ 858 0;
BA_ "Description" SG_ 858 SBCM_AST_Crc2Val "The data area for CRC calculation is based on the data length (DLC) of the message DB.

The CRC shall be calculated over the entire data block (excluding the CRC bytes) including the user data, alive counter and Data ID 

 

- CRC Polynomial (0x1D) , Initial Value : 0x00, XOR value : 0xFF, Data ID Mode : Both, Data ID : Message ID + 0xF800 

- The initial value is for CRC calculation and the message should be sent with the calculated result value. 

The mathematical expression to 8 bit CRC polynomial is given here. G(x) = x8 + x4 + x3 + x2 + 1";
BA_ "GenSigSendType" SG_ 858 SBCM_AST_Crc2Val 4;
BA_ "GenSigStartValue" SG_ 858 SBCM_AST_Crc2Val 255;
BA_ "UserSigValidity" SG_ 858 SBCM_AST_Crc2Val 0;
BA_ "Version" SG_ 858 SBCM_AST_Crc2Val "19.07.06";
BA_ "Description" SG_ 858 AST_CrashUnlockCmd "Assist Crash Unlock Command";
BA_ "GenSigSendType" SG_ 858 AST_CrashUnlockCmd 4;
BA_ "UserSigValidity" SG_ 858 AST_CrashUnlockCmd 0;
BA_REL_ "GenSigTimeoutTime" BU_SG_REL_ BLTN_CAM SG_ 858 AST_CrashUnlockCmd 1500;
BA_ "NetworkRequest" SG_ 858 AST_CrashUnlockCmd 0;
BA_ "Version" SG_ 858 AST_CrashUnlockCmd "20.09.00";
BA_ "Description" SG_ 858 SBCM_AST_AlvCnt2Val "For the first transmission request for a data element the counter shall be initialized with 0 and shall be incremented by 1

for every subsequent send request. When the counter reaches the maximum value(0xE), then it shall restart with 0 for the next send request";
BA_ "GenSigSendType" SG_ 858 SBCM_AST_AlvCnt2Val 4;
BA_ "UserSigValidity" SG_ 858 SBCM_AST_AlvCnt2Val 0;
BA_ "Version" SG_ 858 SBCM_AST_AlvCnt2Val "19.07.06";
BA_ "Description" SG_ 858 DoorLock_CtrlDrLkSwSta_SBCM "Central Door Lock Assist Switch Status";
BA_ "GenSigSendType" SG_ 858 DoorLock_CtrlDrLkSwSta_SBCM 4;
BA_ "UserSigValidity" SG_ 858 DoorLock_CtrlDrLkSwSta_SBCM 0;
BA_ "NetworkRequest" SG_ 858 DoorLock_CtrlDrLkSwSta_SBCM 0;
BA_ "Version" SG_ 858 DoorLock_CtrlDrLkSwSta_SBCM "19.07.06";
BA_ "Description" SG_ 858 DoorLock_CtrlDrUnLkSwSta_SBCM "Central Door Unlock Assist Switch Status";
BA_ "GenSigSendType" SG_ 858 DoorLock_CtrlDrUnLkSwSta_SBCM 4;
BA_ "UserSigValidity" SG_ 858 DoorLock_CtrlDrUnLkSwSta_SBCM 0;
BA_ "NetworkRequest" SG_ 858 DoorLock_CtrlDrUnLkSwSta_SBCM 0;
BA_ "Version" SG_ 858 DoorLock_CtrlDrUnLkSwSta_SBCM "19.07.06";
BA_ "Description" SG_ 858 Warn_AsstDrSwSta_SBCM "Warning Assist Door Switch Status";
BA_ "GenSigSendType" SG_ 858 Warn_AsstDrSwSta_SBCM 4;
BA_ "UserSigValidity" SG_ 858 Warn_AsstDrSwSta_SBCM 0;
BA_REL_ "GenSigTimeoutTime" BU_SG_REL_ WPC SG_ 858 Warn_AsstDrSwSta_SBCM 1500;
BA_REL_ "GenSigTimeoutTime" BU_SG_REL_ RWPC SG_ 858 Warn_AsstDrSwSta_SBCM 1500;
BA_REL_ "GenSigTimeoutTime" BU_SG_REL_ APSU SG_ 858 Warn_AsstDrSwSta_SBCM 1500;
BA_REL_ "GenSigTimeoutTime" BU_SG_REL_ ATS SG_ 858 Warn_AsstDrSwSta_SBCM 1500;
BA_REL_ "GenSigTimeoutTime" BU_SG_REL_ BLTN_CAM SG_ 858 Warn_AsstDrSwSta_SBCM 1500;
BA_REL_ "GenSigTimeoutTime" BU_SG_REL_ ALBCU SG_ 858 Warn_AsstDrSwSta_SBCM 1500;
BA_REL_ "GenSigTimeoutTime" BU_SG_REL_ WPC2 SG_ 858 Warn_AsstDrSwSta_SBCM 1500;
BA_ "NetworkRequest" SG_ 858 Warn_AsstDrSwSta_SBCM 0;
BA_ "Version" SG_ 858 Warn_AsstDrSwSta_SBCM "21.07.07";
BA_ "Description" SG_ 858 DoorLock_AsstDrUnLkSta_SBCM "Assist Door Unlock Status";
BA_ "GenSigSendType" SG_ 858 DoorLock_AsstDrUnLkSta_SBCM 4;
BA_ "UserSigValidity" SG_ 858 DoorLock_AsstDrUnLkSta_SBCM 0;
BA_REL_ "GenSigTimeoutTime" BU_SG_REL_ ATS SG_ 858 DoorLock_AsstDrUnLkSta_SBCM 1500;
BA_ "NetworkRequest" SG_ 858 DoorLock_AsstDrUnLkSta_SBCM 0;
BA_ "Version" SG_ 858 DoorLock_AsstDrUnLkSta_SBCM "19.07.06";
BA_ "Description" SG_ 858 AST_SEAWarn_RH "Assist (FRH) SEA Warning";
BA_ "GenSigSendType" SG_ 858 AST_SEAWarn_RH 4;
BA_ "UserSigValidity" SG_ 858 AST_SEAWarn_RH 0;
BA_ "NetworkRequest" SG_ 858 AST_SEAWarn_RH 0;
BA_ "Version" SG_ 858 AST_SEAWarn_RH "19.12.00";
BA_ "Description" SG_ 858 AST_SEAWarn_LH "Assist (FLH) Door SEA Warning";
BA_ "GenSigSendType" SG_ 858 AST_SEAWarn_LH 4;
BA_ "UserSigValidity" SG_ 858 AST_SEAWarn_LH 0;
BA_ "NetworkRequest" SG_ 858 AST_SEAWarn_LH 0;
BA_ "Version" SG_ 858 AST_SEAWarn_LH "19.12.00";
BA_ "GenSigSendType" SG_ 858 AST_SEWWarn_LH 4;
BA_ "UserSigValidity" SG_ 858 AST_SEWWarn_LH 0;
BA_ "NetworkRequest" SG_ 858 AST_SEWWarn_LH 0;
BA_ "Version" SG_ 858 AST_SEWWarn_LH "20.09.00";
BA_ "GenSigSendType" SG_ 858 AST_SEWWarn_RH 4;
BA_ "UserSigValidity" SG_ 858 AST_SEWWarn_RH 0;
BA_ "NetworkRequest" SG_ 858 AST_SEWWarn_RH 0;
BA_ "Version" SG_ 858 AST_SEWWarn_RH "20.09.00";
BA_ "GenSigSendType" SG_ 858 AST_MRActivationAlarm 4;
BA_ "UserSigValidity" SG_ 858 AST_MRActivationAlarm 0;
BA_ "NetworkRequest" SG_ 858 AST_MRActivationAlarm 0;
BA_ "NetworkRequestHoldingTime" SG_ 858 AST_MRActivationAlarm 5000;
BA_ "Version" SG_ 858 AST_MRActivationAlarm "19.11.05";
BA_ "GenSigSendType" SG_ 858 AST_ReleaseWarn 4;
BA_ "UserSigValidity" SG_ 858 AST_ReleaseWarn 0;
BA_ "NetworkRequest" SG_ 858 AST_ReleaseWarn 0;
BA_ "NetworkRequestHoldingTime" SG_ 858 AST_ReleaseWarn 5000;
BA_ "Version" SG_ 858 AST_ReleaseWarn "19.11.05";
BA_ "GenSigSendType" SG_ 858 USM_AstGhostDoorSta 4;
BA_ "UserSigValidity" SG_ 858 USM_AstGhostDoorSta 0;
BA_ "NetworkRequest" SG_ 858 USM_AstGhostDoorSta 0;
BA_ "NetworkRequestHoldingTime" SG_ 858 USM_AstGhostDoorSta 5000;
BA_ "Version" SG_ 858 USM_AstGhostDoorSta "21.03.11";
BA_ "GenSigSendType" SG_ 858 AST_SWFailAlarm 4;
BA_ "UserSigValidity" SG_ 858 AST_SWFailAlarm 0;
BA_ "NetworkRequest" SG_ 858 AST_SWFailAlarm 0;
BA_ "NetworkRequestHoldingTime" SG_ 858 AST_SWFailAlarm 5000;
BA_ "Version" SG_ 858 AST_SWFailAlarm "19.11.05";
BA_ "GenSigSendType" SG_ 858 DoorLock_PDSLkSwSta_AST 4;
BA_ "UserSigValidity" SG_ 858 DoorLock_PDSLkSwSta_AST 0;
BA_ "NetworkRequest" SG_ 858 DoorLock_PDSLkSwSta_AST 0;
BA_ "Version" SG_ 858 DoorLock_PDSLkSwSta_AST "19.12.00";
BA_ "GenSigSendType" SG_ 858 PDS_TypeOption_AST 4;
BA_ "UserSigValidity" SG_ 858 PDS_TypeOption_AST 0;
BA_ "NetworkRequest" SG_ 858 PDS_TypeOption_AST 0;
BA_ "Version" SG_ 858 PDS_TypeOption_AST "19.12.00";
BA_ "GenSigSendType" SG_ 858 AFCU_AutoWashModeSta_SBCM_AST 4;
BA_ "UserSigValidity" SG_ 858 AFCU_AutoWashModeSta_SBCM_AST 0;
BA_ "NetworkRequest" SG_ 858 AFCU_AutoWashModeSta_SBCM_AST 0;
BA_ "NetworkRequestHoldingTime" SG_ 858 AFCU_AutoWashModeSta_SBCM_AST 5000;
BA_ "Version" SG_ 858 AFCU_AutoWashModeSta_SBCM_AST "22.07.00";
BA_ "GenSigSendType" SG_ 858 CDM_AutoWashModeSta_SBCM_AST 4;
BA_ "UserSigValidity" SG_ 858 CDM_AutoWashModeSta_SBCM_AST 0;
BA_ "NetworkRequest" SG_ 858 CDM_AutoWashModeSta_SBCM_AST 0;
BA_ "NetworkRequestHoldingTime" SG_ 858 CDM_AutoWashModeSta_SBCM_AST 5000;
BA_ "Version" SG_ 858 CDM_AutoWashModeSta_SBCM_AST "22.07.00";
BA_ "GenSigSendType" SG_ 858 ASTDoorPushAlarm 4;
BA_ "UserSigValidity" SG_ 858 ASTDoorPushAlarm 0;
BA_ "NetworkRequest" SG_ 858 ASTDoorPushAlarm 0;
BA_ "NetworkRequestHoldingTime" SG_ 858 ASTDoorPushAlarm 5000;
BA_ "Version" SG_ 858 ASTDoorPushAlarm "20.09.00";
BA_ "GenMsgSendType" BO_ 799 0;
BA_ "Description" SG_ 799 SBCM_DRV_Crc1Val "The data area for CRC calculation is based on the data length (DLC) of the message DB.

The CRC shall be calculated over the entire data block (excluding the CRC bytes) including the user data, alive counter and Data ID 

 

- CRC Polynomial (0x1D) , Initial Value : 0x00, XOR value : 0xFF, Data ID Mode : Both, Data ID : Message ID + 0xF800 

- The initial value is for CRC calculation and the message should be sent with the calculated result value. 

The mathematical expression to 8 bit CRC polynomial is given here. G(x) = x8 + x4 + x3 + x2 + 1";
BA_ "GenSigSendType" SG_ 799 SBCM_DRV_Crc1Val 4;
BA_ "GenSigStartValue" SG_ 799 SBCM_DRV_Crc1Val 255;
BA_ "UserSigValidity" SG_ 799 SBCM_DRV_Crc1Val 0;
BA_ "Version" SG_ 799 SBCM_DRV_Crc1Val "19.07.06";
BA_ "Description" SG_ 799 DRV_CrashUnlockCmd "Drive Crash Unlock Command";
BA_ "GenSigSendType" SG_ 799 DRV_CrashUnlockCmd 4;
BA_ "UserSigValidity" SG_ 799 DRV_CrashUnlockCmd 0;
BA_REL_ "GenSigTimeoutTime" BU_SG_REL_ BLTN_CAM SG_ 799 DRV_CrashUnlockCmd 1500;
BA_ "NetworkRequest" SG_ 799 DRV_CrashUnlockCmd 0;
BA_ "Version" SG_ 799 DRV_CrashUnlockCmd "20.09.00";
BA_ "Description" SG_ 799 C_ApprOpenStatus "This is for Power Door System enable/disable signal.";
BA_ "GenSigSendType" SG_ 799 C_ApprOpenStatus 4;
BA_ "UserSigValidity" SG_ 799 C_ApprOpenStatus 0;
BA_ "Version" SG_ 799 C_ApprOpenStatus "20.09.00";
BA_ "Description" SG_ 799 SBCM_DRV_AlvCnt1Val "For the first transmission request for a data element the counter shall be initialized with 0 and shall be incremented by 1

for every subsequent send request. When the counter reaches the maximum value(0xE), then it shall restart with 0 for the next send request";
BA_ "GenSigSendType" SG_ 799 SBCM_DRV_AlvCnt1Val 4;
BA_ "UserSigValidity" SG_ 799 SBCM_DRV_AlvCnt1Val 0;
BA_ "Version" SG_ 799 SBCM_DRV_AlvCnt1Val "19.07.06";
BA_ "Description" SG_ 799 DoorLock_DrvKeyLkSwSta_SBCM "Door Lock Driver Mechanical Key Input Signal";
BA_ "GenSigSendType" SG_ 799 DoorLock_DrvKeyLkSwSta_SBCM 4;
BA_ "UserSigValidity" SG_ 799 DoorLock_DrvKeyLkSwSta_SBCM 0;
BA_ "NetworkRequest" SG_ 799 DoorLock_DrvKeyLkSwSta_SBCM 0;
BA_ "Version" SG_ 799 DoorLock_DrvKeyLkSwSta_SBCM "19.07.06";
BA_ "Description" SG_ 799 DoorLock_DrvKeyUnLkSwSta_SBCM "Door Drive Mechanical Key Unlock Switch State";
BA_ "GenSigSendType" SG_ 799 DoorLock_DrvKeyUnLkSwSta_SBCM 4;
BA_ "UserSigValidity" SG_ 799 DoorLock_DrvKeyUnLkSwSta_SBCM 0;
BA_ "NetworkRequest" SG_ 799 DoorLock_DrvKeyUnLkSwSta_SBCM 0;
BA_ "Version" SG_ 799 DoorLock_DrvKeyUnLkSwSta_SBCM "19.07.06";
BA_ "Description" SG_ 799 Warn_DrvDrSwSta_SBCM "Warning Drive Door Switch State";
BA_ "GenSigSendType" SG_ 799 Warn_DrvDrSwSta_SBCM 4;
BA_ "UserSigValidity" SG_ 799 Warn_DrvDrSwSta_SBCM 0;
BA_REL_ "GenSigTimeoutTime" BU_SG_REL_ WPC SG_ 799 Warn_DrvDrSwSta_SBCM 1500;
BA_REL_ "GenSigTimeoutTime" BU_SG_REL_ RWPC SG_ 799 Warn_DrvDrSwSta_SBCM 1500;
BA_REL_ "GenSigTimeoutTime" BU_SG_REL_ DPSU SG_ 799 Warn_DrvDrSwSta_SBCM 1500;
BA_REL_ "GenSigTimeoutTime" BU_SG_REL_ ATS SG_ 799 Warn_DrvDrSwSta_SBCM 1500;
BA_REL_ "GenSigTimeoutTime" BU_SG_REL_ BLTN_CAM SG_ 799 Warn_DrvDrSwSta_SBCM 1500;
BA_REL_ "GenSigTimeoutTime" BU_SG_REL_ WPC2 SG_ 799 Warn_DrvDrSwSta_SBCM 1500;
BA_ "NetworkRequest" SG_ 799 Warn_DrvDrSwSta_SBCM 0;
BA_ "Version" SG_ 799 Warn_DrvDrSwSta_SBCM "21.07.07";
BA_ "Description" SG_ 799 DoorLock_DrvDrUnLkSta_SBCM "Drive Door Lock Unlock Status";
BA_ "GenSigSendType" SG_ 799 DoorLock_DrvDrUnLkSta_SBCM 4;
BA_ "UserSigValidity" SG_ 799 DoorLock_DrvDrUnLkSta_SBCM 0;
BA_REL_ "GenSigTimeoutTime" BU_SG_REL_ DPSU SG_ 799 DoorLock_DrvDrUnLkSta_SBCM 1500;
BA_REL_ "GenSigTimeoutTime" BU_SG_REL_ ATS SG_ 799 DoorLock_DrvDrUnLkSta_SBCM 1500;
BA_ "NetworkRequest" SG_ 799 DoorLock_DrvDrUnLkSta_SBCM 0;
BA_ "Version" SG_ 799 DoorLock_DrvDrUnLkSta_SBCM "19.07.06";
BA_ "Description" SG_ 799 DRV_SEAWarn_LH "Drive (FLH) Door SEA Warning";
BA_ "GenSigSendType" SG_ 799 DRV_SEAWarn_LH 4;
BA_ "UserSigValidity" SG_ 799 DRV_SEAWarn_LH 0;
BA_ "NetworkRequest" SG_ 799 DRV_SEAWarn_LH 0;
BA_ "Version" SG_ 799 DRV_SEAWarn_LH "19.12.00";
BA_ "Description" SG_ 799 DRV_SEAWarn_RH "Drive (FRH) Door SEA Warning";
BA_ "GenSigSendType" SG_ 799 DRV_SEAWarn_RH 4;
BA_ "UserSigValidity" SG_ 799 DRV_SEAWarn_RH 0;
BA_ "NetworkRequest" SG_ 799 DRV_SEAWarn_RH 0;
BA_ "Version" SG_ 799 DRV_SEAWarn_RH "19.12.07";
BA_ "Description" SG_ 799 DRV_SEWWarn_LH "Drive (FLH) Door Safety Exit Warning";
BA_ "GenSigSendType" SG_ 799 DRV_SEWWarn_LH 4;
BA_ "UserSigValidity" SG_ 799 DRV_SEWWarn_LH 0;
BA_ "NetworkRequest" SG_ 799 DRV_SEWWarn_LH 0;
BA_ "Version" SG_ 799 DRV_SEWWarn_LH "20.09.00";
BA_ "Description" SG_ 799 DRV_SEWWarn_RH "Drive (FRH) Door Safety Exit Warning";
BA_ "GenSigSendType" SG_ 799 DRV_SEWWarn_RH 4;
BA_ "UserSigValidity" SG_ 799 DRV_SEWWarn_RH 0;
BA_ "NetworkRequest" SG_ 799 DRV_SEWWarn_RH 0;
BA_ "Version" SG_ 799 DRV_SEWWarn_RH "20.09.00";
BA_ "GenSigSendType" SG_ 799 DRV_MRActivationAlarm 4;
BA_ "UserSigValidity" SG_ 799 DRV_MRActivationAlarm 0;
BA_ "NetworkRequest" SG_ 799 DRV_MRActivationAlarm 0;
BA_ "NetworkRequestHoldingTime" SG_ 799 DRV_MRActivationAlarm 5000;
BA_ "Version" SG_ 799 DRV_MRActivationAlarm "19.11.05";
BA_ "GenSigSendType" SG_ 799 DRV_ReleaseWarn 4;
BA_ "UserSigValidity" SG_ 799 DRV_ReleaseWarn 0;
BA_ "NetworkRequest" SG_ 799 DRV_ReleaseWarn 0;
BA_ "NetworkRequestHoldingTime" SG_ 799 DRV_ReleaseWarn 5000;
BA_ "Version" SG_ 799 DRV_ReleaseWarn "19.11.05";
BA_ "Description" SG_ 799 Latch_TypeOption_DRV "If the E-Lacth is applied, the signal will be send for identify the door lock/unlock function and option.";
BA_ "GenSigSendType" SG_ 799 Latch_TypeOption_DRV 4;
BA_ "UserSigValidity" SG_ 799 Latch_TypeOption_DRV 0;
BA_ "NetworkRequest" SG_ 799 Latch_TypeOption_DRV 0;
BA_ "Version" SG_ 799 Latch_TypeOption_DRV "20.09.00";
BA_ "GenSigSendType" SG_ 799 DRV_SWFailAlarm 4;
BA_ "UserSigValidity" SG_ 799 DRV_SWFailAlarm 0;
BA_ "NetworkRequest" SG_ 799 DRV_SWFailAlarm 0;
BA_ "NetworkRequestHoldingTime" SG_ 799 DRV_SWFailAlarm 5000;
BA_ "Version" SG_ 799 DRV_SWFailAlarm "19.11.05";
BA_ "GenSigSendType" SG_ 799 USM_PwrDRApprOpnSetSta 4;
BA_ "UserSigValidity" SG_ 799 USM_PwrDRApprOpnSetSta 0;
BA_ "NetworkRequest" SG_ 799 USM_PwrDRApprOpnSetSta 0;
BA_ "NetworkRequestHoldingTime" SG_ 799 USM_PwrDRApprOpnSetSta 5000;
BA_ "Version" SG_ 799 USM_PwrDRApprOpnSetSta "20.12.03";
BA_ "GenSigSendType" SG_ 799 USM_PwrDRApprOpnSetOpt 4;
BA_ "UserSigValidity" SG_ 799 USM_PwrDRApprOpnSetOpt 0;
BA_ "NetworkRequest" SG_ 799 USM_PwrDRApprOpnSetOpt 0;
BA_ "NetworkRequestHoldingTime" SG_ 799 USM_PwrDRApprOpnSetOpt 5000;
BA_ "Version" SG_ 799 USM_PwrDRApprOpnSetOpt "20.12.03";
BA_ "GenSigSendType" SG_ 799 USM_PwrDRCloseByRKELockSta 4;
BA_ "UserSigValidity" SG_ 799 USM_PwrDRCloseByRKELockSta 0;
BA_ "NetworkRequest" SG_ 799 USM_PwrDRCloseByRKELockSta 0;
BA_ "NetworkRequestHoldingTime" SG_ 799 USM_PwrDRCloseByRKELockSta 5000;
BA_ "Version" SG_ 799 USM_PwrDRCloseByRKELockSta "20.12.03";
BA_ "GenSigSendType" SG_ 799 USM_PwrDRCloseByRKELockOpt 4;
BA_ "UserSigValidity" SG_ 799 USM_PwrDRCloseByRKELockOpt 0;
BA_ "NetworkRequest" SG_ 799 USM_PwrDRCloseByRKELockOpt 0;
BA_ "NetworkRequestHoldingTime" SG_ 799 USM_PwrDRCloseByRKELockOpt 5000;
BA_ "Version" SG_ 799 USM_PwrDRCloseByRKELockOpt "20.12.03";
BA_ "GenSigSendType" SG_ 799 USM_PwrDRCloseByBrakeSta 4;
BA_ "UserSigValidity" SG_ 799 USM_PwrDRCloseByBrakeSta 0;
BA_ "NetworkRequest" SG_ 799 USM_PwrDRCloseByBrakeSta 0;
BA_ "NetworkRequestHoldingTime" SG_ 799 USM_PwrDRCloseByBrakeSta 5000;
BA_ "Version" SG_ 799 USM_PwrDRCloseByBrakeSta "20.12.03";
BA_ "GenSigSendType" SG_ 799 USM_PwrDRCloseByBrakeOpt 4;
BA_ "UserSigValidity" SG_ 799 USM_PwrDRCloseByBrakeOpt 0;
BA_ "NetworkRequest" SG_ 799 USM_PwrDRCloseByBrakeOpt 0;
BA_ "NetworkRequestHoldingTime" SG_ 799 USM_PwrDRCloseByBrakeOpt 5000;
BA_ "Version" SG_ 799 USM_PwrDRCloseByBrakeOpt "20.12.03";
BA_ "GenSigSendType" SG_ 799 USM_PwrDRBuzzerSta 4;
BA_ "UserSigValidity" SG_ 799 USM_PwrDRBuzzerSta 0;
BA_ "NetworkRequest" SG_ 799 USM_PwrDRBuzzerSta 0;
BA_ "NetworkRequestHoldingTime" SG_ 799 USM_PwrDRBuzzerSta 5000;
BA_ "Version" SG_ 799 USM_PwrDRBuzzerSta "20.12.03";
BA_ "GenSigSendType" SG_ 799 USM_PwrDRBuzzerOpt 4;
BA_ "UserSigValidity" SG_ 799 USM_PwrDRBuzzerOpt 0;
BA_ "NetworkRequest" SG_ 799 USM_PwrDRBuzzerOpt 0;
BA_ "NetworkRequestHoldingTime" SG_ 799 USM_PwrDRBuzzerOpt 5000;
BA_ "Version" SG_ 799 USM_PwrDRBuzzerOpt "20.12.03";
BA_ "GenSigSendType" SG_ 799 PDS_TypeOption_DRV 4;
BA_ "UserSigValidity" SG_ 799 PDS_TypeOption_DRV 0;
BA_ "NetworkRequest" SG_ 799 PDS_TypeOption_DRV 0;
BA_ "Version" SG_ 799 PDS_TypeOption_DRV "20.09.00";
BA_ "Description" SG_ 799 C_DrvDoorApproachOpen "Fob searching start and stop signal for PDS.";
BA_ "GenSigSendType" SG_ 799 C_DrvDoorApproachOpen 4;
BA_ "UserSigValidity" SG_ 799 C_DrvDoorApproachOpen 0;
BA_ "Version" SG_ 799 C_DrvDoorApproachOpen "20.09.00";
BA_ "Description" SG_ 799 C_DrvDoorApproachClose "To close the door automatically, request the fob searching signal";
BA_ "GenSigSendType" SG_ 799 C_DrvDoorApproachClose 4;
BA_ "UserSigValidity" SG_ 799 C_DrvDoorApproachClose 0;
BA_ "Version" SG_ 799 C_DrvDoorApproachClose "20.09.00";
BA_ "GenSigSendType" SG_ 799 DoorLock_PDSLkSwSta_DRV 4;
BA_ "UserSigValidity" SG_ 799 DoorLock_PDSLkSwSta_DRV 0;
BA_ "NetworkRequest" SG_ 799 DoorLock_PDSLkSwSta_DRV 0;
BA_ "Version" SG_ 799 DoorLock_PDSLkSwSta_DRV "20.09.00";
BA_ "GenSigSendType" SG_ 799 DRVDoorPushAlarm 4;
BA_ "UserSigValidity" SG_ 799 DRVDoorPushAlarm 0;
BA_ "NetworkRequest" SG_ 799 DRVDoorPushAlarm 0;
BA_ "NetworkRequestHoldingTime" SG_ 799 DRVDoorPushAlarm 5000;
BA_ "Version" SG_ 799 DRVDoorPushAlarm "20.09.00";
BA_ "GenMsgSendType" BO_ 862 0;
BA_ "Description" SG_ 862 SBCM_RL_Crc1Val "The data area for CRC calculation is based on the data length (DLC) of the message DB.

The CRC shall be calculated over the entire data block (excluding the CRC bytes) including the user data, alive counter and Data ID 

 

- CRC Polynomial (0x1D) , Initial Value : 0x00, XOR value : 0xFF, Data ID Mode : Both, Data ID : Message ID + 0xF800 

- The initial value is for CRC calculation and the message should be sent with the calculated result value. 

The mathematical expression to 8 bit CRC polynomial is given here. G(x) = x8 + x4 + x3 + x2 + 1";
BA_ "GenSigSendType" SG_ 862 SBCM_RL_Crc1Val 4;
BA_ "GenSigStartValue" SG_ 862 SBCM_RL_Crc1Val 255;
BA_ "UserSigValidity" SG_ 862 SBCM_RL_Crc1Val 0;
BA_ "Version" SG_ 862 SBCM_RL_Crc1Val "19.07.06";
BA_ "Description" SG_ 862 RL_CrashUnlockCmd "RearLefrCrashUnlockCommand";
BA_ "GenSigSendType" SG_ 862 RL_CrashUnlockCmd 4;
BA_ "UserSigValidity" SG_ 862 RL_CrashUnlockCmd 0;
BA_REL_ "GenSigTimeoutTime" BU_SG_REL_ BLTN_CAM SG_ 862 RL_CrashUnlockCmd 1500;
BA_ "NetworkRequest" SG_ 862 RL_CrashUnlockCmd 0;
BA_ "Version" SG_ 862 RL_CrashUnlockCmd "20.09.00";
BA_ "Description" SG_ 862 SBCM_RL_AlvCnt1Val "For the first transmission request for a data element the counter shall be initialized with 0 and shall be incremented by 1

for every subsequent send request. When the counter reaches the maximum value(0xE), then it shall restart with 0 for the next send request";
BA_ "GenSigSendType" SG_ 862 SBCM_RL_AlvCnt1Val 4;
BA_ "UserSigValidity" SG_ 862 SBCM_RL_AlvCnt1Val 0;
BA_ "Version" SG_ 862 SBCM_RL_AlvCnt1Val "19.07.06";
BA_ "Description" SG_ 862 Warn_RrLftDrSwSta_SBCM "Warning Rear Left Door Switch Status";
BA_ "GenSigSendType" SG_ 862 Warn_RrLftDrSwSta_SBCM 4;
BA_ "UserSigValidity" SG_ 862 Warn_RrLftDrSwSta_SBCM 0;
BA_REL_ "GenSigTimeoutTime" BU_SG_REL_ WPC SG_ 862 Warn_RrLftDrSwSta_SBCM 1500;
BA_REL_ "GenSigTimeoutTime" BU_SG_REL_ RWPC SG_ 862 Warn_RrLftDrSwSta_SBCM 1500;
BA_REL_ "GenSigTimeoutTime" BU_SG_REL_ APSU SG_ 862 Warn_RrLftDrSwSta_SBCM 1500;
BA_REL_ "GenSigTimeoutTime" BU_SG_REL_ ATS SG_ 862 Warn_RrLftDrSwSta_SBCM 1500;
BA_REL_ "GenSigTimeoutTime" BU_SG_REL_ BLTN_CAM SG_ 862 Warn_RrLftDrSwSta_SBCM 1500;
BA_REL_ "GenSigTimeoutTime" BU_SG_REL_ WPC2 SG_ 862 Warn_RrLftDrSwSta_SBCM 1500;
BA_ "NetworkRequest" SG_ 862 Warn_RrLftDrSwSta_SBCM 0;
BA_ "Version" SG_ 862 Warn_RrLftDrSwSta_SBCM "21.07.07";
BA_ "Description" SG_ 862 DoorLock_RrLftDrUnLkSta_SBCM "Rear Left Door Unlock Status";
BA_ "GenSigSendType" SG_ 862 DoorLock_RrLftDrUnLkSta_SBCM 4;
BA_ "UserSigValidity" SG_ 862 DoorLock_RrLftDrUnLkSta_SBCM 0;
BA_REL_ "GenSigTimeoutTime" BU_SG_REL_ ATS SG_ 862 DoorLock_RrLftDrUnLkSta_SBCM 1500;
BA_ "NetworkRequest" SG_ 862 DoorLock_RrLftDrUnLkSta_SBCM 0;
BA_ "Version" SG_ 862 DoorLock_RrLftDrUnLkSta_SBCM "19.07.06";
BA_ "Description" SG_ 862 RL_SEAActivated "Rear Left SEA Activated";
BA_ "GenSigSendType" SG_ 862 RL_SEAActivated 4;
BA_ "UserSigValidity" SG_ 862 RL_SEAActivated 0;
BA_ "NetworkRequest" SG_ 862 RL_SEAActivated 0;
BA_ "Version" SG_ 862 RL_SEAActivated "19.07.06";
BA_ "Description" SG_ 862 RL_SEAWarn "RearLeftSEAWarning";
BA_ "GenSigSendType" SG_ 862 RL_SEAWarn 4;
BA_ "UserSigValidity" SG_ 862 RL_SEAWarn 0;
BA_ "NetworkRequest" SG_ 862 RL_SEAWarn 0;
BA_ "Version" SG_ 862 RL_SEAWarn "19.07.06";
BA_ "GenSigSendType" SG_ 862 RL_SEWWarn 4;
BA_ "UserSigValidity" SG_ 862 RL_SEWWarn 0;
BA_ "NetworkRequest" SG_ 862 RL_SEWWarn 0;
BA_ "Version" SG_ 862 RL_SEWWarn "20.09.00";
BA_ "GenSigSendType" SG_ 862 RL_ReleaseWarn 4;
BA_ "UserSigValidity" SG_ 862 RL_ReleaseWarn 0;
BA_ "NetworkRequest" SG_ 862 RL_ReleaseWarn 0;
BA_ "NetworkRequestHoldingTime" SG_ 862 RL_ReleaseWarn 5000;
BA_ "Version" SG_ 862 RL_ReleaseWarn "20.09.00";
BA_ "GenSigSendType" SG_ 862 RL_SWFailAlarm 4;
BA_ "UserSigValidity" SG_ 862 RL_SWFailAlarm 0;
BA_ "NetworkRequest" SG_ 862 RL_SWFailAlarm 0;
BA_ "NetworkRequestHoldingTime" SG_ 862 RL_SWFailAlarm 5000;
BA_ "Version" SG_ 862 RL_SWFailAlarm "20.09.00";
BA_ "GenSigSendType" SG_ 862 RL_ChildLock_ActnFlSta 4;
BA_ "UserSigValidity" SG_ 862 RL_ChildLock_ActnFlSta 0;
BA_ "NetworkRequest" SG_ 862 RL_ChildLock_ActnFlSta 0;
BA_ "NetworkRequestHoldingTime" SG_ 862 RL_ChildLock_ActnFlSta 5000;
BA_ "Version" SG_ 862 RL_ChildLock_ActnFlSta "19.11.05";
BA_ "GenSigSendType" SG_ 862 RL_MRActivationAlarm 4;
BA_ "UserSigValidity" SG_ 862 RL_MRActivationAlarm 0;
BA_ "NetworkRequest" SG_ 862 RL_MRActivationAlarm 0;
BA_ "NetworkRequestHoldingTime" SG_ 862 RL_MRActivationAlarm 5000;
BA_ "Version" SG_ 862 RL_MRActivationAlarm "19.11.05";
BA_ "GenSigSendType" SG_ 862 RL_ChildLock_Status 4;
BA_ "UserSigValidity" SG_ 862 RL_ChildLock_Status 0;
BA_ "NetworkRequest" SG_ 862 RL_ChildLock_Status 0;
BA_ "NetworkRequestHoldingTime" SG_ 862 RL_ChildLock_Status 5000;
BA_ "Version" SG_ 862 RL_ChildLock_Status "21.07.07";
BA_ "GenSigSendType" SG_ 862 USM_RLGhostDoorSta 4;
BA_ "UserSigValidity" SG_ 862 USM_RLGhostDoorSta 0;
BA_ "NetworkRequest" SG_ 862 USM_RLGhostDoorSta 0;
BA_ "NetworkRequestHoldingTime" SG_ 862 USM_RLGhostDoorSta 5000;
BA_ "Version" SG_ 862 USM_RLGhostDoorSta "21.03.11";
BA_ "GenSigSendType" SG_ 862 DoorLock_PDSLkSwSta_RL 4;
BA_ "UserSigValidity" SG_ 862 DoorLock_PDSLkSwSta_RL 0;
BA_ "NetworkRequest" SG_ 862 DoorLock_PDSLkSwSta_RL 0;
BA_ "Version" SG_ 862 DoorLock_PDSLkSwSta_RL "19.12.00";
BA_ "GenSigSendType" SG_ 862 PDS_TypeOption_RL 4;
BA_ "UserSigValidity" SG_ 862 PDS_TypeOption_RL 0;
BA_ "NetworkRequest" SG_ 862 PDS_TypeOption_RL 0;
BA_ "Version" SG_ 862 PDS_TypeOption_RL "19.12.00";
BA_ "GenSigSendType" SG_ 862 RLDoorPushAlarm 4;
BA_ "UserSigValidity" SG_ 862 RLDoorPushAlarm 0;
BA_ "NetworkRequest" SG_ 862 RLDoorPushAlarm 0;
BA_ "NetworkRequestHoldingTime" SG_ 862 RLDoorPushAlarm 5000;
BA_ "Version" SG_ 862 RLDoorPushAlarm "20.09.00";
BA_ "GenMsgSendType" BO_ 905 0;
BA_ "Description" SG_ 905 SBCM_RR_Crc1Val "The data area for CRC calculation is based on the data length (DLC) of the message DB.

The CRC shall be calculated over the entire data block (excluding the CRC bytes) including the user data, alive counter and Data ID 

 

- CRC Polynomial (0x1D) , Initial Value : 0x00, XOR value : 0xFF, Data ID Mode : Both, Data ID : Message ID + 0xF800 

- The initial value is for CRC calculation and the message should be sent with the calculated result value. 

The mathematical expression to 8 bit CRC polynomial is given here. G(x) = x8 + x4 + x3 + x2 + 1";
BA_ "GenSigSendType" SG_ 905 SBCM_RR_Crc1Val 4;
BA_ "GenSigStartValue" SG_ 905 SBCM_RR_Crc1Val 255;
BA_ "UserSigValidity" SG_ 905 SBCM_RR_Crc1Val 0;
BA_ "Version" SG_ 905 SBCM_RR_Crc1Val "19.07.06";
BA_ "Description" SG_ 905 RR_CrashUnlockCmd "RearRightCrashUnlockCommand";
BA_ "GenSigSendType" SG_ 905 RR_CrashUnlockCmd 4;
BA_ "UserSigValidity" SG_ 905 RR_CrashUnlockCmd 0;
BA_REL_ "GenSigTimeoutTime" BU_SG_REL_ BLTN_CAM SG_ 905 RR_CrashUnlockCmd 1500;
BA_ "NetworkRequest" SG_ 905 RR_CrashUnlockCmd 0;
BA_ "Version" SG_ 905 RR_CrashUnlockCmd "20.09.00";
BA_ "Description" SG_ 905 SBCM_RR_AlvCnt1Val "For the first transmission request for a data element the counter shall be initialized with 0 and shall be incremented by 1

for every subsequent send request. When the counter reaches the maximum value(0xE), then it shall restart with 0 for the next send request";
BA_ "GenSigSendType" SG_ 905 SBCM_RR_AlvCnt1Val 4;
BA_ "UserSigValidity" SG_ 905 SBCM_RR_AlvCnt1Val 0;
BA_ "Version" SG_ 905 SBCM_RR_AlvCnt1Val "19.07.06";
BA_ "Description" SG_ 905 Warn_RrRtDrSwSta_SBCM "Warning Rear Right Door Switch Status";
BA_ "GenSigSendType" SG_ 905 Warn_RrRtDrSwSta_SBCM 4;
BA_ "UserSigValidity" SG_ 905 Warn_RrRtDrSwSta_SBCM 0;
BA_REL_ "GenSigTimeoutTime" BU_SG_REL_ WPC SG_ 905 Warn_RrRtDrSwSta_SBCM 1500;
BA_REL_ "GenSigTimeoutTime" BU_SG_REL_ RWPC SG_ 905 Warn_RrRtDrSwSta_SBCM 1500;
BA_REL_ "GenSigTimeoutTime" BU_SG_REL_ APSU SG_ 905 Warn_RrRtDrSwSta_SBCM 1500;
BA_REL_ "GenSigTimeoutTime" BU_SG_REL_ RRPSU SG_ 905 Warn_RrRtDrSwSta_SBCM 1500;
BA_REL_ "GenSigTimeoutTime" BU_SG_REL_ ATS SG_ 905 Warn_RrRtDrSwSta_SBCM 1500;
BA_REL_ "GenSigTimeoutTime" BU_SG_REL_ BLTN_CAM SG_ 905 Warn_RrRtDrSwSta_SBCM 1500;
BA_REL_ "GenSigTimeoutTime" BU_SG_REL_ WPC2 SG_ 905 Warn_RrRtDrSwSta_SBCM 1500;
BA_ "NetworkRequest" SG_ 905 Warn_RrRtDrSwSta_SBCM 0;
BA_ "Version" SG_ 905 Warn_RrRtDrSwSta_SBCM "21.07.07";
BA_ "Description" SG_ 905 DoorLock_RrRtDrUnLkSta_SBCM "Rear Right Door Unlock Status";
BA_ "GenSigSendType" SG_ 905 DoorLock_RrRtDrUnLkSta_SBCM 4;
BA_ "UserSigValidity" SG_ 905 DoorLock_RrRtDrUnLkSta_SBCM 0;
BA_REL_ "GenSigTimeoutTime" BU_SG_REL_ ATS SG_ 905 DoorLock_RrRtDrUnLkSta_SBCM 1500;
BA_ "NetworkRequest" SG_ 905 DoorLock_RrRtDrUnLkSta_SBCM 0;
BA_ "Version" SG_ 905 DoorLock_RrRtDrUnLkSta_SBCM "19.07.06";
BA_ "Description" SG_ 905 RR_SEAActivated "RearRightSEAActivated";
BA_ "GenSigSendType" SG_ 905 RR_SEAActivated 4;
BA_ "UserSigValidity" SG_ 905 RR_SEAActivated 0;
BA_ "NetworkRequest" SG_ 905 RR_SEAActivated 0;
BA_ "Version" SG_ 905 RR_SEAActivated "19.07.06";
BA_ "Description" SG_ 905 RR_SEAWarn "RearRighrSEAWarning";
BA_ "GenSigSendType" SG_ 905 RR_SEAWarn 4;
BA_ "UserSigValidity" SG_ 905 RR_SEAWarn 0;
BA_ "NetworkRequest" SG_ 905 RR_SEAWarn 0;
BA_ "Version" SG_ 905 RR_SEAWarn "19.07.06";
BA_ "GenSigSendType" SG_ 905 RR_SEWWarn 4;
BA_ "UserSigValidity" SG_ 905 RR_SEWWarn 0;
BA_ "NetworkRequest" SG_ 905 RR_SEWWarn 0;
BA_ "Version" SG_ 905 RR_SEWWarn "20.09.00";
BA_ "GenSigSendType" SG_ 905 RR_ReleaseWarn 4;
BA_ "UserSigValidity" SG_ 905 RR_ReleaseWarn 0;
BA_ "NetworkRequest" SG_ 905 RR_ReleaseWarn 0;
BA_ "NetworkRequestHoldingTime" SG_ 905 RR_ReleaseWarn 5000;
BA_ "Version" SG_ 905 RR_ReleaseWarn "20.09.00";
BA_ "GenSigSendType" SG_ 905 RR_SWFailAlarm 4;
BA_ "UserSigValidity" SG_ 905 RR_SWFailAlarm 0;
BA_ "NetworkRequest" SG_ 905 RR_SWFailAlarm 0;
BA_ "NetworkRequestHoldingTime" SG_ 905 RR_SWFailAlarm 5000;
BA_ "Version" SG_ 905 RR_SWFailAlarm "20.09.00";
BA_ "GenSigSendType" SG_ 905 RR_ChildLock_ActnFlSta 4;
BA_ "UserSigValidity" SG_ 905 RR_ChildLock_ActnFlSta 0;
BA_ "NetworkRequest" SG_ 905 RR_ChildLock_ActnFlSta 0;
BA_ "NetworkRequestHoldingTime" SG_ 905 RR_ChildLock_ActnFlSta 5000;
BA_ "Version" SG_ 905 RR_ChildLock_ActnFlSta "19.11.05";
BA_ "GenSigSendType" SG_ 905 RR_MRActivationAlarm 4;
BA_ "UserSigValidity" SG_ 905 RR_MRActivationAlarm 0;
BA_ "NetworkRequest" SG_ 905 RR_MRActivationAlarm 0;
BA_ "NetworkRequestHoldingTime" SG_ 905 RR_MRActivationAlarm 5000;
BA_ "Version" SG_ 905 RR_MRActivationAlarm "19.11.05";
BA_ "GenSigSendType" SG_ 905 RR_ChildLock_Status 4;
BA_ "UserSigValidity" SG_ 905 RR_ChildLock_Status 0;
BA_ "NetworkRequest" SG_ 905 RR_ChildLock_Status 0;
BA_ "NetworkRequestHoldingTime" SG_ 905 RR_ChildLock_Status 5000;
BA_ "Version" SG_ 905 RR_ChildLock_Status "21.07.07";
BA_ "GenSigSendType" SG_ 905 USM_RRGhostDoorSta 4;
BA_ "UserSigValidity" SG_ 905 USM_RRGhostDoorSta 0;
BA_ "NetworkRequest" SG_ 905 USM_RRGhostDoorSta 0;
BA_ "NetworkRequestHoldingTime" SG_ 905 USM_RRGhostDoorSta 5000;
BA_ "Version" SG_ 905 USM_RRGhostDoorSta "21.03.11";
BA_ "GenSigSendType" SG_ 905 DoorLock_PDSLkSwSta_RR 4;
BA_ "UserSigValidity" SG_ 905 DoorLock_PDSLkSwSta_RR 0;
BA_ "NetworkRequest" SG_ 905 DoorLock_PDSLkSwSta_RR 0;
BA_ "Version" SG_ 905 DoorLock_PDSLkSwSta_RR "19.12.00";
BA_ "GenSigSendType" SG_ 905 PDS_TypeOption_RR 4;
BA_ "UserSigValidity" SG_ 905 PDS_TypeOption_RR 0;
BA_ "NetworkRequest" SG_ 905 PDS_TypeOption_RR 0;
BA_ "Version" SG_ 905 PDS_TypeOption_RR "19.12.00";
BA_ "GenSigSendType" SG_ 905 RRDoorPushAlarm 4;
BA_ "UserSigValidity" SG_ 905 RRDoorPushAlarm 0;
BA_ "NetworkRequest" SG_ 905 RRDoorPushAlarm 0;
BA_ "NetworkRequestHoldingTime" SG_ 905 RRDoorPushAlarm 5000;
BA_ "Version" SG_ 905 RRDoorPushAlarm "20.09.00";
BA_ "GenMsgSendType" BO_ 2160080129 0;
BA_ "GenMsgCycleTime" BO_ 2160080129 50;
BA_ "GenMsgCycleTimeFast" BO_ 2160080129 0;
BA_ "GenMsgNrOfRepetition" BO_ 2160080129 0;
BA_ "VFrameFormat" BO_ 2160080129 1;
BA_ "Description" SG_ 2160080129 VCU_Crc1Val "The data area for CRC calculation is based on the data length (DLC) of the message DB.

The CRC shall be calculated over the entire data block (excluding the CRC bytes) including the user data, alive counter and Data ID



- CRC Polynomial (0x1021) , Initial Value : 0xFFFF, XOR value : 0x0000, Data ID : Message ID + 0xF800 

- The initial value is for CRC calculation and the message should be sent with the calculated result value. 

- The mathematical expression to 16 bit CRC polynomial is given here. G(x) = x16 + x12 + x5 + 1



<For CRC calculation of CAN-FD Msg for HS CAN domain ECUs>



- HS-CAN Messages that routed from CAN-FD domain are using 29 bit Extended CAN ID and splitted into 8 Byte Messages.

(from 1 to 4 Msgs, depending on source CAN-FD Msg’s DLC)

- For splitted CAN-FD Msgs’ CRC calculation, HS CAN ECUs should use source CAN-FD Msg’s original STD ID. 

- The original STD ID can be read from Ext ID’s 4~6th Byte.

Eg. STD 0x6AA : EXT SPLT 0x1A8[6AA]01 / 0x1A8[6AA]02 / 0x1A8[6AA]03 / 0x1A8[6AA]04 

(2~4th splitited Msgs can be omitted depending on source CAN-FD Msg’s DLC)

- Aslo, HS-CAN ECUs should use merged data block (from whole splitted Msg) for CRC calculation.";
BA_ "GenSigStartValue" SG_ 2160080129 VCU_Crc1Val 65535;
BA_ "UserSigValidity" SG_ 2160080129 VCU_Crc1Val 7;
BA_ "RoutingFactor" SG_ 2160080129 VCU_Crc1Val 5;
BA_ "Version" SG_ 2160080129 VCU_Crc1Val "21.09.03";
BA_ "Description" SG_ 2160080129 VCU_AlvCnt1Val "For the first transmission request for a data element the counter shall be initialized with 0 and shall be incremented by 1 for every subsequent send request. 

When the counter reaches the maximum value(0xFF), then it shall restart with 0 for the next send request";
BA_ "UserSigValidity" SG_ 2160080129 VCU_AlvCnt1Val 7;
BA_ "RoutingFactor" SG_ 2160080129 VCU_AlvCnt1Val 5;
BA_ "Version" SG_ 2160080129 VCU_AlvCnt1Val "21.09.03";
BA_ "Description" SG_ 2160080129 VCU_RdySta "VCU Ready";
BA_ "UserSigValidity" SG_ 2160080129 VCU_RdySta 7;
BA_ "RoutingFactor" SG_ 2160080129 VCU_RdySta 5;
BA_ "Version" SG_ 2160080129 VCU_RdySta "20.04.05";
BA_ "Description" SG_ 2160080129 VCU_StartKeyHoldSta "Start Key Hold Signal";
BA_ "UserSigValidity" SG_ 2160080129 VCU_StartKeyHoldSta 7;
BA_ "RoutingFactor" SG_ 2160080129 VCU_StartKeyHoldSta 5;
BA_ "Version" SG_ 2160080129 VCU_StartKeyHoldSta "20.04.05";
BA_ "Description" SG_ 2160080129 VCU_EvDrvRdySta "EV Ready";
BA_ "UserSigValidity" SG_ 2160080129 VCU_EvDrvRdySta 7;
BA_ "RoutingFactor" SG_ 2160080129 VCU_EvDrvRdySta 5;
BA_ "Version" SG_ 2160080129 VCU_EvDrvRdySta "20.04.05";
BA_ "Description" SG_ 2160080129 VCU_MotPwrEnReq "Motor Power Enable";
BA_ "UserSigValidity" SG_ 2160080129 VCU_MotPwrEnReq 7;
BA_ "RoutingFactor" SG_ 2160080129 VCU_MotPwrEnReq 5;
BA_ "Version" SG_ 2160080129 VCU_MotPwrEnReq "20.04.05";
BA_ "Description" SG_ 2160080129 VCU_GearPosSta "Gear Position Status";
BA_ "GenSigStartValue" SG_ 2160080129 VCU_GearPosSta 9;
BA_ "UserSigValidity" SG_ 2160080129 VCU_GearPosSta 7;
BA_ "RoutingFactor" SG_ 2160080129 VCU_GearPosSta 5;
BA_ "Version" SG_ 2160080129 VCU_GearPosSta "21.05.01";
BA_ "Description" SG_ 2160080129 VCU_LdcInhReq "LDC Output Inhibit Request";
BA_ "GenSigStartValue" SG_ 2160080129 VCU_LdcInhReq 1;
BA_ "UserSigValidity" SG_ 2160080129 VCU_LdcInhReq 7;
BA_ "RoutingFactor" SG_ 2160080129 VCU_LdcInhReq 5;
BA_ "Version" SG_ 2160080129 VCU_LdcInhReq "20.04.05";
BA_ "Description" SG_ 2160080129 VCU_MainRlyOffReq "Main Relay Cut off Request";
BA_ "UserSigValidity" SG_ 2160080129 VCU_MainRlyOffReq 7;
BA_ "RoutingFactor" SG_ 2160080129 VCU_MainRlyOffReq 5;
BA_ "Version" SG_ 2160080129 VCU_MainRlyOffReq "20.04.05";
BA_ "Description" SG_ 2160080129 VCU_AccPedDepVal "Accelerator Pedal Depth Value";
BA_ "UserSigValidity" SG_ 2160080129 VCU_AccPedDepVal 7;
BA_ "RoutingFactor" SG_ 2160080129 VCU_AccPedDepVal 5;
BA_ "Version" SG_ 2160080129 VCU_AccPedDepVal "20.04.05";
BA_ "Description" SG_ 2160080129 VCU_FatcOperPermSta "Climate Operating Permission";
BA_ "UserSigValidity" SG_ 2160080129 VCU_FatcOperPermSta 7;
BA_ "RoutingFactor" SG_ 2160080129 VCU_FatcOperPermSta 5;
BA_ "Version" SG_ 2160080129 VCU_FatcOperPermSta "20.04.05";
BA_ "Description" SG_ 2160080129 VCU_DrvCycSta "Driving Cycle Status";
BA_ "UserSigValidity" SG_ 2160080129 VCU_DrvCycSta 7;
BA_ "RoutingFactor" SG_ 2160080129 VCU_DrvCycSta 5;
BA_ "Version" SG_ 2160080129 VCU_DrvCycSta "20.04.05";
BA_ "Description" SG_ 2160080129 VCU_CltActOpSta "Clutch Actuator Operating Status";
BA_ "UserSigValidity" SG_ 2160080129 VCU_CltActOpSta 7;
BA_ "RoutingFactor" SG_ 2160080129 VCU_CltActOpSta 5;
BA_ "Version" SG_ 2160080129 VCU_CltActOpSta "20.04.05";
BA_ "Description" SG_ 2160080129 VCU_WhlSpdSnsrAlvReq "Alive Request for Wheel Speed Sensors";
BA_ "UserSigValidity" SG_ 2160080129 VCU_WhlSpdSnsrAlvReq 7;
BA_ "RoutingFactor" SG_ 2160080129 VCU_WhlSpdSnsrAlvReq 5;
BA_ "Version" SG_ 2160080129 VCU_WhlSpdSnsrAlvReq "20.04.05";
BA_ "Description" SG_ 2160080129 VCU_DrvModOpSta "VCU's operating drive mode according to CLU and DMIC signals";
BA_ "UserSigValidity" SG_ 2160080129 VCU_DrvModOpSta 7;
BA_ "RoutingFactor" SG_ 2160080129 VCU_DrvModOpSta 5;
BA_ "Version" SG_ 2160080129 VCU_DrvModOpSta "20.08.07";
BA_ "Description" SG_ 2160080129 VCU_IgOffGearPosStaDispReq "Gear position display request @ Ig Off (to CLU )";
BA_ "UserSigValidity" SG_ 2160080129 VCU_IgOffGearPosStaDispReq 7;
BA_ "RoutingFactor" SG_ 2160080129 VCU_IgOffGearPosStaDispReq 5;
BA_ "Version" SG_ 2160080129 VCU_IgOffGearPosStaDispReq "20.12.04";
BA_ "NmMessage" BO_ 1301 1;
BA_ "GenMsgILSupport" BO_ 1301 0;
BA_ "NWM-Botschaft" BO_ 1301 1;
BA_ "UsrSigPurpose" SG_ 1301 Destination_WPC2 9;
BA_ "UserSigValidity" SG_ 1301 Destination_WPC2 0;
BA_ "UsrSigPurpose" SG_ 1301 NMCommandCode_WPC2 9;
BA_ "UserSigValidity" SG_ 1301 NMCommandCode_WPC2 0;
BA_ "UsrSigPurpose" SG_ 1301 NMSleepFlag_WPC2 9;
BA_ "UserSigValidity" SG_ 1301 NMSleepFlag_WPC2 0;
BA_ "NmMessage" BO_ 1308 1;
BA_ "GenMsgILSupport" BO_ 1308 0;
BA_ "NWM-Botschaft" BO_ 1308 1;
BA_ "UsrSigPurpose" SG_ 1308 Destination_RLPSU 9;
BA_ "UserSigValidity" SG_ 1308 Destination_RLPSU 0;
BA_ "UsrSigPurpose" SG_ 1308 NMCommandCode_RLPSU 9;
BA_ "UserSigValidity" SG_ 1308 NMCommandCode_RLPSU 0;
BA_ "UsrSigPurpose" SG_ 1308 NMSleepFlag_RLPSU 9;
BA_ "UserSigValidity" SG_ 1308 NMSleepFlag_RLPSU 0;
BA_ "NmMessage" BO_ 1336 1;
BA_ "GenMsgILSupport" BO_ 1336 0;
BA_ "NWM-Botschaft" BO_ 1336 1;
BA_ "UsrSigPurpose" SG_ 1336 Destination_DPSU 9;
BA_ "UserSigValidity" SG_ 1336 Destination_DPSU 0;
BA_ "UsrSigPurpose" SG_ 1336 NMCommandCode_DPSU 9;
BA_ "UserSigValidity" SG_ 1336 NMCommandCode_DPSU 0;
BA_ "UsrSigPurpose" SG_ 1336 NMSleepFlag_DPSU 9;
BA_ "UserSigValidity" SG_ 1336 NMSleepFlag_DPSU 0;
BA_ "NmMessage" BO_ 1345 1;
BA_ "GenMsgILSupport" BO_ 1345 0;
BA_ "NWM-Botschaft" BO_ 1345 1;
BA_ "UsrSigPurpose" SG_ 1345 Destination_PSB 9;
BA_ "UserSigValidity" SG_ 1345 Destination_PSB 0;
BA_ "UsrSigPurpose" SG_ 1345 NMCommandCode_PSB 9;
BA_ "UserSigValidity" SG_ 1345 NMCommandCode_PSB 0;
BA_ "UsrSigPurpose" SG_ 1345 NMSleepFlag_PSB 9;
BA_ "UserSigValidity" SG_ 1345 NMSleepFlag_PSB 0;
BA_ "NmMessage" BO_ 1323 1;
BA_ "GenMsgILSupport" BO_ 1323 0;
BA_ "NWM-Botschaft" BO_ 1323 1;
BA_ "UsrSigPurpose" SG_ 1323 Destination_SHVU_RR 9;
BA_ "UserSigValidity" SG_ 1323 Destination_SHVU_RR 0;
BA_ "UsrSigPurpose" SG_ 1323 NMCommandCode_SHVU_RR 9;
BA_ "UserSigValidity" SG_ 1323 NMCommandCode_SHVU_RR 0;
BA_ "UsrSigPurpose" SG_ 1323 NMSleepFlag_SHVU_RR 9;
BA_ "UserSigValidity" SG_ 1323 NMSleepFlag_SHVU_RR 0;
BA_ "NmMessage" BO_ 1329 1;
BA_ "GenMsgILSupport" BO_ 1329 0;
BA_ "NWM-Botschaft" BO_ 1329 1;
BA_ "UsrSigPurpose" SG_ 1329 Destination_APSU 9;
BA_ "UserSigValidity" SG_ 1329 Destination_APSU 0;
BA_ "UsrSigPurpose" SG_ 1329 NMCommandCode_APSU 9;
BA_ "UserSigValidity" SG_ 1329 NMCommandCode_APSU 0;
BA_ "UsrSigPurpose" SG_ 1329 NMSleepFlag_APSU 9;
BA_ "UserSigValidity" SG_ 1329 NMSleepFlag_APSU 0;
BA_ "NmMessage" BO_ 1313 1;
BA_ "GenMsgILSupport" BO_ 1313 0;
BA_ "NWM-Botschaft" BO_ 1313 1;
BA_ "UsrSigPurpose" SG_ 1313 Destination_FCS 9;
BA_ "UserSigValidity" SG_ 1313 Destination_FCS 0;
BA_ "UsrSigPurpose" SG_ 1313 NMCommandCode_FCS 9;
BA_ "UserSigValidity" SG_ 1313 NMCommandCode_FCS 0;
BA_ "UsrSigPurpose" SG_ 1313 NMSleepFlag_FCS 9;
BA_ "UserSigValidity" SG_ 1313 NMSleepFlag_FCS 0;
BA_ "NmMessage" BO_ 1297 1;
BA_ "GenMsgILSupport" BO_ 1297 0;
BA_ "NWM-Botschaft" BO_ 1297 1;
BA_ "UsrSigPurpose" SG_ 1297 Destination_EMCU 9;
BA_ "UserSigValidity" SG_ 1297 Destination_EMCU 0;
BA_ "UsrSigPurpose" SG_ 1297 NMCommandCode_EMCU 9;
BA_ "UserSigValidity" SG_ 1297 NMCommandCode_EMCU 0;
BA_ "UsrSigPurpose" SG_ 1297 NMSleepFlag_EMCU 9;
BA_ "UserSigValidity" SG_ 1297 NMSleepFlag_EMCU 0;
BA_ "NmMessage" BO_ 1307 1;
BA_ "GenMsgILSupport" BO_ 1307 0;
BA_ "NWM-Botschaft" BO_ 1307 1;
BA_ "UsrSigPurpose" SG_ 1307 Destination_SLB 9;
BA_ "UserSigValidity" SG_ 1307 Destination_SLB 0;
BA_ "UsrSigPurpose" SG_ 1307 NMCommandCode_SLB 9;
BA_ "UserSigValidity" SG_ 1307 NMCommandCode_SLB 0;
BA_ "UsrSigPurpose" SG_ 1307 NMSleepFlag_SLB 9;
BA_ "UserSigValidity" SG_ 1307 NMSleepFlag_SLB 0;
BA_ "NmMessage" BO_ 1341 1;
BA_ "GenMsgILSupport" BO_ 1341 0;
BA_ "NWM-Botschaft" BO_ 1341 1;
BA_ "UsrSigPurpose" SG_ 1341 Destination_RCM 9;
BA_ "UserSigValidity" SG_ 1341 Destination_RCM 0;
BA_ "UsrSigPurpose" SG_ 1341 NMCommandCode_RCM 9;
BA_ "UserSigValidity" SG_ 1341 NMCommandCode_RCM 0;
BA_ "UsrSigPurpose" SG_ 1341 NMSleepFlag_RCM 9;
BA_ "UserSigValidity" SG_ 1341 NMSleepFlag_RCM 0;
BA_ "NmMessage" BO_ 1290 1;
BA_ "GenMsgILSupport" BO_ 1290 0;
BA_ "NWM-Botschaft" BO_ 1290 1;
BA_ "UsrSigPurpose" SG_ 1290 Destination_ARS 9;
BA_ "UserSigValidity" SG_ 1290 Destination_ARS 0;
BA_ "UsrSigPurpose" SG_ 1290 NMCommandCode_ARS 9;
BA_ "UserSigValidity" SG_ 1290 NMCommandCode_ARS 0;
BA_ "UsrSigPurpose" SG_ 1290 NMSleepFlag_ARS 9;
BA_ "UserSigValidity" SG_ 1290 NMSleepFlag_ARS 0;
BA_ "NmMessage" BO_ 1392 1;
BA_ "GenMsgILSupport" BO_ 1392 0;
BA_ "NWM-Botschaft" BO_ 1392 1;
BA_ "UsrSigPurpose" SG_ 1392 Destination_CGW_CCU 9;
BA_ "UserSigValidity" SG_ 1392 Destination_CGW_CCU 0;
BA_ "UsrSigPurpose" SG_ 1392 NMCommandCode_CGW_CCU 9;
BA_ "UserSigValidity" SG_ 1392 NMCommandCode_CGW_CCU 0;
BA_ "UsrSigPurpose" SG_ 1392 NMSleepFlag_CGW_CCU 9;
BA_ "UserSigValidity" SG_ 1392 NMSleepFlag_CGW_CCU 0;
BA_ "NmMessage" BO_ 1360 1;
BA_ "GenMsgILSupport" BO_ 1360 0;
BA_ "NWM-Botschaft" BO_ 1360 1;
BA_ "UsrSigPurpose" SG_ 1360 Destination_ATS 9;
BA_ "UserSigValidity" SG_ 1360 Destination_ATS 0;
BA_ "UsrSigPurpose" SG_ 1360 NMCommandCode_ATS 9;
BA_ "UserSigValidity" SG_ 1360 NMCommandCode_ATS 0;
BA_ "UsrSigPurpose" SG_ 1360 NMSleepFlag_ATS 9;
BA_ "UserSigValidity" SG_ 1360 NMSleepFlag_ATS 0;
BA_ "NmMessage" BO_ 1332 1;
BA_ "GenMsgILSupport" BO_ 1332 0;
BA_ "NWM-Botschaft" BO_ 1332 1;
BA_ "UsrSigPurpose" SG_ 1332 Destination_RLHV 9;
BA_ "UserSigValidity" SG_ 1332 Destination_RLHV 0;
BA_ "UsrSigPurpose" SG_ 1332 NMCommandCode_RLHV 9;
BA_ "UserSigValidity" SG_ 1332 NMCommandCode_RLHV 0;
BA_ "UsrSigPurpose" SG_ 1332 NMSleepFlag_RLHV 9;
BA_ "UserSigValidity" SG_ 1332 NMSleepFlag_RLHV 0;
BA_ "NmMessage" BO_ 1342 1;
BA_ "GenMsgILSupport" BO_ 1342 0;
BA_ "NWM-Botschaft" BO_ 1342 1;
BA_ "UsrSigPurpose" SG_ 1342 Destination_SGU 9;
BA_ "UserSigValidity" SG_ 1342 Destination_SGU 0;
BA_ "UsrSigPurpose" SG_ 1342 NMCommandCode_SGU 9;
BA_ "UserSigValidity" SG_ 1342 NMCommandCode_SGU 0;
BA_ "UsrSigPurpose" SG_ 1342 NMSleepFlag_SGU 9;
BA_ "UserSigValidity" SG_ 1342 NMSleepFlag_SGU 0;
BA_ "NmMessage" BO_ 1325 1;
BA_ "GenMsgILSupport" BO_ 1325 0;
BA_ "NWM-Botschaft" BO_ 1325 1;
BA_ "UsrSigPurpose" SG_ 1325 Destination_PFSU 9;
BA_ "UserSigValidity" SG_ 1325 Destination_PFSU 0;
BA_ "UsrSigPurpose" SG_ 1325 NMCommandCode_PFSU 9;
BA_ "UserSigValidity" SG_ 1325 NMCommandCode_PFSU 0;
BA_ "UsrSigPurpose" SG_ 1325 NMSleepFlag_PFSU 9;
BA_ "UserSigValidity" SG_ 1325 NMSleepFlag_PFSU 0;
BA_ "NmMessage" BO_ 1348 1;
BA_ "GenMsgILSupport" BO_ 1348 0;
BA_ "NWM-Botschaft" BO_ 1348 1;
BA_ "UsrSigPurpose" SG_ 1348 Destination_ALBCU 9;
BA_ "UserSigValidity" SG_ 1348 Destination_ALBCU 0;
BA_ "UsrSigPurpose" SG_ 1348 NMCommandCode_ALBCU 9;
BA_ "UserSigValidity" SG_ 1348 NMCommandCode_ALBCU 0;
BA_ "UsrSigPurpose" SG_ 1348 NMSleepFlag_ALBCU 9;
BA_ "UserSigValidity" SG_ 1348 NMSleepFlag_ALBCU 0;
BA_ "NmMessage" BO_ 1369 1;
BA_ "GenMsgILSupport" BO_ 1369 0;
BA_ "NWM-Botschaft" BO_ 1369 1;
BA_ "UsrSigPurpose" SG_ 1369 Destination_DSAU 9;
BA_ "UserSigValidity" SG_ 1369 Destination_DSAU 0;
BA_ "UsrSigPurpose" SG_ 1369 NMCommandCode_DSAU 9;
BA_ "UserSigValidity" SG_ 1369 NMCommandCode_DSAU 0;
BA_ "UsrSigPurpose" SG_ 1369 NMSleepFlag_DSAU 9;
BA_ "UserSigValidity" SG_ 1369 NMSleepFlag_DSAU 0;
BA_ "NmMessage" BO_ 1288 1;
BA_ "GenMsgILSupport" BO_ 1288 0;
BA_ "NWM-Botschaft" BO_ 1288 1;
BA_ "UsrSigPurpose" SG_ 1288 Destination_SWRC 9;
BA_ "UserSigValidity" SG_ 1288 Destination_SWRC 0;
BA_ "UsrSigPurpose" SG_ 1288 NMCommandCode_SWRC 9;
BA_ "UserSigValidity" SG_ 1288 NMCommandCode_SWRC 0;
BA_ "UsrSigPurpose" SG_ 1288 NMSleepFlag_SWRC 9;
BA_ "UserSigValidity" SG_ 1288 NMSleepFlag_SWRC 0;
BA_ "NmMessage" BO_ 1322 1;
BA_ "GenMsgILSupport" BO_ 1322 0;
BA_ "NWM-Botschaft" BO_ 1322 1;
BA_ "UsrSigPurpose" SG_ 1322 Destination_SHVU_FR 9;
BA_ "UserSigValidity" SG_ 1322 Destination_SHVU_FR 0;
BA_ "UsrSigPurpose" SG_ 1322 NMCommandCode_SHVU_FR 9;
BA_ "UserSigValidity" SG_ 1322 NMCommandCode_SHVU_FR 0;
BA_ "UsrSigPurpose" SG_ 1322 NMSleepFlag_SHVU_FR 9;
BA_ "UserSigValidity" SG_ 1322 NMSleepFlag_SHVU_FR 0;
BA_ "NmMessage" BO_ 1350 1;
BA_ "GenMsgILSupport" BO_ 1350 0;
BA_ "NWM-Botschaft" BO_ 1350 1;
BA_ "UsrSigPurpose" SG_ 1350 Destination_RCS 9;
BA_ "UserSigValidity" SG_ 1350 Destination_RCS 0;
BA_ "UsrSigPurpose" SG_ 1350 NMCommandCode_RCS 9;
BA_ "UserSigValidity" SG_ 1350 NMCommandCode_RCS 0;
BA_ "UsrSigPurpose" SG_ 1350 NMSleepFlag_RCS 9;
BA_ "UserSigValidity" SG_ 1350 NMSleepFlag_RCS 0;
BA_ "NmMessage" BO_ 1309 1;
BA_ "GenMsgILSupport" BO_ 1309 0;
BA_ "NWM-Botschaft" BO_ 1309 1;
BA_ "UsrSigPurpose" SG_ 1309 Destination_RRPSU 9;
BA_ "UserSigValidity" SG_ 1309 Destination_RRPSU 0;
BA_ "UsrSigPurpose" SG_ 1309 NMCommandCode_RRPSU 9;
BA_ "UserSigValidity" SG_ 1309 NMCommandCode_RRPSU 0;
BA_ "UsrSigPurpose" SG_ 1309 NMSleepFlag_RRPSU 9;
BA_ "UserSigValidity" SG_ 1309 NMSleepFlag_RRPSU 0;
BA_ "NmMessage" BO_ 1352 1;
BA_ "GenMsgILSupport" BO_ 1352 0;
BA_ "NWM-Botschaft" BO_ 1352 1;
BA_ "UsrSigPurpose" SG_ 1352 Destination_BLTN_CAM 9;
BA_ "UserSigValidity" SG_ 1352 Destination_BLTN_CAM 0;
BA_ "UsrSigPurpose" SG_ 1352 NMCommandCode_BLTN_CAM 9;
BA_ "UserSigValidity" SG_ 1352 NMCommandCode_BLTN_CAM 0;
BA_ "UsrSigPurpose" SG_ 1352 NMSleepFlag_BLTN_CAM 9;
BA_ "UserSigValidity" SG_ 1352 NMSleepFlag_BLTN_CAM 0;
BA_ "NmMessage" BO_ 1287 1;
BA_ "GenMsgILSupport" BO_ 1287 0;
BA_ "NWM-Botschaft" BO_ 1287 1;
BA_ "UsrSigPurpose" SG_ 1287 Destination_SCM 9;
BA_ "UserSigValidity" SG_ 1287 Destination_SCM 0;
BA_ "UsrSigPurpose" SG_ 1287 NMCommandCode_SCM 9;
BA_ "UserSigValidity" SG_ 1287 NMCommandCode_SCM 0;
BA_ "UsrSigPurpose" SG_ 1287 NMSleepFlag_SCM 9;
BA_ "UserSigValidity" SG_ 1287 NMSleepFlag_SCM 0;
BA_ "NmMessage" BO_ 1344 1;
BA_ "GenMsgILSupport" BO_ 1344 0;
BA_ "NWM-Botschaft" BO_ 1344 1;
BA_ "UsrSigPurpose" SG_ 1344 Destination_DLBCU 9;
BA_ "UserSigValidity" SG_ 1344 Destination_DLBCU 0;
BA_ "UsrSigPurpose" SG_ 1344 NMCommandCode_DLBCU 9;
BA_ "UserSigValidity" SG_ 1344 NMCommandCode_DLBCU 0;
BA_ "UsrSigPurpose" SG_ 1344 NMSleepFlag_DLBCU 9;
BA_ "UserSigValidity" SG_ 1344 NMSleepFlag_DLBCU 0;
BA_ "NmMessage" BO_ 1364 1;
BA_ "GenMsgILSupport" BO_ 1364 0;
BA_ "NWM-Botschaft" BO_ 1364 1;
BA_ "UsrSigPurpose" SG_ 1364 Destination_OHCL 9;
BA_ "UserSigValidity" SG_ 1364 Destination_OHCL 0;
BA_ "UsrSigPurpose" SG_ 1364 NMCommandCode_OHCL 9;
BA_ "UserSigValidity" SG_ 1364 NMCommandCode_OHCL 0;
BA_ "UsrSigPurpose" SG_ 1364 NMSleepFlag_OHCL 9;
BA_ "UserSigValidity" SG_ 1364 NMSleepFlag_OHCL 0;
BA_ "NmMessage" BO_ 1311 1;
BA_ "GenMsgILSupport" BO_ 1311 0;
BA_ "NWM-Botschaft" BO_ 1311 1;
BA_ "UsrSigPurpose" SG_ 1311 Destination_RWPC 9;
BA_ "UserSigValidity" SG_ 1311 Destination_RWPC 0;
BA_ "UsrSigPurpose" SG_ 1311 NMCommandCode_RWPC 9;
BA_ "UserSigValidity" SG_ 1311 NMCommandCode_RWPC 0;
BA_ "UsrSigPurpose" SG_ 1311 NMSleepFlag_RWPC 9;
BA_ "UserSigValidity" SG_ 1311 NMSleepFlag_RWPC 0;
BA_ "NmMessage" BO_ 1333 1;
BA_ "GenMsgILSupport" BO_ 1333 0;
BA_ "NWM-Botschaft" BO_ 1333 1;
BA_ "UsrSigPurpose" SG_ 1333 Destination_RRHV 9;
BA_ "UserSigValidity" SG_ 1333 Destination_RRHV 0;
BA_ "UsrSigPurpose" SG_ 1333 NMCommandCode_RRHV 9;
BA_ "UserSigValidity" SG_ 1333 NMCommandCode_RRHV 0;
BA_ "UsrSigPurpose" SG_ 1333 NMSleepFlag_RRHV 9;
BA_ "UserSigValidity" SG_ 1333 NMSleepFlag_RRHV 0;
BA_ "NmMessage" BO_ 1310 1;
BA_ "GenMsgILSupport" BO_ 1310 0;
BA_ "NWM-Botschaft" BO_ 1310 1;
BA_ "UsrSigPurpose" SG_ 1310 Destination_WPC 9;
BA_ "UserSigValidity" SG_ 1310 Destination_WPC 0;
BA_ "UsrSigPurpose" SG_ 1310 NMCommandCode_WPC 9;
BA_ "UserSigValidity" SG_ 1310 NMCommandCode_WPC 0;
BA_ "UsrSigPurpose" SG_ 1310 NMSleepFlag_WPC 9;
BA_ "UserSigValidity" SG_ 1310 NMSleepFlag_WPC 0;
BA_ "NmMessage" BO_ 1354 1;
BA_ "GenMsgILSupport" BO_ 1354 0;
BA_ "NWM-Botschaft" BO_ 1354 1;
BA_ "UsrSigPurpose" SG_ 1354 Destination_HOD 9;
BA_ "UserSigValidity" SG_ 1354 Destination_HOD 0;
BA_ "UsrSigPurpose" SG_ 1354 NMCommandCode_HOD 9;
BA_ "UserSigValidity" SG_ 1354 NMCommandCode_HOD 0;
BA_ "UsrSigPurpose" SG_ 1354 NMSleepFlag_HOD 9;
BA_ "UserSigValidity" SG_ 1354 NMSleepFlag_HOD 0;
BA_ "NmMessage" BO_ 1363 1;
BA_ "GenMsgILSupport" BO_ 1363 0;
BA_ "NWM-Botschaft" BO_ 1363 1;
BA_ "UsrSigPurpose" SG_ 1363 Destination_ASAU 9;
BA_ "UserSigValidity" SG_ 1363 Destination_ASAU 0;
BA_ "UsrSigPurpose" SG_ 1363 NMCommandCode_ASAU 9;
BA_ "UserSigValidity" SG_ 1363 NMCommandCode_ASAU 0;
BA_ "UsrSigPurpose" SG_ 1363 NMSleepFlag_ASAU 9;
BA_ "UserSigValidity" SG_ 1363 NMSleepFlag_ASAU 0;
VAL_ 1193 C_PTGMNValueSet 0 "Default" 1 "Power Mode" 2 "Manual Mode" 3 "Invalid" ;
VAL_ 1193 CF_AVN_PSMNValueSet 0 "Default" 1 "Off(Disable)" 2 "50mm On(Enable)" 3 "75mm On(Enable)" 4 "Reserved" 5 "Reserved" 6 "Reserved" 7 "Invalid" ;
VAL_ 1193 C_HfreeTrunkTgNValueSet 0 "Default" 1 "HandsFree Off" 2 "HandsFree On" 3 "Reserved" 4 "Invalid" 5 "Reserved" 6 "Reserved" 7 "Reserved" ;
VAL_ 1193 CF_AVN_TrfChgSet 0 "Default" 1 "Disable(Off)" 2 "Enable(On)" 3 "Invalid" ;
VAL_ 1193 CF_AVN_SCMNValueSet 0 "Default" 1 "Steering Off" 2 "Steering On" 3 "Invalid" ;
VAL_ 1193 CF_AVN_ADrUNValueSet 0 "Default" 1 "Off" 2 "Key Out On(All Doors)" 3 "Shift Lever On(All Doors)" 4 "Override" 5 "Invalid" 6 "Key Out On(Driver Door)" 7 "Shift Lever On(Driver Door)" ;
VAL_ 1193 CF_AVN_OTTurnNValueSet 0 "Default" 1 "One Touch Turn Off" 2 "3 Flashing" 3 "5 Flashing" 4 "7 Flashing" 5 "Invalid" 6 "Reserved" 7 "Reserved" ;
VAL_ 1193 CF_Gway_WPCNValueSet 0 "Default" 1 "Off(Disable)" 2 "On(Enable)" 3 "Invalid" ;
VAL_ 1193 C_AVN_RearWiperNValueSet 0 "Default" 1 "Rear Wiper(Reverse) Off" 2 "Rear Wiper(Reverse) On" 3 "Invalid" ;
VAL_ 1193 C_UnlockWelocomeNValueSet 0 "Default" 1 "Off" 2 "On" 3 "Invalid" ;
VAL_ 1193 C_SmartWelocomeNValueSet 0 "Default" 1 "Off" 2 "On" 3 "Invalid" ;
VAL_ 1193 CF_AVN_PTGSpeedNValueSet 0 "Default" 1 "Fast" 2 "Slow" 3 "Invalid" ;
VAL_ 1193 CR_Datc_DRSeatWheel_USM_Set 0 "Default" 1 "Off" 2 "On" 3 "Invalid" ;
VAL_ 1193 CF_AVN_TTUnlockNValueSet 0 "Default" 1 "Off" 2 "On" 3 "Invalid" ;
VAL_ 1193 CF_Gway_RWPCNValueSet 0 "Default" 1 "Off" 2 "On" 3 "Invalid" ;
VAL_ 1193 CF_Avn_HAPTICWARNINGNValueSet 0 "Default" 1 "Weak" 2 "Medium" 3 "Strong" 4 "Reserved" 5 "Reserved" 6 "Off" 7 "Invalid" ;
VAL_ 1193 CR_Datc_DRSeatHeat_USM_Set 0 "Default" 1 "Off" 2 "On" 3 "Invalid" ;
VAL_ 1193 C_WALNValueSet 0 "Default" 1 "Off" 2 "On" 3 "Invalid" ;
VAL_ 1193 C_ApprUnlockNValue 0 "Defualt" 1 "Approach Unlock OFF" 2 "Approach Unlock ON" 3 "Invalid" ;
VAL_ 1193 CF_AVN_EscortHLNValueSet 0 "Default" 1 "Escort Off" 2 "Escort On" 3 "Invalid" ;
VAL_ 491 CF_AVN_Roof_OprLvSet 0 "Default" 1 "Off" 2 "Level1" 3 "Level2" 4 "Level3" 5 "Level4" 6 "Level5" 7 "Invalid" ;
VAL_ 491 CF_AVN_3rdRightDoor_OptLvlSet 0 "Default" 1 "Off" 2 "Level1" 3 "Level2" 4 "Level3" 5 "Level4" 6 "Level5" 7 "Invalid" ;
VAL_ 491 CF_AVN_RearDoor_OptLvlSet 0 "Default" 1 "Off" 2 "Level1" 3 "Level2" 4 "Level3" 5 "Level4" 6 "Level5" 7 "Invalid" ;
VAL_ 491 CF_AVN_RollBlindOnOffSet 0 "Default" 1 "Off" 2 "On" 3 "Invalid" ;
VAL_ 491 CF_AVN_CluThmAutoSet_New 0 "Default" 1 "Disable" 2 "Enable" 3 "Invalid" ;
VAL_ 491 CF_AVN_CluThmSet_New 0 "Default" 1 "Select Theme 1" 2 "Select Theme 2" 3 "Select Theme 3" 4 "Select Theme 4" 5 "Select Theme 5" 6 "Select Theme 6" 7 "Invalid" ;
VAL_ 491 CF_AVN_CluThmDtlSet_New 0 "Default" 1 "Select Theme 1" 2 "Select Theme 2" 3 "Select Theme 3" 4 "Select Theme 4" 5 "Select Theme 5" 6 "Select Theme 6" 7 "Invalid" ;
VAL_ 491 CF_AVN_MdLmpAIVoiceUSMNValueSet 0 "Default" 1 "Off" 2 "On" 3 "Invalid" ;
VAL_ 491 CF_AVN_2ndLeftDoor_OptLvSet 0 "Default" 1 "Off" 2 "Level1" 3 "Level2" 4 "Level3" 5 "Level4" 6 "Level5" 7 "Invalid" ;
VAL_ 491 CF_AVN_DWL_SelectNvalueSet 0 "Default" 1 "Select Concept A" 2 "Select Concept B" 3 "Select Concept C" 4 "Select Concept D" 5 "Select Concept E" 6 "Select Concept F" 7 "Select Concept G" 8 "Select Concept H" 9 "Select Concept I" 10 "Select Concept J" 11 "RESERVED" 12 "RESERVED" 13 "RESERVED" 14 "RESERVED" 15 "Invalid" ;
VAL_ 491 CF_AVN_FrArmRestHeatNValueSet 0 "Default" 1 "Off" 2 "On" 3 "Invalid" ;
VAL_ 491 CF_AVN_RrArmRestHeatNValueSet 0 "Default" 1 "Off" 2 "On" 3 "Invalid" ;
VAL_ 491 CF_Gway_WPCAnimationNvalueSet 0 "Default" 1 "Type 1 (Animation Off)" 2 "Type 2 (Animation On)" 3 "Reserved" 4 "Reserved" 5 "Reserved" 6 "Reserved" 7 "Invalid" ;
VAL_ 491 USM_BtnIllumiAlwaysOnReq 0 "Default" 1 "Off" 2 "On" 3 "Invalid" ;
VAL_ 491 CF_AVN_LKAWrngVolNvalueSet 0 "Default" 1 "Off" 2 "On" 3 "Invalid" ;
VAL_ 491 DAB_IlluminationVrModeSet 0 "Default" 1 "AI Voice Start" 2 "User Response" 3 "User No Response" 4 "Processing" 5 "AI Voice Response" 6 "AI Voice End" 7 "Invalid" ;
VAL_ 491 USM_IllAlwaysOnwithPSTNReq 0 "Default" 1 "OFF" 2 "illumination Always On" 3 "illumination Always On with PSTN" 4 "RESERVED" 5 "RESERVED" 6 "RESERVED" 7 "Invalid" ;
VAL_ 491 CF_AVN_AutoStopTimerResetSet 0 "Default" 1 "Manual Reset" 2 "Link to Current Trip" 3 "Since Refueling" 4 "Since Reset" 5 "RESERVED" 6 "RESERVED" 7 "Invalid" ;
VAL_ 491 CF_AVN_2ndRightDoor_OptLvSet 0 "Default" 1 "Off" 2 "Level1" 3 "Level2" 4 "Level3" 5 "Level4" 6 "Level5" 7 "Invalid" ;
VAL_ 491 USM_RrCurtainSet 0 "Default" 1 "Off" 2 "On" 3 "Invalid" ;
VAL_ 491 CF_AVN_3rdLeftDoor_OptLvlSet 0 "Default" 1 "Off" 2 "Level1" 3 "Level2" 4 "Level3" 5 "Level4" 6 "Level5" 7 "Invalid" ;
VAL_ 1076 IAU_ProfileIDRVal 0 "Default" 1 "Guest" 2 "Profile1" 3 "Profile2" 4 "Reserved" 5 "Reserved" 6 "Reserved" 7 "Reserved" 8 "Reserved" 9 "Reserved" 10 "Reserved" 11 "Reserved" 12 "Reserved" 13 "Reserved" 14 "Reserved" 15 "Invalid" ;
VAL_ 1076 IAU_DigitalKeyProcessingSta 0 "None" 1 "DeviceOnWPC" 2 "DeviceRegistering" 3 "PhoneRegistered" 4 "All Phone Key Deleted" 5 "NFCCard1Registered" 6 "Server Registering" 7 "NFCCard1Deleted" 8 "BLE Searching" 9 "Owner Phone key Deleted" 10 "Valet Off Searching" 11 "Server Registering Fail" 12 "Reserved" 13 "Reserved" 14 "Reserved" 15 "Invalid" ;
VAL_ 1076 IAU_DigitalKeyExit 0 "Normal" 1 "Check System" 2 "NFC Not Detected" 3 "Fob Not Detected" 4 "Canceled by User (Timeout)" 5 "Device not Available" 6 "ProcessFail" 7 "Check Card Save" 8 "Certificate Update" 9 "Valet Off Fail" 10 "CardNotAvailable" 11 "DigitalKeyDisabled" 12 "KeyNotSaved" 13 "Check Password" 14 "P position fail (not P)" 15 "Invalid" ;
VAL_ 1076 IAU_DigitalKeyEnblRVal 0 "Default" 1 "Disable" 2 "Enable" 3 "Invalid" ;
VAL_ 1076 IAU_OwnerPhnRegRVal 0 "Default" 1 "Disable" 2 "Enable" 3 "Invalid" ;
VAL_ 1076 IAU_NFCCard1RegRVal 0 "Default" 1 "Disable" 2 "Enable" 3 "Invalid" ;
VAL_ 1076 IAU_NFCCard2RegRVal 0 "Default" 1 "Disable" 2 "Enable" 3 "Invalid" ;
VAL_ 1076 IAU_DISPWrng 0 "None" 1 "Auth_Fail2 (DigitalKey)" 2 "ReAuth_Warning" 3 "IAU Error" 4 "DigitalKey Saved" 5 "Auth_Fail2 (FP)" 6 "Auth_Fail2 (DigitalKey or FP)" 7 "BiometricKey Saved" 8 "DigitalKey and BiometricKey Saved" 9 "WPCNFC_PreStartAuth_Success" 10 "Reserved" 11 "Reserved" 12 "Reserved" 13 "Reserved" 14 "ReAuth_forRSPA" 15 "Invalid" ;
VAL_ 1076 IAU_DigitalKey2Opt 0 "Default (Not applied)" 1 "Digital Key Light (NFC)" 2 "Digital Key Medium (NFC/BLE)" 3 "Digital Key Full (NFC/BLE/UWB)" 4 "Reserved" 5 "Reserved" 6 "Reserved" 7 "invalid" ;
VAL_ 1076 IAUwFRULearnState 0 "Default (Normal)" 1 "Learning" 2 "Neutralizing" 3 "Invalid" ;
VAL_ 1076 IAUwFPMLearnState 0 "Default(Normal)" 1 "Learning" 2 "Neutralizing" 3 "Invalid" ;
VAL_ 1073 USM_ValCmdSta 0 "Default" 1 "Off(Disable)" 2 "On(Enable)" 3 "Invalid" ;
VAL_ 1073 RWPC_SWVerMinor1 0 "0x0x0~0x7F:ASCII Code Value (HEX)" 127 "0x0x0~0x7F:ASCII Code Value (HEX)" ;
VAL_ 1073 WPC_PhnLftWrngRWPCSta 0 "Off" 1 "Cellphone on the pad" 2 "Charging" 3 "Charging complete" 4 "Cellphone reminder" 5 "Error" 6 "Reserved" 7 "Invalid" ;
VAL_ 1073 RWPC_SWVerMinor2 0 "0x0x0~0x7F:ASCII Code Value (HEX)" 127 "0x0x0~0x7F:ASCII Code Value (HEX)" ;
VAL_ 1073 RWPC_IndSyncVal 0 "default" 1 "off" 2 "1st sync" 3 "2nd sync" 4 "3rd sync" 5 "error off" 6 "error on" 7 "reserved" ;
VAL_ 1073 USM_ValCmdStaforATS 0 "Default" 1 "Off(Disable)" 2 "On(Enable)" 3 "Invalid" ;
VAL_ 1073 RWPC_SWVerMajor1 0 "ASCII Code Value (HEX)" 1 "ASCII Code Value (HEX)" 2 "ASCII Code Value (HEX)" 3 "ASCII Code Value (HEX)" 4 "ASCII Code Value (HEX)" 5 "ASCII Code Value (HEX)" 6 "ASCII Code Value (HEX)" 7 "ASCII Code Value (HEX)" 8 "ASCII Code Value (HEX)" 9 "ASCII Code Value (HEX)" 10 "ASCII Code Value (HEX)" 11 "ASCII Code Value (HEX)" 12 "ASCII Code Value (HEX)" 13 "ASCII Code Value (HEX)" 14 "ASCII Code Value (HEX)" 15 "ASCII Code Value (HEX)" ;
VAL_ 858 AST_CrashUnlockCmd 0 "Off" 1 "Unlock (Crash)" ;
VAL_ 858 DoorLock_CtrlDrLkSwSta_SBCM 0 "Off" 1 "On (Lock On)" 2 "Not Used" 3 "Error Indicator" ;
VAL_ 858 DoorLock_CtrlDrUnLkSwSta_SBCM 0 "Off" 1 "On (Unlock On)" 2 "Not Used" 3 "Error Indicator" ;
VAL_ 858 Warn_AsstDrSwSta_SBCM 0 "Close" 1 "Open" 2 "RESERVED" 3 "Error Indicator" ;
VAL_ 858 DoorLock_AsstDrUnLkSta_SBCM 0 "Lock" 1 "Unlock" 2 "Not Used" 3 "Error Indicator" ;
VAL_ 858 AST_SEAWarn_RH 0 "SEA Right Warning OFF" 1 "SEA Right Warning ON" 2 "Reserved" 3 "Invalid" ;
VAL_ 858 AST_SEAWarn_LH 0 "SEA Left Warning OFF" 1 "SEA Left Warning ON" 2 "Reserved" 3 "Invalid" ;
VAL_ 858 AST_SEWWarn_LH 0 "SEW Left Warning OFF" 1 "SEW Left Warning ON" 2 "Reserved" 3 "Invalid" ;
VAL_ 858 AST_SEWWarn_RH 0 "SEW Right Warning OFF" 1 "SEW Right Warning ON" 2 "Reserved" 3 "Invalid" ;
VAL_ 858 AST_MRActivationAlarm 0 "Off" 1 "On" 2 "Not Used" 3 "Error Indicator" ;
VAL_ 858 AST_ReleaseWarn 0 "Release Warning OFF" 1 "Release Warning ON" 2 "Reserved" 3 "Invalid" ;
VAL_ 858 USM_AstGhostDoorSta 0 "Default" 1 "Off" 2 "On" 3 "Invalid" ;
VAL_ 858 AST_SWFailAlarm 0 "Off" 1 "On" 2 "Not Used" 3 "Error Indicator" ;
VAL_ 858 DoorLock_PDSLkSwSta_AST 0 "Lock" 1 "Unlock" 2 "Not Used" 3 "Error Indicator" ;
VAL_ 858 PDS_TypeOption_AST 0 "Off" 1 "On" 2 "Not Used" 3 "Error Indicator" ;
VAL_ 858 AFCU_AutoWashModeSta_SBCM_AST 0 "Default" 1 "AFCU Auto Wash Mode Off (Ready)" 2 "AFCU Auto Wash Mode Off (Error)" 3 "AFCU Auto Wash Mode On" 4 "RESERVED" 5 "RESERVED" 6 "RESERVED" 7 "Invalid" ;
VAL_ 858 CDM_AutoWashModeSta_SBCM_AST 0 "Default" 1 "CDM Auto Wash Mode Off (Ready)" 2 "CDM Auto Wash Mode Off (Error)" 3 "CDM Auto Wash Mode On" 4 "RESERVED" 5 "RESERVED" 6 "RESERVED" 7 "Invalid" ;
VAL_ 858 ASTDoorPushAlarm 0 "Off" 1 "On" 2 "Not Used" 3 "Error Indicator" ;
VAL_ 799 DRV_CrashUnlockCmd 0 "Off" 1 "Unlock(Crash)" ;
VAL_ 799 C_ApprOpenStatus 0 "Approach Open Off" 1 "Approach Open On" ;
VAL_ 799 DoorLock_DrvKeyLkSwSta_SBCM 0 "Off" 1 "Lock" 2 "Not Used" 3 "Error Indicator" ;
VAL_ 799 DoorLock_DrvKeyUnLkSwSta_SBCM 0 "Off" 1 "Unlock" 2 "Not Used" 3 "Error Indicator" ;
VAL_ 799 Warn_DrvDrSwSta_SBCM 0 "Close" 1 "Open" 2 "RESERVED" 3 "Error Indicator" ;
VAL_ 799 DoorLock_DrvDrUnLkSta_SBCM 0 "Lock" 1 "Unlock" 2 "Not Used" 3 "Error Indicator" ;
VAL_ 799 DRV_SEAWarn_LH 0 "SEA Left Warning OFF" 1 "SEA Left Warning ON" 2 "Reserved" 3 "Invalid" ;
VAL_ 799 DRV_SEAWarn_RH 0 "SEA Right Warning OFF" 1 "SEA Right  Warning ON" 2 "Reserved" 3 "Invalid" ;
VAL_ 799 DRV_SEWWarn_LH 0 "SEW Left Warning OFF" 1 "SEW Left Warning ON" 2 "Reserved" 3 "Invalid" ;
VAL_ 799 DRV_SEWWarn_RH 0 "SEW Right Warning OFF" 1 "SEW Right Warning ON" 2 "Reserved" 3 "Invalid" ;
VAL_ 799 DRV_MRActivationAlarm 0 "Off" 1 "On" 2 "Not Used" 3 "Error Indicator" ;
VAL_ 799 DRV_ReleaseWarn 0 "Release Warning OFF" 1 "Release Warning ON" 2 "Reserved" 3 "Invalid" ;
VAL_ 799 Latch_TypeOption_DRV 0 "Off" 1 "On" 2 "Not Used" 3 "Error Indicator" ;
VAL_ 799 DRV_SWFailAlarm 0 "Off" 1 "On" 2 "Not Used" 3 "Error Indicator" ;
VAL_ 799 USM_PwrDRApprOpnSetSta 0 "Default" 1 "Off" 2 "On" 3 "Invalid" ;
VAL_ 799 USM_PwrDRApprOpnSetOpt 0 "Default" 1 "Off" 2 "On" 3 "Invalid" ;
VAL_ 799 USM_PwrDRCloseByRKELockSta 0 "Default" 1 "Off" 2 "On" 3 "Invalid" ;
VAL_ 799 USM_PwrDRCloseByRKELockOpt 0 "Default" 1 "Off" 2 "On" 3 "Invalid" ;
VAL_ 799 USM_PwrDRCloseByBrakeSta 0 "Default" 1 "Off" 2 "On" 3 "Invalid" ;
VAL_ 799 USM_PwrDRCloseByBrakeOpt 0 "Default" 1 "Off" 2 "On" 3 "Invalid" ;
VAL_ 799 USM_PwrDRBuzzerSta 0 "Default" 1 "Off" 2 "On" 3 "Invalid" ;
VAL_ 799 USM_PwrDRBuzzerOpt 0 "Default" 1 "Off" 2 "On" 3 "Invalid" ;
VAL_ 799 PDS_TypeOption_DRV 0 "Off" 1 "On" 2 "Not Used" 3 "Error Indicator" ;
VAL_ 799 C_DrvDoorApproachOpen 0 "Default" 1 "Approach Open Request" 2 "Approach Open Stop" 3 "Not Used" ;
VAL_ 799 C_DrvDoorApproachClose 0 "Default" 1 "Approach Close Request" 2 "Approach Close Stop" 3 "Not Used" ;
VAL_ 799 DoorLock_PDSLkSwSta_DRV 0 "Default" 1 "Lock" 2 "Not Used" 3 "Error Indicator" ;
VAL_ 799 DRVDoorPushAlarm 0 "Off" 1 "On" 2 "Not Used" 3 "Error Indicator" ;
VAL_ 862 RL_CrashUnlockCmd 0 "Off" 1 "Unlock(Crash)" ;
VAL_ 862 Warn_RrLftDrSwSta_SBCM 0 "Close" 1 "Open" 2 "RESERVED" 3 "Error Indicator" ;
VAL_ 862 DoorLock_RrLftDrUnLkSta_SBCM 0 "Lock" 1 "Unlock" 2 "Not Used" 3 "Error Indicator" ;
VAL_ 862 RL_SEAActivated 0 "InActivated" 1 "Activated" 2 "Not Used" 3 "Error Indicator" ;
VAL_ 862 RL_SEAWarn 0 "SEA Left Warning OFF" 1 "SEA Left Warning ON" 2 "Reserved" 3 "Invalid" ;
VAL_ 862 RL_SEWWarn 0 "SEW Left Warning OFF" 1 "SEW Left Warning ON" 2 "Reserved" 3 "InvalidInvalid" ;
VAL_ 862 RL_ReleaseWarn 0 "Release Warning OFF" 1 "Release Warning ON" 2 "Reserved" 3 "Invalid" ;
VAL_ 862 RL_SWFailAlarm 0 "Off" 1 "On" 2 "Not Used" 3 "Error Indicator" ;
VAL_ 862 RL_ChildLock_ActnFlSta 0 "OK" 1 "Failed" 2 "Not Used" 3 "Error Indicator" ;
VAL_ 862 RL_MRActivationAlarm 0 "Off" 1 "On" 2 "Not Used" 3 "Error Indicator" ;
VAL_ 862 RL_ChildLock_Status 0 "ChildLock On" 1 "ChildLock Off" 2 "RESERVED" 3 "RESERVED" ;
VAL_ 862 USM_RLGhostDoorSta 0 "Default" 1 "Off" 2 "On" 3 "Invalid" ;
VAL_ 862 DoorLock_PDSLkSwSta_RL 0 "Lock" 1 "Unlock" 2 "Not Used" 3 "Error Indicator" ;
VAL_ 862 PDS_TypeOption_RL 0 "Off" 1 "On" 2 "Not Used" 3 "Error Indicator" ;
VAL_ 862 RLDoorPushAlarm 0 "Off" 1 "On" 2 "Not Used" 3 "Error Indicator" ;
VAL_ 905 RR_CrashUnlockCmd 0 "Off" 1 "Unlock (Crash)" ;
VAL_ 905 Warn_RrRtDrSwSta_SBCM 0 "Close" 1 "Open" 2 "RESERVED" 3 "Error Indicator" ;
VAL_ 905 DoorLock_RrRtDrUnLkSta_SBCM 0 "Lock" 1 "Unlock" 2 "Not Used" 3 "Error Indicator" ;
VAL_ 905 RR_SEAActivated 0 "InActivated" 1 "Activated" 2 "Not Used" 3 "Error Indicator" ;
VAL_ 905 RR_SEAWarn 0 "SEA Right Warning OFF" 1 "SEA Right Warning ON" 2 "Reserved" 3 "Invalid" ;
VAL_ 905 RR_SEWWarn 0 "SEW Right Warning OFF" 1 "SEW Right Warning ON" 2 "Reserved" 3 "Invalid" ;
VAL_ 905 RR_ReleaseWarn 0 "Release Warning OFF" 1 "Release Warning ON" 2 "Reserved" 3 "Invalid" ;
VAL_ 905 RR_SWFailAlarm 0 "Off" 1 "On" 2 "Not Used" 3 "Error Indicator" ;
VAL_ 905 RR_ChildLock_ActnFlSta 0 "OK" 1 "Failed" 2 "Not Used" 3 "Error Indicator" ;
VAL_ 905 RR_MRActivationAlarm 0 "Off" 1 "On" 2 "Not Used" 3 "Error Indicator" ;
VAL_ 905 RR_ChildLock_Status 0 "ChildLock On" 1 "ChildLock Off" 2 "RESERVED" 3 "RESERVED" ;
VAL_ 905 USM_RRGhostDoorSta 0 "Default" 1 "Off" 2 "On" 3 "Invalid" ;
VAL_ 905 DoorLock_PDSLkSwSta_RR 0 "Lock" 1 "Unlock" 2 "Not Used" 3 "Error Indicator" ;
VAL_ 905 PDS_TypeOption_RR 0 "Off" 1 "On" 2 "Not Used" 3 "Error Indicator" ;
VAL_ 905 RRDoorPushAlarm 0 "Off" 1 "On" 2 "Not Used" 3 "Error Indicator" ;
VAL_ 2160080129 VCU_Crc1Val 0 "0x0x0~0xFFFF:CRCValue" 65535 "0x0x0~0xFFFF:CRCValue" ;
VAL_ 2160080129 VCU_AlvCnt1Val 0 "0x0x0~0xFF:AlvCntValue" 255 "0x0x0~0xFF:AlvCntValue" ;
VAL_ 2160080129 VCU_RdySta 0 "None" 1 "VCU Control Board Ready" 2 "Not used" 3 "Error Indicator" ;
VAL_ 2160080129 VCU_StartKeyHoldSta 0 "None" 1 "Start" 2 "Not used" 3 "Error Indicator" ;
VAL_ 2160080129 VCU_EvDrvRdySta 0 "None" 1 "EV Drivable" 2 "Not used" 3 "Error Indicator" ;
VAL_ 2160080129 VCU_MotPwrEnReq 0 "None" 1 "Allow Motor System to Control" 2 "Not used" 3 "Error Indicator" ;
VAL_ 2160080129 VCU_GearPosSta 0 "P" 1 "B" 2 "Not Used" 3 "Not Used" 4 "Not Used" 5 "D" 6 "N" 7 "R" 8 "Not Used" 9 "Not Display at Cluster" 10 "Reserved" 11 "Reserved" 12 "Reserved" 13 "Reserved" 14 "Intermediate Position" 15 "Fault" ;
VAL_ 2160080129 VCU_LdcInhReq 0 "None" 1 "LDC Off Request" 2 "Not used" 3 "Error Indicator" ;
VAL_ 2160080129 VCU_MainRlyOffReq 0 "None" 1 "Relay Cut Off" 2 "Not used" 3 "Error Indicator" ;
VAL_ 2160080129 VCU_AccPedDepVal 255 "Error Indicator" ;
VAL_ 2160080129 VCU_FatcOperPermSta 0 "Not Permiited" 1 "Permitted" 2 "Not used" 3 "Error Indicator" ;
VAL_ 2160080129 VCU_DrvCycSta 0 "No Driving Cycle Active" 1 "Driving Cycle Active" 2 "Not used" 3 "Error Indicator" ;
VAL_ 2160080129 VCU_CltActOpSta 0 "Neutral" 1 "Actuating" 2 "In Gear" 3 "Referencing" 4 "Fault" ;
VAL_ 2160080129 VCU_WhlSpdSnsrAlvReq 0 "No Request" 1 "Alive Request" 2 "Not used" 3 "Error Indicator" ;
VAL_ 2160080129 VCU_DrvModOpSta 0 "Eco" 1 "Normal" 2 "Sport" 3 "Reserved" 4 "Reserved" 5 "Snow" 6 "Sand" 7 "Mud" 8 "Reserved" 9 "Reserved" 10 "Reserved" 11 "Reserved" 12 "Reserved" 13 "Reserved" 14 "Reserved" 15 "Reserved" ;
VAL_ 2160080129 VCU_IgOffGearPosStaDispReq 0 "No Request" 1 "Request" 2 "Not used" 3 "Error indicator" ;
VAL_ 1301 Destination_WPC2 0 "0x0x0~0xFF:NM Source Node ID" 255 "0x0x0~0xFF:NM Source Node ID" ;
VAL_ 1301 NMCommandCode_WPC2 1 "Alive" 2 "Ring" 3 "RESERVED" 4 "Limphome" 5 "0x5~0xFF:RESERVED" 255 "0x5~0xFF:RESERVED" ;
VAL_ 1301 NMSleepFlag_WPC2 0 "Alive" 1 "SleepInd" 2 "RESERVED" 3 "SleepAck" ;
VAL_ 1308 Destination_RLPSU 0 "0x0x0~0xFF:NM Source Node ID" 255 "0x0x0~0xFF:NM Source Node ID" ;
VAL_ 1308 NMCommandCode_RLPSU 1 "Alive" 2 "Ring" 3 "RESERVED" 4 "Limphome" 5 "0x5~0xFF:RESERVED" 255 "0x5~0xFF:RESERVED" ;
VAL_ 1308 NMSleepFlag_RLPSU 0 "Alive" 1 "SleepInd" 2 "RESERVED" 3 "SleepAck" ;
VAL_ 1336 Destination_DPSU 0 "0x0x0~0xFF:NM Source Node ID" 255 "0x0x0~0xFF:NM Source Node ID" ;
VAL_ 1336 NMCommandCode_DPSU 1 "Alive" 2 "Ring" 3 "RESERVED" 4 "Limphome" 5 "0x5~0xFF:RESERVED" 255 "0x5~0xFF:RESERVED" ;
VAL_ 1336 NMSleepFlag_DPSU 0 "Alive" 1 "SleepInd" 2 "RESERVED" 3 "SleepAck" ;
VAL_ 1345 Destination_PSB 0 "0x0x0~0xFF:NM Source Node ID" 255 "0x0x0~0xFF:NM Source Node ID" ;
VAL_ 1345 NMCommandCode_PSB 1 "Alive" 2 "Ring" 3 "RESERVED" 4 "Limphome" 5 "0x5~0xFF:RESERVED" 255 "0x5~0xFF:RESERVED" ;
VAL_ 1345 NMSleepFlag_PSB 0 "Alive" 1 "SleepInd" 2 "RESERVED" 3 "SleepAck" ;
VAL_ 1323 Destination_SHVU_RR 0 "0x0x0~0xFF:NM Source Node ID" 255 "0x0x0~0xFF:NM Source Node ID" ;
VAL_ 1323 NMCommandCode_SHVU_RR 1 "Alive" 2 "Ring" 3 "RESERVED" 4 "Limphome" 5 "0x5~0xFF:RESERVED" 255 "0x5~0xFF:RESERVED" ;
VAL_ 1323 NMSleepFlag_SHVU_RR 0 "Alive" 1 "SleepInd" 2 "RESERVED" 3 "SleepAck" ;
VAL_ 1329 Destination_APSU 0 "0x0x0~0xFF:NM Source Node ID" 255 "0x0x0~0xFF:NM Source Node ID" ;
VAL_ 1329 NMCommandCode_APSU 1 "Alive" 2 "Ring" 3 "RESERVED" 4 "Limphome" 5 "0x5~0xFF:RESERVED" 255 "0x5~0xFF:RESERVED" ;
VAL_ 1329 NMSleepFlag_APSU 0 "Alive" 1 "SleepInd" 2 "RESERVED" 3 "SleepAck" ;
VAL_ 1313 Destination_FCS 0 "0x0x0~0xFF:NM Source Node ID" 255 "0x0x0~0xFF:NM Source Node ID" ;
VAL_ 1313 NMCommandCode_FCS 1 "Alive" 2 "Ring" 3 "RESERVED" 4 "Limphome" 5 "0x5~0xFF:RESERVED" 255 "0x5~0xFF:RESERVED" ;
VAL_ 1313 NMSleepFlag_FCS 0 "Alive" 1 "SleepInd" 2 "RESERVED" 3 "SleepAck" ;
VAL_ 1297 Destination_EMCU 0 "0x0x0~0xFF:NM Source Node ID" 255 "0x0x0~0xFF:NM Source Node ID" ;
VAL_ 1297 NMCommandCode_EMCU 1 "Alive" 2 "Ring" 3 "RESERVED" 4 "Limphome" 5 "0x5~0xFF:RESERVED" 255 "0x5~0xFF:RESERVED" ;
VAL_ 1297 NMSleepFlag_EMCU 0 "Alive" 1 "SleepInd" 2 "RESERVED" 3 "SleepAck" ;
VAL_ 1307 Destination_SLB 0 "0x0x0~0xFF:NM Source Node ID" 255 "0x0x0~0xFF:NM Source Node ID" ;
VAL_ 1307 NMCommandCode_SLB 1 "Alive" 2 "Ring" 3 "RESERVED" 4 "Limphome" 5 "0x5~0xFF:RESERVED" 255 "0x5~0xFF:RESERVED" ;
VAL_ 1307 NMSleepFlag_SLB 0 "Alive" 1 "SleepInd" 2 "RESERVED" 3 "SleepAck" ;
VAL_ 1341 Destination_RCM 0 "0x0x0~0xFF:NM Source Node ID" 255 "0x0x0~0xFF:NM Source Node ID" ;
VAL_ 1341 NMCommandCode_RCM 1 "Alive" 2 "Ring" 3 "RESERVED" 4 "Limphome" 5 "0x5~0xFF:RESERVED" 255 "0x5~0xFF:RESERVED" ;
VAL_ 1341 NMSleepFlag_RCM 0 "Alive" 1 "SleepInd" 2 "RESERVED" 3 "SleepAck" ;
VAL_ 1290 Destination_ARS 0 "0x0x0~0xFF:NM Source Node ID" 255 "0x0x0~0xFF:NM Source Node ID" ;
VAL_ 1290 NMCommandCode_ARS 1 "Alive" 2 "Ring" 3 "RESERVED" 4 "Limphome" 5 "0x5~0xFF:RESERVED" 255 "0x5~0xFF:RESERVED" ;
VAL_ 1290 NMSleepFlag_ARS 0 "Alive" 1 "SleepInd" 2 "RESERVED" 3 "SleepAck" ;
VAL_ 1392 Destination_CGW_CCU 0 "0x0x0~0xFF:NM Source Node ID" 255 "0x0x0~0xFF:NM Source Node ID" ;
VAL_ 1392 NMCommandCode_CGW_CCU 1 "Alive" 2 "Ring" 3 "RESERVED" 4 "Limphome" 5 "0x5~0xFF:RESERVED" 255 "0x5~0xFF:RESERVED" ;
VAL_ 1392 NMSleepFlag_CGW_CCU 0 "Alive" 1 "SleepInd" 2 "RESERVED" 3 "SleepAck" ;
VAL_ 1360 Destination_ATS 0 "0x0x0~0xFF:NM Source Node ID" 255 "0x0x0~0xFF:NM Source Node ID" ;
VAL_ 1360 NMCommandCode_ATS 1 "Alive" 2 "Ring" 3 "RESERVED" 4 "Limphome" 5 "0x5~0xFF:RESERVED" 255 "0x5~0xFF:RESERVED" ;
VAL_ 1360 NMSleepFlag_ATS 0 "Alive" 1 "SleepInd" 2 "RESERVED" 3 "SleepAck" ;
VAL_ 1332 Destination_RLHV 0 "0x0x0~0xFF:NM Source Node ID" 255 "0x0x0~0xFF:NM Source Node ID" ;
VAL_ 1332 NMCommandCode_RLHV 1 "Alive" 2 "Ring" 3 "RESERVED" 4 "Limphome" 5 "0x5~0xFF:RESERVED" 255 "0x5~0xFF:RESERVED" ;
VAL_ 1332 NMSleepFlag_RLHV 0 "Alive" 1 "SleepInd" 2 "RESERVED" 3 "SleepAck" ;
VAL_ 1342 Destination_SGU 0 "0x0x0~0xFF:NM Source Node ID" 255 "0x0x0~0xFF:NM Source Node ID" ;
VAL_ 1342 NMCommandCode_SGU 1 "Alive" 2 "Ring" 3 "RESERVED" 4 "Limphome" 5 "0x5~0xFF:RESERVED" 255 "0x5~0xFF:RESERVED" ;
VAL_ 1342 NMSleepFlag_SGU 0 "Alive" 1 "SleepInd" 2 "RESERVED" 3 "SleepAck" ;
VAL_ 1325 Destination_PFSU 0 "0x0x0~0xFF:NM Source Node ID" 255 "0x0x0~0xFF:NM Source Node ID" ;
VAL_ 1325 NMCommandCode_PFSU 1 "Alive" 2 "Ring" 3 "RESERVED" 4 "Limphome" 5 "0x5~0xFF:RESERVED" 255 "0x5~0xFF:RESERVED" ;
VAL_ 1325 NMSleepFlag_PFSU 0 "Alive" 1 "SleepInd" 2 "RESERVED" 3 "SleepAck" ;
VAL_ 1348 Destination_ALBCU 0 "0x0x0~0xFF:NM Source Node ID" 255 "0x0x0~0xFF:NM Source Node ID" ;
VAL_ 1348 NMCommandCode_ALBCU 1 "Alive" 2 "Ring" 3 "RESERVED" 4 "Limphome" 5 "0x5~0xFF:RESERVED" 255 "0x5~0xFF:RESERVED" ;
VAL_ 1348 NMSleepFlag_ALBCU 0 "Alive" 1 "SleepInd" 2 "RESERVED" 3 "SleepAck" ;
VAL_ 1369 Destination_DSAU 0 "0x0x0~0xFF:NM Source Node ID" 255 "0x0x0~0xFF:NM Source Node ID" ;
VAL_ 1369 NMCommandCode_DSAU 1 "Alive" 2 "Ring" 3 "RESERVED" 4 "Limphome" 5 "0x5~0xFF:RESERVED" 255 "0x5~0xFF:RESERVED" ;
VAL_ 1369 NMSleepFlag_DSAU 0 "Alive" 1 "SleepInd" 2 "RESERVED" 3 "SleepAck" ;
VAL_ 1288 Destination_SWRC 0 "0x0x0~0xFF:NM Source Node ID" 255 "0x0x0~0xFF:NM Source Node ID" ;
VAL_ 1288 NMCommandCode_SWRC 1 "Alive" 2 "Ring" 3 "RESERVED" 4 "Limphome" 5 "0x5~0xFF:RESERVED" 255 "0x5~0xFF:RESERVED" ;
VAL_ 1288 NMSleepFlag_SWRC 0 "Alive" 1 "SleepInd" 2 "RESERVED" 3 "SleepAck" ;
VAL_ 1322 Destination_SHVU_FR 0 "0x0x0~0xFF:NM Source Node ID" 255 "0x0x0~0xFF:NM Source Node ID" ;
VAL_ 1322 NMCommandCode_SHVU_FR 1 "Alive" 2 "Ring" 3 "RESERVED" 4 "Limphome" 5 "0x5~0xFF:RESERVED" 255 "0x5~0xFF:RESERVED" ;
VAL_ 1322 NMSleepFlag_SHVU_FR 0 "Alive" 1 "SleepInd" 2 "RESERVED" 3 "SleepAck" ;
VAL_ 1350 Destination_RCS 0 "0x0x0~0xFF:NM Source Node ID" 255 "0x0x0~0xFF:NM Source Node ID" ;
VAL_ 1350 NMCommandCode_RCS 1 "Alive" 2 "Ring" 3 "RESERVED" 4 "Limphome" 5 "0x5~0xFF:RESERVED" 255 "0x5~0xFF:RESERVED" ;
VAL_ 1350 NMSleepFlag_RCS 0 "Alive" 1 "SleepInd" 2 "RESERVED" 3 "SleepAck" ;
VAL_ 1309 Destination_RRPSU 0 "0x0x0~0xFF:NM Source Node ID" 255 "0x0x0~0xFF:NM Source Node ID" ;
VAL_ 1309 NMCommandCode_RRPSU 1 "Alive" 2 "Ring" 3 "RESERVED" 4 "Limphome" 5 "0x5~0xFF:RESERVED" 255 "0x5~0xFF:RESERVED" ;
VAL_ 1309 NMSleepFlag_RRPSU 0 "Alive" 1 "SleepInd" 2 "RESERVED" 3 "SleepAck" ;
VAL_ 1352 Destination_BLTN_CAM 0 "0x0x0~0xFF:NM Source Node ID" 255 "0x0x0~0xFF:NM Source Node ID" ;
VAL_ 1352 NMCommandCode_BLTN_CAM 1 "Alive" 2 "Ring" 3 "RESERVED" 4 "Limphome" 5 "0x5~0xFF:RESERVED" 255 "0x5~0xFF:RESERVED" ;
VAL_ 1352 NMSleepFlag_BLTN_CAM 0 "Alive" 1 "SleepInd" 2 "RESERVED" 3 "SleepAck" ;
VAL_ 1287 Destination_SCM 0 "0x0x0~0xFF:NM Source Node ID" 255 "0x0x0~0xFF:NM Source Node ID" ;
VAL_ 1287 NMCommandCode_SCM 1 "Alive" 2 "Ring" 3 "RESERVED" 4 "Limphome" 5 "0x5~0xFF:RESERVED" 255 "0x5~0xFF:RESERVED" ;
VAL_ 1287 NMSleepFlag_SCM 0 "Alive" 1 "SleepInd" 2 "RESERVED" 3 "SleepAck" ;
VAL_ 1344 Destination_DLBCU 0 "0x0x0~0xFF:NM Source Node ID" 255 "0x0x0~0xFF:NM Source Node ID" ;
VAL_ 1344 NMCommandCode_DLBCU 1 "Alive" 2 "Ring" 3 "RESERVED" 4 "Limphome" 5 "0x5~0xFF:RESERVED" 255 "0x5~0xFF:RESERVED" ;
VAL_ 1344 NMSleepFlag_DLBCU 0 "Alive" 1 "SleepInd" 2 "RESERVED" 3 "SleepAck" ;
VAL_ 1364 Destination_OHCL 0 "0x0x0~0xFF:NM Source Node ID" 255 "0x0x0~0xFF:NM Source Node ID" ;
VAL_ 1364 NMCommandCode_OHCL 1 "Alive" 2 "Ring" 3 "RESERVED" 4 "Limphome" 5 "0x5~0xFF:RESERVED" 255 "0x5~0xFF:RESERVED" ;
VAL_ 1364 NMSleepFlag_OHCL 0 "Alive" 1 "SleepInd" 2 "RESERVED" 3 "SleepAck" ;
VAL_ 1311 Destination_RWPC 0 "0x0x0~0xFF:NM Source Node ID" 255 "0x0x0~0xFF:NM Source Node ID" ;
VAL_ 1311 NMCommandCode_RWPC 1 "Alive" 2 "Ring" 3 "RESERVED" 4 "Limphome" 5 "0x5~0xFF:RESERVED" 255 "0x5~0xFF:RESERVED" ;
VAL_ 1311 NMSleepFlag_RWPC 0 "Alive" 1 "SleepInd" 2 "RESERVED" 3 "SleepAck" ;
VAL_ 1333 Destination_RRHV 0 "0x0x0~0xFF:NM Source Node ID" 255 "0x0x0~0xFF:NM Source Node ID" ;
VAL_ 1333 NMCommandCode_RRHV 1 "Alive" 2 "Ring" 3 "RESERVED" 4 "Limphome" 5 "0x5~0xFF:RESERVED" 255 "0x5~0xFF:RESERVED" ;
VAL_ 1333 NMSleepFlag_RRHV 0 "Alive" 1 "SleepInd" 2 "RESERVED" 3 "SleepAck" ;
VAL_ 1310 Destination_WPC 0 "0x0x0~0xFF:NM Source Node ID" 255 "0x0x0~0xFF:NM Source Node ID" ;
VAL_ 1310 NMCommandCode_WPC 1 "Alive" 2 "Ring" 3 "RESERVED" 4 "Limphome" 5 "0x5~0xFF:RESERVED" 255 "0x5~0xFF:RESERVED" ;
VAL_ 1310 NMSleepFlag_WPC 0 "Alive" 1 "SleepInd" 2 "RESERVED" 3 "SleepAck" ;
VAL_ 1354 Destination_HOD 0 "0x0x0~0xFF:NM Source Node ID" 255 "0x0x0~0xFF:NM Source Node ID" ;
VAL_ 1354 NMCommandCode_HOD 1 "Alive" 2 "Ring" 3 "RESERVED" 4 "Limphome" 5 "0x5~0xFF:RESERVED" 255 "0x5~0xFF:RESERVED" ;
VAL_ 1354 NMSleepFlag_HOD 0 "Alive" 1 "SleepInd" 2 "RESERVED" 3 "SleepAck" ;
VAL_ 1363 Destination_ASAU 0 "0x0x0~0xFF:NM Source Node ID" 255 "0x0x0~0xFF:NM Source Node ID" ;
VAL_ 1363 NMCommandCode_ASAU 1 "Alive" 2 "Ring" 3 "RESERVED" 4 "Limphome" 5 "0x5~0xFF:RESERVED" 255 "0x5~0xFF:RESERVED" ;
VAL_ 1363 NMSleepFlag_ASAU 0 "Alive" 1 "SleepInd" 2 "RESERVED" 3 "SleepAck" ;
